VERSION ""

NS_ :

BS_:

BU_: CVC_I MHU TBOX FCAM_I MRR SRR_RL SRR_RR SRR_FL SRR_FR DUMMY_ECU ADCU_I AMP HUD

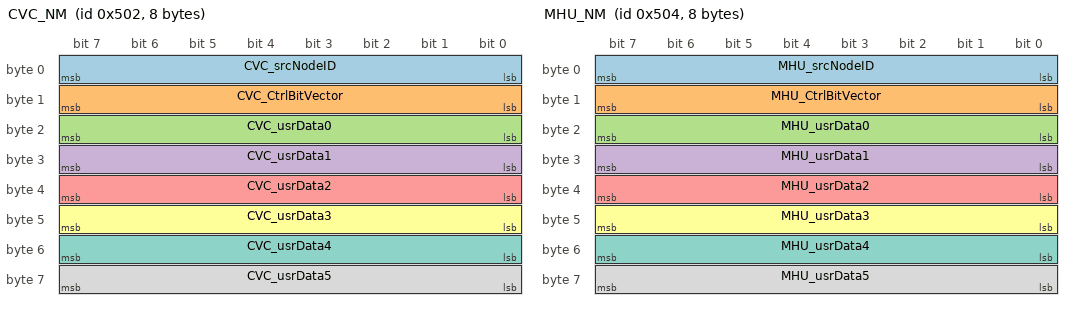
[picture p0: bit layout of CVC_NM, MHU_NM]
BO_ 1282 CVC_NM: 8 CVC_I
 SG_ CVC_srcNodeID : 7|8@0+ (1,0) [0|255] ""  MHU,TBOX,MRR,SRR_RL,SRR_RR,AMP
 SG_ CVC_CtrlBitVector : 15|8@0+ (1,0) [0|255] ""  MHU,TBOX,MRR,SRR_RL,SRR_RR,AMP
 SG_ CVC_usrData0 : 23|8@0+ (1,0) [0|255] ""  MHU,TBOX,MRR,SRR_RL,SRR_RR,AMP
 SG_ CVC_usrData1 : 31|8@0+ (1,0) [0|255] ""  MHU,TBOX,MRR,SRR_RL,SRR_RR,AMP
 SG_ CVC_usrData2 : 39|8@0+ (1,0) [0|255] ""  MHU,TBOX,MRR,SRR_RL,SRR_RR,AMP
 SG_ CVC_usrData3 : 47|8@0+ (1,0) [0|255] ""  MHU,TBOX,MRR,SRR_RL,SRR_RR,AMP
 SG_ CVC_usrData4 : 55|8@0+ (1,0) [0|255] ""  MHU,TBOX,MRR,SRR_RL,SRR_RR,AMP
 SG_ CVC_usrData5 : 63|8@0+ (1,0) [0|255] ""  MHU,TBOX,MRR,SRR_RL,SRR_RR,AMP

BO_ 1284 MHU_NM: 8 MHU
 SG_ MHU_srcNodeID : 7|8@0+ (1,0) [0|255] ""  CVC_I,TBOX,MRR,SRR_RL,SRR_RR,AMP
 SG_ MHU_CtrlBitVector : 15|8@0+ (1,0) [0|255] ""  CVC_I,TBOX,MRR,SRR_RL,SRR_RR,AMP
 SG_ MHU_usrData0 : 23|8@0+ (1,0) [0|255] ""  CVC_I,TBOX,MRR,SRR_RL,SRR_RR,AMP
 SG_ MHU_usrData1 : 31|8@0+ (1,0) [0|255] ""  CVC_I,TBOX,MRR,SRR_RL,SRR_RR,AMP
 SG_ MHU_usrData2 : 39|8@0+ (1,0) [0|255] ""  CVC_I,TBOX,MRR,SRR_RL,SRR_RR,AMP
 SG_ MHU_usrData3 : 47|8@0+ (1,0) [0|255] ""  CVC_I,TBOX,MRR,SRR_RL,SRR_RR,AMP
 SG_ MHU_usrData4 : 55|8@0+ (1,0) [0|255] ""  CVC_I,TBOX,MRR,SRR_RL,SRR_RR,AMP
 SG_ MHU_usrData5 : 63|8@0+ (1,0) [0|255] ""  CVC_I,TBOX,MRR,SRR_RL,SRR_RR,AMP

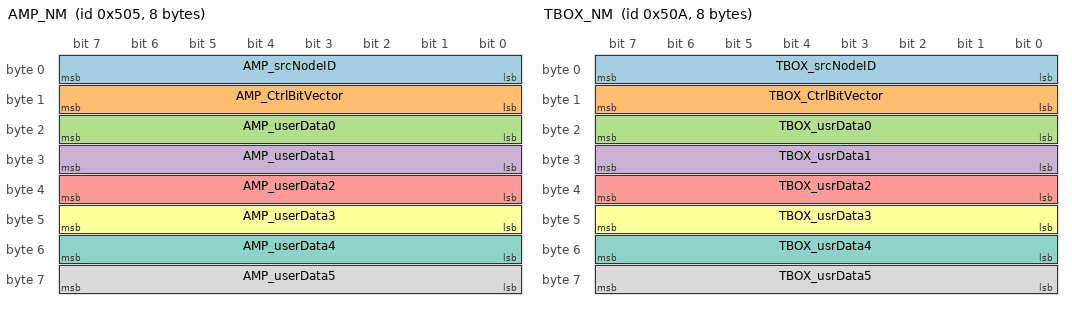
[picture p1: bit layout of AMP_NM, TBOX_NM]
BO_ 1285 AMP_NM: 8 AMP
 SG_ AMP_srcNodeID : 7|8@0+ (1,0) [0|255] ""  CVC_I,MHU,TBOX,MRR,SRR_RL,SRR_RR
 SG_ AMP_CtrlBitVector : 15|8@0+ (1,0) [0|255] ""  CVC_I,MHU,TBOX,MRR,SRR_RL,SRR_RR
 SG_ AMP_userData0 : 23|8@0+ (1,0) [0|255] ""  CVC_I,MHU,TBOX,MRR,SRR_RL,SRR_RR
 SG_ AMP_userData1 : 31|8@0+ (1,0) [0|255] ""  CVC_I,MHU,TBOX,MRR,SRR_RL,SRR_RR
 SG_ AMP_userData2 : 39|8@0+ (1,0) [0|255] ""  CVC_I,MHU,TBOX,MRR,SRR_RL,SRR_RR
 SG_ AMP_userData3 : 47|8@0+ (1,0) [0|255] ""  CVC_I,MHU,TBOX,MRR,SRR_RL,SRR_RR
 SG_ AMP_userData4 : 55|8@0+ (1,0) [0|255] ""  CVC_I,MHU,TBOX,MRR,SRR_RL,SRR_RR
 SG_ AMP_userData5 : 63|8@0+ (1,0) [0|255] ""  CVC_I,MHU,TBOX,MRR,SRR_RL,SRR_RR

BO_ 1290 TBOX_NM: 8 TBOX
 SG_ TBOX_srcNodeID : 7|8@0+ (1,0) [0|255] ""  CVC_I,MHU,MRR,SRR_RL,SRR_RR,AMP
 SG_ TBOX_CtrlBitVector : 15|8@0+ (1,0) [0|255] ""  CVC_I,MHU,MRR,SRR_RL,SRR_RR,AMP
 SG_ TBOX_usrData0 : 23|8@0+ (1,0) [0|255] ""  CVC_I,MHU,MRR,SRR_RL,SRR_RR,AMP
 SG_ TBOX_usrData1 : 31|8@0+ (1,0) [0|255] ""  CVC_I,MHU,MRR,SRR_RL,SRR_RR,AMP
 SG_ TBOX_usrData2 : 39|8@0+ (1,0) [0|255] ""  CVC_I,MHU,MRR,SRR_RL,SRR_RR,AMP
 SG_ TBOX_usrData3 : 47|8@0+ (1,0) [0|255] ""  CVC_I,MHU,MRR,SRR_RL,SRR_RR,AMP
 SG_ TBOX_usrData4 : 55|8@0+ (1,0) [0|255] ""  CVC_I,MHU,MRR,SRR_RL,SRR_RR,AMP
 SG_ TBOX_usrData5 : 63|8@0+ (1,0) [0|255] ""  CVC_I,MHU,MRR,SRR_RL,SRR_RR,AMP

BO_ 1674 TBOX_DiagReq: 64 CVC_I
 SG_ TBOX_DiagReqData0 : 7|8@0+ (1,0) [0|255] ""  TBOX
 SG_ TBOX_DiagReqData1 : 15|8@0+ (1,0) [0|255] ""  TBOX
 SG_ TBOX_DiagReqData2 : 23|8@0+ (1,0) [0|255] ""  TBOX
 SG_ TBOX_DiagReqData3 : 31|8@0+ (1,0) [0|255] ""  TBOX
 SG_ TBOX_DiagReqData4 : 39|8@0+ (1,0) [0|255] ""  TBOX
 SG_ TBOX_DiagReqData5 : 47|8@0+ (1,0) [0|255] ""  TBOX
 SG_ TBOX_DiagReqData6 : 55|8@0+ (1,0) [0|255] ""  TBOX
 SG_ TBOX_DiagReqData7 : 63|8@0+ (1,0) [0|255] ""  TBOX
 SG_ TBOX_DiagReqData8 : 71|8@0+ (1,0) [0|255] ""  TBOX
 SG_ TBOX_DiagReqData9 : 79|8@0+ (1,0) [0|255] ""  TBOX
 SG_ TBOX_DiagReqData10 : 87|8@0+ (1,0) [0|255] ""  TBOX
 SG_ TBOX_DiagReqData11 : 95|8@0+ (1,0) [0|255] ""  TBOX
 SG_ TBOX_DiagReqData12 : 103|8@0+ (1,0) [0|255] ""  TBOX
 SG_ TBOX_DiagReqData13 : 111|8@0+ (1,0) [0|255] ""  TBOX
 SG_ TBOX_DiagReqData14 : 119|8@0+ (1,0) [0|255] ""  TBOX
 SG_ TBOX_DiagReqData15 : 127|8@0+ (1,0) [0|255] ""  TBOX
 SG_ TBOX_DiagReqData16 : 135|8@0+ (1,0) [0|255] ""  TBOX
 SG_ TBOX_DiagReqData17 : 143|8@0+ (1,0) [0|255] ""  TBOX
 SG_ TBOX_DiagReqData18 : 151|8@0+ (1,0) [0|255] ""  TBOX
 SG_ TBOX_DiagReqData19 : 159|8@0+ (1,0) [0|255] ""  TBOX
 SG_ TBOX_DiagReqData20 : 167|8@0+ (1,0) [0|255] ""  TBOX
 SG_ TBOX_DiagReqData21 : 175|8@0+ (1,0) [0|255] ""  TBOX
 SG_ TBOX_DiagReqData22 : 183|8@0+ (1,0) [0|255] ""  TBOX
 SG_ TBOX_DiagReqData23 : 191|8@0+ (1,0) [0|255] ""  TBOX
 SG_ TBOX_DiagReqData24 : 199|8@0+ (1,0) [0|255] ""  TBOX
 SG_ TBOX_DiagReqData25 : 207|8@0+ (1,0) [0|255] ""  TBOX
 SG_ TBOX_DiagReqData26 : 215|8@0+ (1,0) [0|255] ""  TBOX
 SG_ TBOX_DiagReqData27 : 223|8@0+ (1,0) [0|255] ""  TBOX
 SG_ TBOX_DiagReqData28 : 231|8@0+ (1,0) [0|255] ""  TBOX
 SG_ TBOX_DiagReqData29 : 239|8@0+ (1,0) [0|255] ""  TBOX
 SG_ TBOX_DiagReqData30 : 247|8@0+ (1,0) [0|255] ""  TBOX
 SG_ TBOX_DiagReqData31 : 255|8@0+ (1,0) [0|255] ""  TBOX
 SG_ TBOX_DiagReqData32 : 263|8@0+ (1,0) [0|255] ""  TBOX
 SG_ TBOX_DiagReqData33 : 271|8@0+ (1,0) [0|255] ""  TBOX
 SG_ TBOX_DiagReqData34 : 279|8@0+ (1,0) [0|255] ""  TBOX
 SG_ TBOX_DiagReqData35 : 287|8@0+ (1,0) [0|255] ""  TBOX
 SG_ TBOX_DiagReqData36 : 295|8@0+ (1,0) [0|255] ""  TBOX
 SG_ TBOX_DiagReqData37 : 303|8@0+ (1,0) [0|255] ""  TBOX
 SG_ TBOX_DiagReqData38 : 311|8@0+ (1,0) [0|255] ""  TBOX
 SG_ TBOX_DiagReqData39 : 319|8@0+ (1,0) [0|255] ""  TBOX
 SG_ TBOX_DiagReqData40 : 327|8@0+ (1,0) [0|255] ""  TBOX
 SG_ TBOX_DiagReqData41 : 335|8@0+ (1,0) [0|255] ""  TBOX
 SG_ TBOX_DiagReqData42 : 343|8@0+ (1,0) [0|255] ""  TBOX
 SG_ TBOX_DiagReqData43 : 351|8@0+ (1,0) [0|255] ""  TBOX
 SG_ TBOX_DiagReqData44 : 359|8@0+ (1,0) [0|255] ""  TBOX
 SG_ TBOX_DiagReqData45 : 367|8@0+ (1,0) [0|255] ""  TBOX
 SG_ TBOX_DiagReqData46 : 375|8@0+ (1,0) [0|255] ""  TBOX
 SG_ TBOX_DiagReqData47 : 383|8@0+ (1,0) [0|255] ""  TBOX
 SG_ TBOX_DiagReqData48 : 391|8@0+ (1,0) [0|255] ""  TBOX
 SG_ TBOX_DiagReqData49 : 399|8@0+ (1,0) [0|255] ""  TBOX
 SG_ TBOX_DiagReqData50 : 407|8@0+ (1,0) [0|255] ""  TBOX
 SG_ TBOX_DiagReqData51 : 415|8@0+ (1,0) [0|255] ""  TBOX
 SG_ TBOX_DiagReqData52 : 423|8@0+ (1,0) [0|255] ""  TBOX
 SG_ TBOX_DiagReqData53 : 431|8@0+ (1,0) [0|255] ""  TBOX
 SG_ TBOX_DiagReqData54 : 439|8@0+ (1,0) [0|255] ""  TBOX
 SG_ TBOX_DiagReqData55 : 447|8@0+ (1,0) [0|255] ""  TBOX
 SG_ TBOX_DiagReqData56 : 455|8@0+ (1,0) [0|255] ""  TBOX
 SG_ TBOX_DiagReqData57 : 463|8@0+ (1,0) [0|255] ""  TBOX
 SG_ TBOX_DiagReqData58 : 471|8@0+ (1,0) [0|255] ""  TBOX
 SG_ TBOX_DiagReqData59 : 479|8@0+ (1,0) [0|255] ""  TBOX
 SG_ TBOX_DiagReqData60 : 487|8@0+ (1,0) [0|255] ""  TBOX
 SG_ TBOX_DiagReqData61 : 495|8@0+ (1,0) [0|255] ""  TBOX
 SG_ TBOX_DiagReqData62 : 503|8@0+ (1,0) [0|255] ""  TBOX
 SG_ TBOX_DiagReqData63 : 511|8@0+ (1,0) [0|255] ""  TBOX

BO_ 1546 TBOX_DiagResp: 64 TBOX
 SG_ TBOX_DiagRespData0 : 7|8@0+ (1,0) [0|255] ""  CVC_I
 SG_ TBOX_DiagRespData1 : 15|8@0+ (1,0) [0|255] ""  CVC_I
 SG_ TBOX_DiagRespData2 : 23|8@0+ (1,0) [0|255] ""  CVC_I
 SG_ TBOX_DiagRespData3 : 31|8@0+ (1,0) [0|255] ""  CVC_I
 SG_ TBOX_DiagRespData4 : 39|8@0+ (1,0) [0|255] ""  CVC_I
 SG_ TBOX_DiagRespData5 : 47|8@0+ (1,0) [0|255] ""  CVC_I
 SG_ TBOX_DiagRespData6 : 55|8@0+ (1,0) [0|255] ""  CVC_I
 SG_ TBOX_DiagRespData7 : 63|8@0+ (1,0) [0|255] ""  CVC_I
 SG_ TBOX_DiagRespData8 : 71|8@0+ (1,0) [0|255] ""  CVC_I
 SG_ TBOX_DiagRespData9 : 79|8@0+ (1,0) [0|255] ""  CVC_I
 SG_ TBOX_DiagRespData10 : 87|8@0+ (1,0) [0|255] ""  CVC_I
 SG_ TBOX_DiagRespData11 : 95|8@0+ (1,0) [0|255] ""  CVC_I
 SG_ TBOX_DiagRespData12 : 103|8@0+ (1,0) [0|255] ""  CVC_I
 SG_ TBOX_DiagRespData13 : 111|8@0+ (1,0) [0|255] ""  CVC_I
 SG_ TBOX_DiagRespData14 : 119|8@0+ (1,0) [0|255] ""  CVC_I
 SG_ TBOX_DiagRespData15 : 127|8@0+ (1,0) [0|255] ""  CVC_I
 SG_ TBOX_DiagRespData16 : 135|8@0+ (1,0) [0|255] ""  CVC_I
 SG_ TBOX_DiagRespData17 : 143|8@0+ (1,0) [0|255] ""  CVC_I
 SG_ TBOX_DiagRespData18 : 151|8@0+ (1,0) [0|255] ""  CVC_I
 SG_ TBOX_DiagRespData19 : 159|8@0+ (1,0) [0|255] ""  CVC_I
 SG_ TBOX_DiagRespData20 : 167|8@0+ (1,0) [0|255] ""  CVC_I
 SG_ TBOX_DiagRespData21 : 175|8@0+ (1,0) [0|255] ""  CVC_I
 SG_ TBOX_DiagRespData22 : 183|8@0+ (1,0) [0|255] ""  CVC_I
 SG_ TBOX_DiagRespData23 : 191|8@0+ (1,0) [0|255] ""  CVC_I
 SG_ TBOX_DiagRespData24 : 199|8@0+ (1,0) [0|255] ""  CVC_I
 SG_ TBOX_DiagRespData25 : 207|8@0+ (1,0) [0|255] ""  CVC_I
 SG_ TBOX_DiagRespData26 : 215|8@0+ (1,0) [0|255] ""  CVC_I
 SG_ TBOX_DiagRespData27 : 223|8@0+ (1,0) [0|255] ""  CVC_I
 SG_ TBOX_DiagRespData28 : 231|8@0+ (1,0) [0|255] ""  CVC_I
 SG_ TBOX_DiagRespData29 : 239|8@0+ (1,0) [0|255] ""  CVC_I
 SG_ TBOX_DiagRespData30 : 247|8@0+ (1,0) [0|255] ""  CVC_I
 SG_ TBOX_DiagRespData31 : 255|8@0+ (1,0) [0|255] ""  CVC_I
 SG_ TBOX_DiagRespData32 : 263|8@0+ (1,0) [0|255] ""  CVC_I
 SG_ TBOX_DiagRespData33 : 271|8@0+ (1,0) [0|255] ""  CVC_I
 SG_ TBOX_DiagRespData34 : 279|8@0+ (1,0) [0|255] ""  CVC_I
 SG_ TBOX_DiagRespData35 : 287|8@0+ (1,0) [0|255] ""  CVC_I
 SG_ TBOX_DiagRespData36 : 295|8@0+ (1,0) [0|255] ""  CVC_I
 SG_ TBOX_DiagRespData37 : 303|8@0+ (1,0) [0|255] ""  CVC_I
 SG_ TBOX_DiagRespData38 : 311|8@0+ (1,0) [0|255] ""  CVC_I
 SG_ TBOX_DiagRespData39 : 319|8@0+ (1,0) [0|255] ""  CVC_I
 SG_ TBOX_DiagRespData40 : 327|8@0+ (1,0) [0|255] ""  CVC_I
 SG_ TBOX_DiagRespData41 : 335|8@0+ (1,0) [0|255] ""  CVC_I
 SG_ TBOX_DiagRespData42 : 343|8@0+ (1,0) [0|255] ""  CVC_I
 SG_ TBOX_DiagRespData43 : 351|8@0+ (1,0) [0|255] ""  CVC_I
 SG_ TBOX_DiagRespData44 : 359|8@0+ (1,0) [0|255] ""  CVC_I
 SG_ TBOX_DiagRespData45 : 367|8@0+ (1,0) [0|255] ""  CVC_I
 SG_ TBOX_DiagRespData46 : 375|8@0+ (1,0) [0|255] ""  CVC_I
 SG_ TBOX_DiagRespData47 : 383|8@0+ (1,0) [0|255] ""  CVC_I
 SG_ TBOX_DiagRespData48 : 391|8@0+ (1,0) [0|255] ""  CVC_I
 SG_ TBOX_DiagRespData49 : 399|8@0+ (1,0) [0|255] ""  CVC_I
 SG_ TBOX_DiagRespData50 : 407|8@0+ (1,0) [0|255] ""  CVC_I
 SG_ TBOX_DiagRespData51 : 415|8@0+ (1,0) [0|255] ""  CVC_I
 SG_ TBOX_DiagRespData52 : 423|8@0+ (1,0) [0|255] ""  CVC_I
 SG_ TBOX_DiagRespData53 : 431|8@0+ (1,0) [0|255] ""  CVC_I
 SG_ TBOX_DiagRespData54 : 439|8@0+ (1,0) [0|255] ""  CVC_I
 SG_ TBOX_DiagRespData55 : 447|8@0+ (1,0) [0|255] ""  CVC_I
 SG_ TBOX_DiagRespData56 : 455|8@0+ (1,0) [0|255] ""  CVC_I
 SG_ TBOX_DiagRespData57 : 463|8@0+ (1,0) [0|255] ""  CVC_I
 SG_ TBOX_DiagRespData58 : 471|8@0+ (1,0) [0|255] ""  CVC_I
 SG_ TBOX_DiagRespData59 : 479|8@0+ (1,0) [0|255] ""  CVC_I
 SG_ TBOX_DiagRespData60 : 487|8@0+ (1,0) [0|255] ""  CVC_I
 SG_ TBOX_DiagRespData61 : 495|8@0+ (1,0) [0|255] ""  CVC_I
 SG_ TBOX_DiagRespData62 : 503|8@0+ (1,0) [0|255] ""  CVC_I
 SG_ TBOX_DiagRespData63 : 511|8@0+ (1,0) [0|255] ""  CVC_I

BO_ 1541 AMP_DiagResp: 64 AMP
 SG_ AMP_DiagRespData0 : 7|8@0+ (1,0) [0|255] ""  CVC_I
 SG_ AMP_DiagRespData1 : 15|8@0+ (1,0) [0|255] ""  CVC_I
 SG_ AMP_DiagRespData2 : 23|8@0+ (1,0) [0|255] ""  CVC_I
 SG_ AMP_DiagRespData3 : 31|8@0+ (1,0) [0|255] ""  CVC_I
 SG_ AMP_DiagRespData4 : 39|8@0+ (1,0) [0|255] ""  CVC_I
 SG_ AMP_DiagRespData5 : 47|8@0+ (1,0) [0|255] ""  CVC_I
 SG_ AMP_DiagRespData6 : 55|8@0+ (1,0) [0|255] ""  CVC_I
 SG_ AMP_DiagRespData7 : 63|8@0+ (1,0) [0|255] ""  CVC_I
 SG_ AMP_DiagRespData8 : 71|8@0+ (1,0) [0|255] ""  CVC_I
 SG_ AMP_DiagRespData9 : 79|8@0+ (1,0) [0|255] ""  CVC_I
 SG_ AMP_DiagRespData10 : 87|8@0+ (1,0) [0|255] ""  CVC_I
 SG_ AMP_DiagRespData11 : 95|8@0+ (1,0) [0|255] ""  CVC_I
 SG_ AMP_DiagRespData12 : 103|8@0+ (1,0) [0|255] ""  CVC_I
 SG_ AMP_DiagRespData13 : 111|8@0+ (1,0) [0|255] ""  CVC_I
 SG_ AMP_DiagRespData14 : 119|8@0+ (1,0) [0|255] ""  CVC_I
 SG_ AMP_DiagRespData15 : 127|8@0+ (1,0) [0|255] ""  CVC_I
 SG_ AMP_DiagRespData16 : 135|8@0+ (1,0) [0|255] ""  CVC_I
 SG_ AMP_DiagRespData17 : 143|8@0+ (1,0) [0|255] ""  CVC_I
 SG_ AMP_DiagRespData18 : 151|8@0+ (1,0) [0|255] ""  CVC_I
 SG_ AMP_DiagRespData19 : 159|8@0+ (1,0) [0|255] ""  CVC_I
 SG_ AMP_DiagRespData20 : 167|8@0+ (1,0) [0|255] ""  CVC_I
 SG_ AMP_DiagRespData21 : 175|8@0+ (1,0) [0|255] ""  CVC_I
 SG_ AMP_DiagRespData22 : 183|8@0+ (1,0) [0|255] ""  CVC_I
 SG_ AMP_DiagRespData23 : 191|8@0+ (1,0) [0|255] ""  CVC_I
 SG_ AMP_DiagRespData24 : 199|8@0+ (1,0) [0|255] ""  CVC_I
 SG_ AMP_DiagRespData25 : 207|8@0+ (1,0) [0|255] ""  CVC_I
 SG_ AMP_DiagRespData26 : 215|8@0+ (1,0) [0|255] ""  CVC_I
 SG_ AMP_DiagRespData27 : 223|8@0+ (1,0) [0|255] ""  CVC_I
 SG_ AMP_DiagRespData28 : 231|8@0+ (1,0) [0|255] ""  CVC_I
 SG_ AMP_DiagRespData29 : 239|8@0+ (1,0) [0|255] ""  CVC_I
 SG_ AMP_DiagRespData30 : 247|8@0+ (1,0) [0|255] ""  CVC_I
 SG_ AMP_DiagRespData31 : 255|8@0+ (1,0) [0|255] ""  CVC_I
 SG_ AMP_DiagRespData32 : 263|8@0+ (1,0) [0|255] ""  CVC_I
 SG_ AMP_DiagRespData33 : 271|8@0+ (1,0) [0|255] ""  CVC_I
 SG_ AMP_DiagRespData34 : 279|8@0+ (1,0) [0|255] ""  CVC_I
 SG_ AMP_DiagRespData35 : 287|8@0+ (1,0) [0|255] ""  CVC_I
 SG_ AMP_DiagRespData36 : 295|8@0+ (1,0) [0|255] ""  CVC_I
 SG_ AMP_DiagRespData37 : 303|8@0+ (1,0) [0|255] ""  CVC_I
 SG_ AMP_DiagRespData38 : 311|8@0+ (1,0) [0|255] ""  CVC_I
 SG_ AMP_DiagRespData39 : 319|8@0+ (1,0) [0|255] ""  CVC_I
 SG_ AMP_DiagRespData40 : 327|8@0+ (1,0) [0|255] ""  CVC_I
 SG_ AMP_DiagRespData41 : 335|8@0+ (1,0) [0|255] ""  CVC_I
 SG_ AMP_DiagRespData42 : 343|8@0+ (1,0) [0|255] ""  CVC_I
 SG_ AMP_DiagRespData43 : 351|8@0+ (1,0) [0|255] ""  CVC_I
 SG_ AMP_DiagRespData44 : 359|8@0+ (1,0) [0|255] ""  CVC_I
 SG_ AMP_DiagRespData45 : 367|8@0+ (1,0) [0|255] ""  CVC_I
 SG_ AMP_DiagRespData46 : 375|8@0+ (1,0) [0|255] ""  CVC_I
 SG_ AMP_DiagRespData47 : 383|8@0+ (1,0) [0|255] ""  CVC_I
 SG_ AMP_DiagRespData48 : 391|8@0+ (1,0) [0|255] ""  CVC_I
 SG_ AMP_DiagRespData49 : 399|8@0+ (1,0) [0|255] ""  CVC_I
 SG_ AMP_DiagRespData50 : 407|8@0+ (1,0) [0|255] ""  CVC_I
 SG_ AMP_DiagRespData51 : 415|8@0+ (1,0) [0|255] ""  CVC_I
 SG_ AMP_DiagRespData52 : 423|8@0+ (1,0) [0|255] ""  CVC_I
 SG_ AMP_DiagRespData53 : 431|8@0+ (1,0) [0|255] ""  CVC_I
 SG_ AMP_DiagRespData54 : 439|8@0+ (1,0) [0|255] ""  CVC_I
 SG_ AMP_DiagRespData55 : 447|8@0+ (1,0) [0|255] ""  CVC_I
 SG_ AMP_DiagRespData56 : 455|8@0+ (1,0) [0|255] ""  CVC_I
 SG_ AMP_DiagRespData57 : 463|8@0+ (1,0) [0|255] ""  CVC_I
 SG_ AMP_DiagRespData58 : 471|8@0+ (1,0) [0|255] ""  CVC_I
 SG_ AMP_DiagRespData59 : 479|8@0+ (1,0) [0|255] ""  CVC_I
 SG_ AMP_DiagRespData60 : 487|8@0+ (1,0) [0|255] ""  CVC_I
 SG_ AMP_DiagRespData61 : 495|8@0+ (1,0) [0|255] ""  CVC_I
 SG_ AMP_DiagRespData62 : 503|8@0+ (1,0) [0|255] ""  CVC_I
 SG_ AMP_DiagRespData63 : 511|8@0+ (1,0) [0|255] ""  CVC_I

BO_ 1669 AMP_DiagReq: 64 CVC_I
 SG_ AMP_DiagReqData0 : 7|8@0+ (1,0) [0|255] ""  AMP
 SG_ AMP_DiagReqData1 : 15|8@0+ (1,0) [0|255] ""  AMP
 SG_ AMP_DiagReqData2 : 23|8@0+ (1,0) [0|255] ""  AMP
 SG_ AMP_DiagReqData3 : 31|8@0+ (1,0) [0|255] ""  AMP
 SG_ AMP_DiagReqData4 : 39|8@0+ (1,0) [0|255] ""  AMP
 SG_ AMP_DiagReqData5 : 47|8@0+ (1,0) [0|255] ""  AMP
 SG_ AMP_DiagReqData6 : 55|8@0+ (1,0) [0|255] ""  AMP
 SG_ AMP_DiagReqData7 : 63|8@0+ (1,0) [0|255] ""  AMP
 SG_ AMP_DiagReqData8 : 71|8@0+ (1,0) [0|255] ""  AMP
 SG_ AMP_DiagReqData9 : 79|8@0+ (1,0) [0|255] ""  AMP
 SG_ AMP_DiagReqData10 : 87|8@0+ (1,0) [0|255] ""  AMP
 SG_ AMP_DiagReqData11 : 95|8@0+ (1,0) [0|255] ""  AMP
 SG_ AMP_DiagReqData12 : 103|8@0+ (1,0) [0|255] ""  AMP
 SG_ AMP_DiagReqData13 : 111|8@0+ (1,0) [0|255] ""  AMP
 SG_ AMP_DiagReqData14 : 119|8@0+ (1,0) [0|255] ""  AMP
 SG_ AMP_DiagReqData15 : 127|8@0+ (1,0) [0|255] ""  AMP
 SG_ AMP_DiagReqData16 : 135|8@0+ (1,0) [0|255] ""  AMP
 SG_ AMP_DiagReqData17 : 143|8@0+ (1,0) [0|255] ""  AMP
 SG_ AMP_DiagReqData18 : 151|8@0+ (1,0) [0|255] ""  AMP
 SG_ AMP_DiagReqData19 : 159|8@0+ (1,0) [0|255] ""  AMP
 SG_ AMP_DiagReqData20 : 167|8@0+ (1,0) [0|255] ""  AMP
 SG_ AMP_DiagReqData21 : 175|8@0+ (1,0) [0|255] ""  AMP
 SG_ AMP_DiagReqData22 : 183|8@0+ (1,0) [0|255] ""  AMP
 SG_ AMP_DiagReqData23 : 191|8@0+ (1,0) [0|255] ""  AMP
 SG_ AMP_DiagReqData24 : 199|8@0+ (1,0) [0|255] ""  AMP
 SG_ AMP_DiagReqData25 : 207|8@0+ (1,0) [0|255] ""  AMP
 SG_ AMP_DiagReqData26 : 215|8@0+ (1,0) [0|255] ""  AMP
 SG_ AMP_DiagReqData27 : 223|8@0+ (1,0) [0|255] ""  AMP
 SG_ AMP_DiagReqData28 : 231|8@0+ (1,0) [0|255] ""  AMP
 SG_ AMP_DiagReqData29 : 239|8@0+ (1,0) [0|255] ""  AMP
 SG_ AMP_DiagReqData30 : 247|8@0+ (1,0) [0|255] ""  AMP
 SG_ AMP_DiagReqData31 : 255|8@0+ (1,0) [0|255] ""  AMP
 SG_ AMP_DiagReqData32 : 263|8@0+ (1,0) [0|255] ""  AMP
 SG_ AMP_DiagReqData33 : 271|8@0+ (1,0) [0|255] ""  AMP
 SG_ AMP_DiagReqData34 : 279|8@0+ (1,0) [0|255] ""  AMP
 SG_ AMP_DiagReqData35 : 287|8@0+ (1,0) [0|255] ""  AMP
 SG_ AMP_DiagReqData36 : 295|8@0+ (1,0) [0|255] ""  AMP
 SG_ AMP_DiagReqData37 : 303|8@0+ (1,0) [0|255] ""  AMP
 SG_ AMP_DiagReqData38 : 311|8@0+ (1,0) [0|255] ""  AMP
 SG_ AMP_DiagReqData39 : 319|8@0+ (1,0) [0|255] ""  AMP
 SG_ AMP_DiagReqData40 : 327|8@0+ (1,0) [0|255] ""  AMP
 SG_ AMP_DiagReqData41 : 335|8@0+ (1,0) [0|255] ""  AMP
 SG_ AMP_DiagReqData42 : 343|8@0+ (1,0) [0|255] ""  AMP
 SG_ AMP_DiagReqData43 : 351|8@0+ (1,0) [0|255] ""  AMP
 SG_ AMP_DiagReqData44 : 359|8@0+ (1,0) [0|255] ""  AMP
 SG_ AMP_DiagReqData45 : 367|8@0+ (1,0) [0|255] ""  AMP
 SG_ AMP_DiagReqData46 : 375|8@0+ (1,0) [0|255] ""  AMP
 SG_ AMP_DiagReqData47 : 383|8@0+ (1,0) [0|255] ""  AMP
 SG_ AMP_DiagReqData48 : 391|8@0+ (1,0) [0|255] ""  AMP
 SG_ AMP_DiagReqData49 : 399|8@0+ (1,0) [0|255] ""  AMP
 SG_ AMP_DiagReqData50 : 407|8@0+ (1,0) [0|255] ""  AMP
 SG_ AMP_DiagReqData51 : 415|8@0+ (1,0) [0|255] ""  AMP
 SG_ AMP_DiagReqData52 : 423|8@0+ (1,0) [0|255] ""  AMP
 SG_ AMP_DiagReqData53 : 431|8@0+ (1,0) [0|255] ""  AMP
 SG_ AMP_DiagReqData54 : 439|8@0+ (1,0) [0|255] ""  AMP
 SG_ AMP_DiagReqData55 : 447|8@0+ (1,0) [0|255] ""  AMP
 SG_ AMP_DiagReqData56 : 455|8@0+ (1,0) [0|255] ""  AMP
 SG_ AMP_DiagReqData57 : 463|8@0+ (1,0) [0|255] ""  AMP
 SG_ AMP_DiagReqData58 : 471|8@0+ (1,0) [0|255] ""  AMP
 SG_ AMP_DiagReqData59 : 479|8@0+ (1,0) [0|255] ""  AMP
 SG_ AMP_DiagReqData60 : 487|8@0+ (1,0) [0|255] ""  AMP
 SG_ AMP_DiagReqData61 : 495|8@0+ (1,0) [0|255] ""  AMP
 SG_ AMP_DiagReqData62 : 503|8@0+ (1,0) [0|255] ""  AMP
 SG_ AMP_DiagReqData63 : 511|8@0+ (1,0) [0|255] ""  AMP

BO_ 1549 HUD_DiagResp: 64 HUD
 SG_ HUD_DiagRespData0 : 7|8@0+ (1,0) [0|255] ""  CVC_I
 SG_ HUD_DiagRespData1 : 15|8@0+ (1,0) [0|255] ""  CVC_I
 SG_ HUD_DiagRespData2 : 23|8@0+ (1,0) [0|255] ""  CVC_I
 SG_ HUD_DiagRespData3 : 31|8@0+ (1,0) [0|255] ""  CVC_I
 SG_ HUD_DiagRespData4 : 39|8@0+ (1,0) [0|255] ""  CVC_I
 SG_ HUD_DiagRespData5 : 47|8@0+ (1,0) [0|255] ""  CVC_I
 SG_ HUD_DiagRespData6 : 55|8@0+ (1,0) [0|255] ""  CVC_I
 SG_ HUD_DiagRespData7 : 63|8@0+ (1,0) [0|255] ""  CVC_I
 SG_ HUD_DiagRespData8 : 71|8@0+ (1,0) [0|255] ""  CVC_I
 SG_ HUD_DiagRespData9 : 79|8@0+ (1,0) [0|255] ""  CVC_I
 SG_ HUD_DiagRespData10 : 87|8@0+ (1,0) [0|255] ""  CVC_I
 SG_ HUD_DiagRespData11 : 95|8@0+ (1,0) [0|255] ""  CVC_I
 SG_ HUD_DiagRespData12 : 103|8@0+ (1,0) [0|255] ""  CVC_I
 SG_ HUD_DiagRespData13 : 111|8@0+ (1,0) [0|255] ""  CVC_I
 SG_ HUD_DiagRespData14 : 119|8@0+ (1,0) [0|255] ""  CVC_I
 SG_ HUD_DiagRespData15 : 127|8@0+ (1,0) [0|255] ""  CVC_I
 SG_ HUD_DiagRespData16 : 135|8@0+ (1,0) [0|255] ""  CVC_I
 SG_ HUD_DiagRespData17 : 143|8@0+ (1,0) [0|255] ""  CVC_I
 SG_ HUD_DiagRespData18 : 151|8@0+ (1,0) [0|255] ""  CVC_I
 SG_ HUD_DiagRespData19 : 159|8@0+ (1,0) [0|255] ""  CVC_I
 SG_ HUD_DiagRespData20 : 167|8@0+ (1,0) [0|255] ""  CVC_I
 SG_ HUD_DiagRespData21 : 175|8@0+ (1,0) [0|255] ""  CVC_I
 SG_ HUD_DiagRespData22 : 183|8@0+ (1,0) [0|255] ""  CVC_I
 SG_ HUD_DiagRespData23 : 191|8@0+ (1,0) [0|255] ""  CVC_I
 SG_ HUD_DiagRespData24 : 199|8@0+ (1,0) [0|255] ""  CVC_I
 SG_ HUD_DiagRespData25 : 207|8@0+ (1,0) [0|255] ""  CVC_I
 SG_ HUD_DiagRespData26 : 215|8@0+ (1,0) [0|255] ""  CVC_I
 SG_ HUD_DiagRespData27 : 223|8@0+ (1,0) [0|255] ""  CVC_I
 SG_ HUD_DiagRespData28 : 231|8@0+ (1,0) [0|255] ""  CVC_I
 SG_ HUD_DiagRespData29 : 239|8@0+ (1,0) [0|255] ""  CVC_I
 SG_ HUD_DiagRespData30 : 247|8@0+ (1,0) [0|255] ""  CVC_I
 SG_ HUD_DiagRespData31 : 255|8@0+ (1,0) [0|255] ""  CVC_I
 SG_ HUD_DiagRespData32 : 263|8@0+ (1,0) [0|255] ""  CVC_I
 SG_ HUD_DiagRespData33 : 271|8@0+ (1,0) [0|255] ""  CVC_I
 SG_ HUD_DiagRespData34 : 279|8@0+ (1,0) [0|255] ""  CVC_I
 SG_ HUD_DiagRespData35 : 287|8@0+ (1,0) [0|255] ""  CVC_I
 SG_ HUD_DiagRespData36 : 295|8@0+ (1,0) [0|255] ""  CVC_I
 SG_ HUD_DiagRespData37 : 303|8@0+ (1,0) [0|255] ""  CVC_I
 SG_ HUD_DiagRespData38 : 311|8@0+ (1,0) [0|255] ""  CVC_I
 SG_ HUD_DiagRespData39 : 319|8@0+ (1,0) [0|255] ""  CVC_I
 SG_ HUD_DiagRespData40 : 327|8@0+ (1,0) [0|255] ""  CVC_I
 SG_ HUD_DiagRespData41 : 335|8@0+ (1,0) [0|255] ""  CVC_I
 SG_ HUD_DiagRespData42 : 343|8@0+ (1,0) [0|255] ""  CVC_I
 SG_ HUD_DiagRespData43 : 351|8@0+ (1,0) [0|255] ""  CVC_I
 SG_ HUD_DiagRespData44 : 359|8@0+ (1,0) [0|255] ""  CVC_I
 SG_ HUD_DiagRespData45 : 367|8@0+ (1,0) [0|255] ""  CVC_I
 SG_ HUD_DiagRespData46 : 375|8@0+ (1,0) [0|255] ""  CVC_I
 SG_ HUD_DiagRespData47 : 383|8@0+ (1,0) [0|255] ""  CVC_I
 SG_ HUD_DiagRespData48 : 391|8@0+ (1,0) [0|255] ""  CVC_I
 SG_ HUD_DiagRespData49 : 399|8@0+ (1,0) [0|255] ""  CVC_I
 SG_ HUD_DiagRespData50 : 407|8@0+ (1,0) [0|255] ""  CVC_I
 SG_ HUD_DiagRespData51 : 415|8@0+ (1,0) [0|255] ""  CVC_I
 SG_ HUD_DiagRespData52 : 423|8@0+ (1,0) [0|255] ""  CVC_I
 SG_ HUD_DiagRespData53 : 431|8@0+ (1,0) [0|255] ""  CVC_I
 SG_ HUD_DiagRespData54 : 439|8@0+ (1,0) [0|255] ""  CVC_I
 SG_ HUD_DiagRespData55 : 447|8@0+ (1,0) [0|255] ""  CVC_I
 SG_ HUD_DiagRespData56 : 455|8@0+ (1,0) [0|255] ""  CVC_I
 SG_ HUD_DiagRespData57 : 463|8@0+ (1,0) [0|255] ""  CVC_I
 SG_ HUD_DiagRespData58 : 471|8@0+ (1,0) [0|255] ""  CVC_I
 SG_ HUD_DiagRespData59 : 479|8@0+ (1,0) [0|255] ""  CVC_I
 SG_ HUD_DiagRespData60 : 487|8@0+ (1,0) [0|255] ""  CVC_I
 SG_ HUD_DiagRespData61 : 495|8@0+ (1,0) [0|255] ""  CVC_I
 SG_ HUD_DiagRespData62 : 503|8@0+ (1,0) [0|255] ""  CVC_I
 SG_ HUD_DiagRespData63 : 511|8@0+ (1,0) [0|255] ""  CVC_I

BO_ 1677 HUD_DiagReq: 64 CVC_I
 SG_ HUD_DiagReqData0 : 7|8@0+ (1,0) [0|255] ""  HUD
 SG_ HUD_DiagReqData1 : 15|8@0+ (1,0) [0|255] ""  HUD
 SG_ HUD_DiagReqData2 : 23|8@0+ (1,0) [0|255] ""  HUD
 SG_ HUD_DiagReqData3 : 31|8@0+ (1,0) [0|255] ""  HUD
 SG_ HUD_DiagReqData4 : 39|8@0+ (1,0) [0|255] ""  HUD
 SG_ HUD_DiagReqData5 : 47|8@0+ (1,0) [0|255] ""  HUD
 SG_ HUD_DiagReqData6 : 55|8@0+ (1,0) [0|255] ""  HUD
 SG_ HUD_DiagReqData7 : 63|8@0+ (1,0) [0|255] ""  HUD
 SG_ HUD_DiagReqData8 : 71|8@0+ (1,0) [0|255] ""  HUD
 SG_ HUD_DiagReqData9 : 79|8@0+ (1,0) [0|255] ""  HUD
 SG_ HUD_DiagReqData10 : 87|8@0+ (1,0) [0|255] ""  HUD
 SG_ HUD_DiagReqData11 : 95|8@0+ (1,0) [0|255] ""  HUD
 SG_ HUD_DiagReqData12 : 103|8@0+ (1,0) [0|255] ""  HUD
 SG_ HUD_DiagReqData13 : 111|8@0+ (1,0) [0|255] ""  HUD
 SG_ HUD_DiagReqData14 : 119|8@0+ (1,0) [0|255] ""  HUD
 SG_ HUD_DiagReqData15 : 127|8@0+ (1,0) [0|255] ""  HUD
 SG_ HUD_DiagReqData16 : 135|8@0+ (1,0) [0|255] ""  HUD
 SG_ HUD_DiagReqData17 : 143|8@0+ (1,0) [0|255] ""  HUD
 SG_ HUD_DiagReqData18 : 151|8@0+ (1,0) [0|255] ""  HUD
 SG_ HUD_DiagReqData19 : 159|8@0+ (1,0) [0|255] ""  HUD
 SG_ HUD_DiagReqData20 : 167|8@0+ (1,0) [0|255] ""  HUD
 SG_ HUD_DiagReqData21 : 175|8@0+ (1,0) [0|255] ""  HUD
 SG_ HUD_DiagReqData22 : 183|8@0+ (1,0) [0|255] ""  HUD
 SG_ HUD_DiagReqData23 : 191|8@0+ (1,0) [0|255] ""  HUD
 SG_ HUD_DiagReqData24 : 199|8@0+ (1,0) [0|255] ""  HUD
 SG_ HUD_DiagReqData25 : 207|8@0+ (1,0) [0|255] ""  HUD
 SG_ HUD_DiagReqData26 : 215|8@0+ (1,0) [0|255] ""  HUD
 SG_ HUD_DiagReqData27 : 223|8@0+ (1,0) [0|255] ""  HUD
 SG_ HUD_DiagReqData28 : 231|8@0+ (1,0) [0|255] ""  HUD
 SG_ HUD_DiagReqData29 : 239|8@0+ (1,0) [0|255] ""  HUD
 SG_ HUD_DiagReqData30 : 247|8@0+ (1,0) [0|255] ""  HUD
 SG_ HUD_DiagReqData31 : 255|8@0+ (1,0) [0|255] ""  HUD
 SG_ HUD_DiagReqData32 : 263|8@0+ (1,0) [0|255] ""  HUD
 SG_ HUD_DiagReqData33 : 271|8@0+ (1,0) [0|255] ""  HUD
 SG_ HUD_DiagReqData34 : 279|8@0+ (1,0) [0|255] ""  HUD
 SG_ HUD_DiagReqData35 : 287|8@0+ (1,0) [0|255] ""  HUD
 SG_ HUD_DiagReqData36 : 295|8@0+ (1,0) [0|255] ""  HUD
 SG_ HUD_DiagReqData37 : 303|8@0+ (1,0) [0|255] ""  HUD
 SG_ HUD_DiagReqData38 : 311|8@0+ (1,0) [0|255] ""  HUD
 SG_ HUD_DiagReqData39 : 319|8@0+ (1,0) [0|255] ""  HUD
 SG_ HUD_DiagReqData40 : 327|8@0+ (1,0) [0|255] ""  HUD
 SG_ HUD_DiagReqData41 : 335|8@0+ (1,0) [0|255] ""  HUD
 SG_ HUD_DiagReqData42 : 343|8@0+ (1,0) [0|255] ""  HUD
 SG_ HUD_DiagReqData43 : 351|8@0+ (1,0) [0|255] ""  HUD
 SG_ HUD_DiagReqData44 : 359|8@0+ (1,0) [0|255] ""  HUD
 SG_ HUD_DiagReqData45 : 367|8@0+ (1,0) [0|255] ""  HUD
 SG_ HUD_DiagReqData46 : 375|8@0+ (1,0) [0|255] ""  HUD
 SG_ HUD_DiagReqData47 : 383|8@0+ (1,0) [0|255] ""  HUD
 SG_ HUD_DiagReqData48 : 391|8@0+ (1,0) [0|255] ""  HUD
 SG_ HUD_DiagReqData49 : 399|8@0+ (1,0) [0|255] ""  HUD
 SG_ HUD_DiagReqData50 : 407|8@0+ (1,0) [0|255] ""  HUD
 SG_ HUD_DiagReqData51 : 415|8@0+ (1,0) [0|255] ""  HUD
 SG_ HUD_DiagReqData52 : 423|8@0+ (1,0) [0|255] ""  HUD
 SG_ HUD_DiagReqData53 : 431|8@0+ (1,0) [0|255] ""  HUD
 SG_ HUD_DiagReqData54 : 439|8@0+ (1,0) [0|255] ""  HUD
 SG_ HUD_DiagReqData55 : 447|8@0+ (1,0) [0|255] ""  HUD
 SG_ HUD_DiagReqData56 : 455|8@0+ (1,0) [0|255] ""  HUD
 SG_ HUD_DiagReqData57 : 463|8@0+ (1,0) [0|255] ""  HUD
 SG_ HUD_DiagReqData58 : 471|8@0+ (1,0) [0|255] ""  HUD
 SG_ HUD_DiagReqData59 : 479|8@0+ (1,0) [0|255] ""  HUD
 SG_ HUD_DiagReqData60 : 487|8@0+ (1,0) [0|255] ""  HUD
 SG_ HUD_DiagReqData61 : 495|8@0+ (1,0) [0|255] ""  HUD
 SG_ HUD_DiagReqData62 : 503|8@0+ (1,0) [0|255] ""  HUD
 SG_ HUD_DiagReqData63 : 511|8@0+ (1,0) [0|255] ""  HUD

BO_ 1540 MHU_DiagResp: 64 MHU
 SG_ MHU_DiagRespData0 : 7|8@0+ (1,0) [0|255] ""  CVC_I
 SG_ MHU_DiagRespData1 : 15|8@0+ (1,0) [0|255] ""  CVC_I
 SG_ MHU_DiagRespData2 : 23|8@0+ (1,0) [0|255] ""  CVC_I
 SG_ MHU_DiagRespData3 : 31|8@0+ (1,0) [0|255] ""  CVC_I
 SG_ MHU_DiagRespData4 : 39|8@0+ (1,0) [0|255] ""  CVC_I
 SG_ MHU_DiagRespData5 : 47|8@0+ (1,0) [0|255] ""  CVC_I
 SG_ MHU_DiagRespData6 : 55|8@0+ (1,0) [0|255] ""  CVC_I
 SG_ MHU_DiagRespData7 : 63|8@0+ (1,0) [0|255] ""  CVC_I
 SG_ MHU_DiagRespData8 : 71|8@0+ (1,0) [0|255] ""  CVC_I
 SG_ MHU_DiagRespData9 : 79|8@0+ (1,0) [0|255] ""  CVC_I
 SG_ MHU_DiagRespData10 : 87|8@0+ (1,0) [0|255] ""  CVC_I
 SG_ MHU_DiagRespData11 : 95|8@0+ (1,0) [0|255] ""  CVC_I
 SG_ MHU_DiagRespData12 : 103|8@0+ (1,0) [0|255] ""  CVC_I
 SG_ MHU_DiagRespData13 : 111|8@0+ (1,0) [0|255] ""  CVC_I
 SG_ MHU_DiagRespData14 : 119|8@0+ (1,0) [0|255] ""  CVC_I
 SG_ MHU_DiagRespData15 : 127|8@0+ (1,0) [0|255] ""  CVC_I
 SG_ MHU_DiagRespData16 : 135|8@0+ (1,0) [0|255] ""  CVC_I
 SG_ MHU_DiagRespData17 : 143|8@0+ (1,0) [0|255] ""  CVC_I
 SG_ MHU_DiagRespData18 : 151|8@0+ (1,0) [0|255] ""  CVC_I
 SG_ MHU_DiagRespData19 : 159|8@0+ (1,0) [0|255] ""  CVC_I
 SG_ MHU_DiagRespData20 : 167|8@0+ (1,0) [0|255] ""  CVC_I
 SG_ MHU_DiagRespData21 : 175|8@0+ (1,0) [0|255] ""  CVC_I
 SG_ MHU_DiagRespData22 : 183|8@0+ (1,0) [0|255] ""  CVC_I
 SG_ MHU_DiagRespData23 : 191|8@0+ (1,0) [0|255] ""  CVC_I
 SG_ MHU_DiagRespData24 : 199|8@0+ (1,0) [0|255] ""  CVC_I
 SG_ MHU_DiagRespData25 : 207|8@0+ (1,0) [0|255] ""  CVC_I
 SG_ MHU_DiagRespData26 : 215|8@0+ (1,0) [0|255] ""  CVC_I
 SG_ MHU_DiagRespData27 : 223|8@0+ (1,0) [0|255] ""  CVC_I
 SG_ MHU_DiagRespData28 : 231|8@0+ (1,0) [0|255] ""  CVC_I
 SG_ MHU_DiagRespData29 : 239|8@0+ (1,0) [0|255] ""  CVC_I
 SG_ MHU_DiagRespData30 : 247|8@0+ (1,0) [0|255] ""  CVC_I
 SG_ MHU_DiagRespData31 : 255|8@0+ (1,0) [0|255] ""  CVC_I
 SG_ MHU_DiagRespData32 : 263|8@0+ (1,0) [0|255] ""  CVC_I
 SG_ MHU_DiagRespData33 : 271|8@0+ (1,0) [0|255] ""  CVC_I
 SG_ MHU_DiagRespData34 : 279|8@0+ (1,0) [0|255] ""  CVC_I
 SG_ MHU_DiagRespData35 : 287|8@0+ (1,0) [0|255] ""  CVC_I
 SG_ MHU_DiagRespData36 : 295|8@0+ (1,0) [0|255] ""  CVC_I
 SG_ MHU_DiagRespData37 : 303|8@0+ (1,0) [0|255] ""  CVC_I
 SG_ MHU_DiagRespData38 : 311|8@0+ (1,0) [0|255] ""  CVC_I
 SG_ MHU_DiagRespData39 : 319|8@0+ (1,0) [0|255] ""  CVC_I
 SG_ MHU_DiagRespData40 : 327|8@0+ (1,0) [0|255] ""  CVC_I
 SG_ MHU_DiagRespData41 : 335|8@0+ (1,0) [0|255] ""  CVC_I
 SG_ MHU_DiagRespData42 : 343|8@0+ (1,0) [0|255] ""  CVC_I
 SG_ MHU_DiagRespData43 : 351|8@0+ (1,0) [0|255] ""  CVC_I
 SG_ MHU_DiagRespData44 : 359|8@0+ (1,0) [0|255] ""  CVC_I
 SG_ MHU_DiagRespData45 : 367|8@0+ (1,0) [0|255] ""  CVC_I
 SG_ MHU_DiagRespData46 : 375|8@0+ (1,0) [0|255] ""  CVC_I
 SG_ MHU_DiagRespData47 : 383|8@0+ (1,0) [0|255] ""  CVC_I
 SG_ MHU_DiagRespData48 : 391|8@0+ (1,0) [0|255] ""  CVC_I
 SG_ MHU_DiagRespData49 : 399|8@0+ (1,0) [0|255] ""  CVC_I
 SG_ MHU_DiagRespData50 : 407|8@0+ (1,0) [0|255] ""  CVC_I
 SG_ MHU_DiagRespData51 : 415|8@0+ (1,0) [0|255] ""  CVC_I
 SG_ MHU_DiagRespData52 : 423|8@0+ (1,0) [0|255] ""  CVC_I
 SG_ MHU_DiagRespData53 : 431|8@0+ (1,0) [0|255] ""  CVC_I
 SG_ MHU_DiagRespData54 : 439|8@0+ (1,0) [0|255] ""  CVC_I
 SG_ MHU_DiagRespData55 : 447|8@0+ (1,0) [0|255] ""  CVC_I
 SG_ MHU_DiagRespData56 : 455|8@0+ (1,0) [0|255] ""  CVC_I
 SG_ MHU_DiagRespData57 : 463|8@0+ (1,0) [0|255] ""  CVC_I
 SG_ MHU_DiagRespData58 : 471|8@0+ (1,0) [0|255] ""  CVC_I
 SG_ MHU_DiagRespData59 : 479|8@0+ (1,0) [0|255] ""  CVC_I
 SG_ MHU_DiagRespData60 : 487|8@0+ (1,0) [0|255] ""  CVC_I
 SG_ MHU_DiagRespData61 : 495|8@0+ (1,0) [0|255] ""  CVC_I
 SG_ MHU_DiagRespData62 : 503|8@0+ (1,0) [0|255] ""  CVC_I
 SG_ MHU_DiagRespData63 : 511|8@0+ (1,0) [0|255] ""  CVC_I

BO_ 1668 MHU_DiagReq: 64 CVC_I
 SG_ MHU_DiagReqData0 : 7|8@0+ (1,0) [0|255] ""  MHU
 SG_ MHU_DiagReqData1 : 15|8@0+ (1,0) [0|255] ""  MHU
 SG_ MHU_DiagReqData2 : 23|8@0+ (1,0) [0|255] ""  MHU
 SG_ MHU_DiagReqData3 : 31|8@0+ (1,0) [0|255] ""  MHU
 SG_ MHU_DiagReqData4 : 39|8@0+ (1,0) [0|255] ""  MHU
 SG_ MHU_DiagReqData5 : 47|8@0+ (1,0) [0|255] ""  MHU
 SG_ MHU_DiagReqData6 : 55|8@0+ (1,0) [0|255] ""  MHU
 SG_ MHU_DiagReqData7 : 63|8@0+ (1,0) [0|255] ""  MHU
 SG_ MHU_DiagReqData8 : 71|8@0+ (1,0) [0|255] ""  MHU
 SG_ MHU_DiagReqData9 : 79|8@0+ (1,0) [0|255] ""  MHU
 SG_ MHU_DiagReqData10 : 87|8@0+ (1,0) [0|255] ""  MHU
 SG_ MHU_DiagReqData11 : 95|8@0+ (1,0) [0|255] ""  MHU
 SG_ MHU_DiagReqData12 : 103|8@0+ (1,0) [0|255] ""  MHU
 SG_ MHU_DiagReqData13 : 111|8@0+ (1,0) [0|255] ""  MHU
 SG_ MHU_DiagReqData14 : 119|8@0+ (1,0) [0|255] ""  MHU
 SG_ MHU_DiagReqData15 : 127|8@0+ (1,0) [0|255] ""  MHU
 SG_ MHU_DiagReqData16 : 135|8@0+ (1,0) [0|255] ""  MHU
 SG_ MHU_DiagReqData17 : 143|8@0+ (1,0) [0|255] ""  MHU
 SG_ MHU_DiagReqData18 : 151|8@0+ (1,0) [0|255] ""  MHU
 SG_ MHU_DiagReqData19 : 159|8@0+ (1,0) [0|255] ""  MHU
 SG_ MHU_DiagReqData20 : 167|8@0+ (1,0) [0|255] ""  MHU
 SG_ MHU_DiagReqData21 : 175|8@0+ (1,0) [0|255] ""  MHU
 SG_ MHU_DiagReqData22 : 183|8@0+ (1,0) [0|255] ""  MHU
 SG_ MHU_DiagReqData23 : 191|8@0+ (1,0) [0|255] ""  MHU
 SG_ MHU_DiagReqData24 : 199|8@0+ (1,0) [0|255] ""  MHU
 SG_ MHU_DiagReqData25 : 207|8@0+ (1,0) [0|255] ""  MHU
 SG_ MHU_DiagReqData26 : 215|8@0+ (1,0) [0|255] ""  MHU
 SG_ MHU_DiagReqData27 : 223|8@0+ (1,0) [0|255] ""  MHU
 SG_ MHU_DiagReqData28 : 231|8@0+ (1,0) [0|255] ""  MHU
 SG_ MHU_DiagReqData29 : 239|8@0+ (1,0) [0|255] ""  MHU
 SG_ MHU_DiagReqData30 : 247|8@0+ (1,0) [0|255] ""  MHU
 SG_ MHU_DiagReqData31 : 255|8@0+ (1,0) [0|255] ""  MHU
 SG_ MHU_DiagReqData32 : 263|8@0+ (1,0) [0|255] ""  MHU
 SG_ MHU_DiagReqData33 : 271|8@0+ (1,0) [0|255] ""  MHU
 SG_ MHU_DiagReqData34 : 279|8@0+ (1,0) [0|255] ""  MHU
 SG_ MHU_DiagReqData35 : 287|8@0+ (1,0) [0|255] ""  MHU
 SG_ MHU_DiagReqData36 : 295|8@0+ (1,0) [0|255] ""  MHU
 SG_ MHU_DiagReqData37 : 303|8@0+ (1,0) [0|255] ""  MHU
 SG_ MHU_DiagReqData38 : 311|8@0+ (1,0) [0|255] ""  MHU
 SG_ MHU_DiagReqData39 : 319|8@0+ (1,0) [0|255] ""  MHU
 SG_ MHU_DiagReqData40 : 327|8@0+ (1,0) [0|255] ""  MHU
 SG_ MHU_DiagReqData41 : 335|8@0+ (1,0) [0|255] ""  MHU
 SG_ MHU_DiagReqData42 : 343|8@0+ (1,0) [0|255] ""  MHU
 SG_ MHU_DiagReqData43 : 351|8@0+ (1,0) [0|255] ""  MHU
 SG_ MHU_DiagReqData44 : 359|8@0+ (1,0) [0|255] ""  MHU
 SG_ MHU_DiagReqData45 : 367|8@0+ (1,0) [0|255] ""  MHU
 SG_ MHU_DiagReqData46 : 375|8@0+ (1,0) [0|255] ""  MHU
 SG_ MHU_DiagReqData47 : 383|8@0+ (1,0) [0|255] ""  MHU
 SG_ MHU_DiagReqData48 : 391|8@0+ (1,0) [0|255] ""  MHU
 SG_ MHU_DiagReqData49 : 399|8@0+ (1,0) [0|255] ""  MHU
 SG_ MHU_DiagReqData50 : 407|8@0+ (1,0) [0|255] ""  MHU
 SG_ MHU_DiagReqData51 : 415|8@0+ (1,0) [0|255] ""  MHU
 SG_ MHU_DiagReqData52 : 423|8@0+ (1,0) [0|255] ""  MHU
 SG_ MHU_DiagReqData53 : 431|8@0+ (1,0) [0|255] ""  MHU
 SG_ MHU_DiagReqData54 : 439|8@0+ (1,0) [0|255] ""  MHU
 SG_ MHU_DiagReqData55 : 447|8@0+ (1,0) [0|255] ""  MHU
 SG_ MHU_DiagReqData56 : 455|8@0+ (1,0) [0|255] ""  MHU
 SG_ MHU_DiagReqData57 : 463|8@0+ (1,0) [0|255] ""  MHU
 SG_ MHU_DiagReqData58 : 471|8@0+ (1,0) [0|255] ""  MHU
 SG_ MHU_DiagReqData59 : 479|8@0+ (1,0) [0|255] ""  MHU
 SG_ MHU_DiagReqData60 : 487|8@0+ (1,0) [0|255] ""  MHU
 SG_ MHU_DiagReqData61 : 495|8@0+ (1,0) [0|255] ""  MHU
 SG_ MHU_DiagReqData62 : 503|8@0+ (1,0) [0|255] ""  MHU
 SG_ MHU_DiagReqData63 : 511|8@0+ (1,0) [0|255] ""  MHU

BO_ 1701 MRR_DiagReq: 64 CVC_I
 SG_ MRR_DiagReqData0 : 7|8@0+ (1,0) [0|255] ""  MRR
 SG_ MRR_DiagReqData1 : 15|8@0+ (1,0) [0|255] ""  MRR
 SG_ MRR_DiagReqData2 : 23|8@0+ (1,0) [0|255] ""  MRR
 SG_ MRR_DiagReqData3 : 31|8@0+ (1,0) [0|255] ""  MRR
 SG_ MRR_DiagReqData4 : 39|8@0+ (1,0) [0|255] ""  MRR
 SG_ MRR_DiagReqData5 : 47|8@0+ (1,0) [0|255] ""  MRR
 SG_ MRR_DiagReqData6 : 55|8@0+ (1,0) [0|255] ""  MRR
 SG_ MRR_DiagReqData7 : 63|8@0+ (1,0) [0|255] ""  MRR
 SG_ MRR_DiagReqData8 : 71|8@0+ (1,0) [0|255] ""  MRR
 SG_ MRR_DiagReqData9 : 79|8@0+ (1,0) [0|255] ""  MRR
 SG_ MRR_DiagReqData10 : 87|8@0+ (1,0) [0|255] ""  MRR
 SG_ MRR_DiagReqData11 : 95|8@0+ (1,0) [0|255] ""  MRR
 SG_ MRR_DiagReqData12 : 103|8@0+ (1,0) [0|255] ""  MRR
 SG_ MRR_DiagReqData13 : 111|8@0+ (1,0) [0|255] ""  MRR
 SG_ MRR_DiagReqData14 : 119|8@0+ (1,0) [0|255] ""  MRR
 SG_ MRR_DiagReqData15 : 127|8@0+ (1,0) [0|255] ""  MRR
 SG_ MRR_DiagReqData16 : 135|8@0+ (1,0) [0|255] ""  MRR
 SG_ MRR_DiagReqData17 : 143|8@0+ (1,0) [0|255] ""  MRR
 SG_ MRR_DiagReqData18 : 151|8@0+ (1,0) [0|255] ""  MRR
 SG_ MRR_DiagReqData19 : 159|8@0+ (1,0) [0|255] ""  MRR
 SG_ MRR_DiagReqData20 : 167|8@0+ (1,0) [0|255] ""  MRR
 SG_ MRR_DiagReqData21 : 175|8@0+ (1,0) [0|255] ""  MRR
 SG_ MRR_DiagReqData22 : 183|8@0+ (1,0) [0|255] ""  MRR
 SG_ MRR_DiagReqData23 : 191|8@0+ (1,0) [0|255] ""  MRR
 SG_ MRR_DiagReqData24 : 199|8@0+ (1,0) [0|255] ""  MRR
 SG_ MRR_DiagReqData25 : 207|8@0+ (1,0) [0|255] ""  MRR
 SG_ MRR_DiagReqData26 : 215|8@0+ (1,0) [0|255] ""  MRR
 SG_ MRR_DiagReqData27 : 223|8@0+ (1,0) [0|255] ""  MRR
 SG_ MRR_DiagReqData28 : 231|8@0+ (1,0) [0|255] ""  MRR
 SG_ MRR_DiagReqData29 : 239|8@0+ (1,0) [0|255] ""  MRR
 SG_ MRR_DiagReqData30 : 247|8@0+ (1,0) [0|255] ""  MRR
 SG_ MRR_DiagReqData31 : 255|8@0+ (1,0) [0|255] ""  MRR
 SG_ MRR_DiagReqData32 : 263|8@0+ (1,0) [0|255] ""  MRR
 SG_ MRR_DiagReqData33 : 271|8@0+ (1,0) [0|255] ""  MRR
 SG_ MRR_DiagReqData34 : 279|8@0+ (1,0) [0|255] ""  MRR
 SG_ MRR_DiagReqData35 : 287|8@0+ (1,0) [0|255] ""  MRR
 SG_ MRR_DiagReqData36 : 295|8@0+ (1,0) [0|255] ""  MRR
 SG_ MRR_DiagReqData37 : 303|8@0+ (1,0) [0|255] ""  MRR
 SG_ MRR_DiagReqData38 : 311|8@0+ (1,0) [0|255] ""  MRR
 SG_ MRR_DiagReqData39 : 319|8@0+ (1,0) [0|255] ""  MRR
 SG_ MRR_DiagReqData40 : 327|8@0+ (1,0) [0|255] ""  MRR
 SG_ MRR_DiagReqData41 : 335|8@0+ (1,0) [0|255] ""  MRR
 SG_ MRR_DiagReqData42 : 343|8@0+ (1,0) [0|255] ""  MRR
 SG_ MRR_DiagReqData43 : 351|8@0+ (1,0) [0|255] ""  MRR
 SG_ MRR_DiagReqData44 : 359|8@0+ (1,0) [0|255] ""  MRR
 SG_ MRR_DiagReqData45 : 367|8@0+ (1,0) [0|255] ""  MRR
 SG_ MRR_DiagReqData46 : 375|8@0+ (1,0) [0|255] ""  MRR
 SG_ MRR_DiagReqData47 : 383|8@0+ (1,0) [0|255] ""  MRR
 SG_ MRR_DiagReqData48 : 391|8@0+ (1,0) [0|255] ""  MRR
 SG_ MRR_DiagReqData49 : 399|8@0+ (1,0) [0|255] ""  MRR
 SG_ MRR_DiagReqData50 : 407|8@0+ (1,0) [0|255] ""  MRR
 SG_ MRR_DiagReqData51 : 415|8@0+ (1,0) [0|255] ""  MRR
 SG_ MRR_DiagReqData52 : 423|8@0+ (1,0) [0|255] ""  MRR
 SG_ MRR_DiagReqData53 : 431|8@0+ (1,0) [0|255] ""  MRR
 SG_ MRR_DiagReqData54 : 439|8@0+ (1,0) [0|255] ""  MRR
 SG_ MRR_DiagReqData55 : 447|8@0+ (1,0) [0|255] ""  MRR
 SG_ MRR_DiagReqData56 : 455|8@0+ (1,0) [0|255] ""  MRR
 SG_ MRR_DiagReqData57 : 463|8@0+ (1,0) [0|255] ""  MRR
 SG_ MRR_DiagReqData58 : 471|8@0+ (1,0) [0|255] ""  MRR
 SG_ MRR_DiagReqData59 : 479|8@0+ (1,0) [0|255] ""  MRR
 SG_ MRR_DiagReqData60 : 487|8@0+ (1,0) [0|255] ""  MRR
 SG_ MRR_DiagReqData61 : 495|8@0+ (1,0) [0|255] ""  MRR
 SG_ MRR_DiagReqData62 : 503|8@0+ (1,0) [0|255] ""  MRR
 SG_ MRR_DiagReqData63 : 511|8@0+ (1,0) [0|255] ""  MRR

BO_ 1573 MRR_DiagResp: 64 MRR
 SG_ MRR_DiagRespData0 : 7|8@0+ (1,0) [0|255] ""  CVC_I
 SG_ MRR_DiagRespData1 : 15|8@0+ (1,0) [0|255] ""  CVC_I
 SG_ MRR_DiagRespData2 : 23|8@0+ (1,0) [0|255] ""  CVC_I
 SG_ MRR_DiagRespData3 : 31|8@0+ (1,0) [0|255] ""  CVC_I
 SG_ MRR_DiagRespData4 : 39|8@0+ (1,0) [0|255] ""  CVC_I
 SG_ MRR_DiagRespData5 : 47|8@0+ (1,0) [0|255] ""  CVC_I
 SG_ MRR_DiagRespData6 : 55|8@0+ (1,0) [0|255] ""  CVC_I
 SG_ MRR_DiagRespData7 : 63|8@0+ (1,0) [0|255] ""  CVC_I
 SG_ MRR_DiagRespData8 : 71|8@0+ (1,0) [0|255] ""  CVC_I
 SG_ MRR_DiagRespData9 : 79|8@0+ (1,0) [0|255] ""  CVC_I
 SG_ MRR_DiagRespData10 : 87|8@0+ (1,0) [0|255] ""  CVC_I
 SG_ MRR_DiagRespData11 : 95|8@0+ (1,0) [0|255] ""  CVC_I
 SG_ MRR_DiagRespData12 : 103|8@0+ (1,0) [0|255] ""  CVC_I
 SG_ MRR_DiagRespData13 : 111|8@0+ (1,0) [0|255] ""  CVC_I
 SG_ MRR_DiagRespData14 : 119|8@0+ (1,0) [0|255] ""  CVC_I
 SG_ MRR_DiagRespData15 : 127|8@0+ (1,0) [0|255] ""  CVC_I
 SG_ MRR_DiagRespData16 : 135|8@0+ (1,0) [0|255] ""  CVC_I
 SG_ MRR_DiagRespData17 : 143|8@0+ (1,0) [0|255] ""  CVC_I
 SG_ MRR_DiagRespData18 : 151|8@0+ (1,0) [0|255] ""  CVC_I
 SG_ MRR_DiagRespData19 : 159|8@0+ (1,0) [0|255] ""  CVC_I
 SG_ MRR_DiagRespData20 : 167|8@0+ (1,0) [0|255] ""  CVC_I
 SG_ MRR_DiagRespData21 : 175|8@0+ (1,0) [0|255] ""  CVC_I
 SG_ MRR_DiagRespData22 : 183|8@0+ (1,0) [0|255] ""  CVC_I
 SG_ MRR_DiagRespData23 : 191|8@0+ (1,0) [0|255] ""  CVC_I
 SG_ MRR_DiagRespData24 : 199|8@0+ (1,0) [0|255] ""  CVC_I
 SG_ MRR_DiagRespData25 : 207|8@0+ (1,0) [0|255] ""  CVC_I
 SG_ MRR_DiagRespData26 : 215|8@0+ (1,0) [0|255] ""  CVC_I
 SG_ MRR_DiagRespData27 : 223|8@0+ (1,0) [0|255] ""  CVC_I
 SG_ MRR_DiagRespData28 : 231|8@0+ (1,0) [0|255] ""  CVC_I
 SG_ MRR_DiagRespData29 : 239|8@0+ (1,0) [0|255] ""  CVC_I
 SG_ MRR_DiagRespData30 : 247|8@0+ (1,0) [0|255] ""  CVC_I
 SG_ MRR_DiagRespData31 : 255|8@0+ (1,0) [0|255] ""  CVC_I
 SG_ MRR_DiagRespData32 : 263|8@0+ (1,0) [0|255] ""  CVC_I
 SG_ MRR_DiagRespData33 : 271|8@0+ (1,0) [0|255] ""  CVC_I
 SG_ MRR_DiagRespData34 : 279|8@0+ (1,0) [0|255] ""  CVC_I
 SG_ MRR_DiagRespData35 : 287|8@0+ (1,0) [0|255] ""  CVC_I
 SG_ MRR_DiagRespData36 : 295|8@0+ (1,0) [0|255] ""  CVC_I
 SG_ MRR_DiagRespData37 : 303|8@0+ (1,0) [0|255] ""  CVC_I
 SG_ MRR_DiagRespData38 : 311|8@0+ (1,0) [0|255] ""  CVC_I
 SG_ MRR_DiagRespData39 : 319|8@0+ (1,0) [0|255] ""  CVC_I
 SG_ MRR_DiagRespData40 : 327|8@0+ (1,0) [0|255] ""  CVC_I
 SG_ MRR_DiagRespData41 : 335|8@0+ (1,0) [0|255] ""  CVC_I
 SG_ MRR_DiagRespData42 : 343|8@0+ (1,0) [0|255] ""  CVC_I
 SG_ MRR_DiagRespData43 : 351|8@0+ (1,0) [0|255] ""  CVC_I
 SG_ MRR_DiagRespData44 : 359|8@0+ (1,0) [0|255] ""  CVC_I
 SG_ MRR_DiagRespData45 : 367|8@0+ (1,0) [0|255] ""  CVC_I
 SG_ MRR_DiagRespData46 : 375|8@0+ (1,0) [0|255] ""  CVC_I
 SG_ MRR_DiagRespData47 : 383|8@0+ (1,0) [0|255] ""  CVC_I
 SG_ MRR_DiagRespData48 : 391|8@0+ (1,0) [0|255] ""  CVC_I
 SG_ MRR_DiagRespData49 : 399|8@0+ (1,0) [0|255] ""  CVC_I
 SG_ MRR_DiagRespData50 : 407|8@0+ (1,0) [0|255] ""  CVC_I
 SG_ MRR_DiagRespData51 : 415|8@0+ (1,0) [0|255] ""  CVC_I
 SG_ MRR_DiagRespData52 : 423|8@0+ (1,0) [0|255] ""  CVC_I
 SG_ MRR_DiagRespData53 : 431|8@0+ (1,0) [0|255] ""  CVC_I
 SG_ MRR_DiagRespData54 : 439|8@0+ (1,0) [0|255] ""  CVC_I
 SG_ MRR_DiagRespData55 : 447|8@0+ (1,0) [0|255] ""  CVC_I
 SG_ MRR_DiagRespData56 : 455|8@0+ (1,0) [0|255] ""  CVC_I
 SG_ MRR_DiagRespData57 : 463|8@0+ (1,0) [0|255] ""  CVC_I
 SG_ MRR_DiagRespData58 : 471|8@0+ (1,0) [0|255] ""  CVC_I
 SG_ MRR_DiagRespData59 : 479|8@0+ (1,0) [0|255] ""  CVC_I
 SG_ MRR_DiagRespData60 : 487|8@0+ (1,0) [0|255] ""  CVC_I
 SG_ MRR_DiagRespData61 : 495|8@0+ (1,0) [0|255] ""  CVC_I
 SG_ MRR_DiagRespData62 : 503|8@0+ (1,0) [0|255] ""  CVC_I
 SG_ MRR_DiagRespData63 : 511|8@0+ (1,0) [0|255] ""  CVC_I

BO_ 1719 SRR_RL_DiagReq: 64 CVC_I
 SG_ SRR_RL_DiagReqData0 : 7|8@0+ (1,0) [0|255] ""  SRR_RL
 SG_ SRR_RL_DiagReqData1 : 15|8@0+ (1,0) [0|255] ""  SRR_RL
 SG_ SRR_RL_DiagReqData2 : 23|8@0+ (1,0) [0|255] ""  SRR_RL
 SG_ SRR_RL_DiagReqData3 : 31|8@0+ (1,0) [0|255] ""  SRR_RL
 SG_ SRR_RL_DiagReqData4 : 39|8@0+ (1,0) [0|255] ""  SRR_RL
 SG_ SRR_RL_DiagReqData5 : 47|8@0+ (1,0) [0|255] ""  SRR_RL
 SG_ SRR_RL_DiagReqData6 : 55|8@0+ (1,0) [0|255] ""  SRR_RL
 SG_ SRR_RL_DiagReqData7 : 63|8@0+ (1,0) [0|255] ""  SRR_RL
 SG_ SRR_RL_DiagReqData8 : 71|8@0+ (1,0) [0|255] ""  SRR_RL
 SG_ SRR_RL_DiagReqData9 : 79|8@0+ (1,0) [0|255] ""  SRR_RL
 SG_ SRR_RL_DiagReqData10 : 87|8@0+ (1,0) [0|255] ""  SRR_RL
 SG_ SRR_RL_DiagReqData11 : 95|8@0+ (1,0) [0|255] ""  SRR_RL
 SG_ SRR_RL_DiagReqData12 : 103|8@0+ (1,0) [0|255] ""  SRR_RL
 SG_ SRR_RL_DiagReqData13 : 111|8@0+ (1,0) [0|255] ""  SRR_RL
 SG_ SRR_RL_DiagReqData14 : 119|8@0+ (1,0) [0|255] ""  SRR_RL
 SG_ SRR_RL_DiagReqData15 : 127|8@0+ (1,0) [0|255] ""  SRR_RL
 SG_ SRR_RL_DiagReqData16 : 135|8@0+ (1,0) [0|255] ""  SRR_RL
 SG_ SRR_RL_DiagReqData17 : 143|8@0+ (1,0) [0|255] ""  SRR_RL
 SG_ SRR_RL_DiagReqData18 : 151|8@0+ (1,0) [0|255] ""  SRR_RL
 SG_ SRR_RL_DiagReqData19 : 159|8@0+ (1,0) [0|255] ""  SRR_RL
 SG_ SRR_RL_DiagReqData20 : 167|8@0+ (1,0) [0|255] ""  SRR_RL
 SG_ SRR_RL_DiagReqData21 : 175|8@0+ (1,0) [0|255] ""  SRR_RL
 SG_ SRR_RL_DiagReqData22 : 183|8@0+ (1,0) [0|255] ""  SRR_RL
 SG_ SRR_RL_DiagReqData23 : 191|8@0+ (1,0) [0|255] ""  SRR_RL
 SG_ SRR_RL_DiagReqData24 : 199|8@0+ (1,0) [0|255] ""  SRR_RL
 SG_ SRR_RL_DiagReqData25 : 207|8@0+ (1,0) [0|255] ""  SRR_RL
 SG_ SRR_RL_DiagReqData26 : 215|8@0+ (1,0) [0|255] ""  SRR_RL
 SG_ SRR_RL_DiagReqData27 : 223|8@0+ (1,0) [0|255] ""  SRR_RL
 SG_ SRR_RL_DiagReqData28 : 231|8@0+ (1,0) [0|255] ""  SRR_RL
 SG_ SRR_RL_DiagReqData29 : 239|8@0+ (1,0) [0|255] ""  SRR_RL
 SG_ SRR_RL_DiagReqData30 : 247|8@0+ (1,0) [0|255] ""  SRR_RL
 SG_ SRR_RL_DiagReqData31 : 255|8@0+ (1,0) [0|255] ""  SRR_RL
 SG_ SRR_RL_DiagReqData32 : 263|8@0+ (1,0) [0|255] ""  SRR_RL
 SG_ SRR_RL_DiagReqData33 : 271|8@0+ (1,0) [0|255] ""  SRR_RL
 SG_ SRR_RL_DiagReqData34 : 279|8@0+ (1,0) [0|255] ""  SRR_RL
 SG_ SRR_RL_DiagReqData35 : 287|8@0+ (1,0) [0|255] ""  SRR_RL
 SG_ SRR_RL_DiagReqData36 : 295|8@0+ (1,0) [0|255] ""  SRR_RL
 SG_ SRR_RL_DiagReqData37 : 303|8@0+ (1,0) [0|255] ""  SRR_RL
 SG_ SRR_RL_DiagReqData38 : 311|8@0+ (1,0) [0|255] ""  SRR_RL
 SG_ SRR_RL_DiagReqData39 : 319|8@0+ (1,0) [0|255] ""  SRR_RL
 SG_ SRR_RL_DiagReqData40 : 327|8@0+ (1,0) [0|255] ""  SRR_RL
 SG_ SRR_RL_DiagReqData41 : 335|8@0+ (1,0) [0|255] ""  SRR_RL
 SG_ SRR_RL_DiagReqData42 : 343|8@0+ (1,0) [0|255] ""  SRR_RL
 SG_ SRR_RL_DiagReqData43 : 351|8@0+ (1,0) [0|255] ""  SRR_RL
 SG_ SRR_RL_DiagReqData44 : 359|8@0+ (1,0) [0|255] ""  SRR_RL
 SG_ SRR_RL_DiagReqData45 : 367|8@0+ (1,0) [0|255] ""  SRR_RL
 SG_ SRR_RL_DiagReqData46 : 375|8@0+ (1,0) [0|255] ""  SRR_RL
 SG_ SRR_RL_DiagReqData47 : 383|8@0+ (1,0) [0|255] ""  SRR_RL
 SG_ SRR_RL_DiagReqData48 : 391|8@0+ (1,0) [0|255] ""  SRR_RL
 SG_ SRR_RL_DiagReqData49 : 399|8@0+ (1,0) [0|255] ""  SRR_RL
 SG_ SRR_RL_DiagReqData50 : 407|8@0+ (1,0) [0|255] ""  SRR_RL
 SG_ SRR_RL_DiagReqData51 : 415|8@0+ (1,0) [0|255] ""  SRR_RL
 SG_ SRR_RL_DiagReqData52 : 423|8@0+ (1,0) [0|255] ""  SRR_RL
 SG_ SRR_RL_DiagReqData53 : 431|8@0+ (1,0) [0|255] ""  SRR_RL
 SG_ SRR_RL_DiagReqData54 : 439|8@0+ (1,0) [0|255] ""  SRR_RL
 SG_ SRR_RL_DiagReqData55 : 447|8@0+ (1,0) [0|255] ""  SRR_RL
 SG_ SRR_RL_DiagReqData56 : 455|8@0+ (1,0) [0|255] ""  SRR_RL
 SG_ SRR_RL_DiagReqData57 : 463|8@0+ (1,0) [0|255] ""  SRR_RL
 SG_ SRR_RL_DiagReqData58 : 471|8@0+ (1,0) [0|255] ""  SRR_RL
 SG_ SRR_RL_DiagReqData59 : 479|8@0+ (1,0) [0|255] ""  SRR_RL
 SG_ SRR_RL_DiagReqData60 : 487|8@0+ (1,0) [0|255] ""  SRR_RL
 SG_ SRR_RL_DiagReqData61 : 495|8@0+ (1,0) [0|255] ""  SRR_RL
 SG_ SRR_RL_DiagReqData62 : 503|8@0+ (1,0) [0|255] ""  SRR_RL
 SG_ SRR_RL_DiagReqData63 : 511|8@0+ (1,0) [0|255] ""  SRR_RL

BO_ 1591 SRR_RL_DiagResp: 64 SRR_RL
 SG_ SRR_RL_DiagRespData0 : 7|8@0+ (1,0) [0|255] ""  CVC_I
 SG_ SRR_RL_DiagRespData1 : 15|8@0+ (1,0) [0|255] ""  CVC_I
 SG_ SRR_RL_DiagRespData2 : 23|8@0+ (1,0) [0|255] ""  CVC_I
 SG_ SRR_RL_DiagRespData3 : 31|8@0+ (1,0) [0|255] ""  CVC_I
 SG_ SRR_RL_DiagRespData4 : 39|8@0+ (1,0) [0|255] ""  CVC_I
 SG_ SRR_RL_DiagRespData5 : 47|8@0+ (1,0) [0|255] ""  CVC_I
 SG_ SRR_RL_DiagRespData6 : 55|8@0+ (1,0) [0|255] ""  CVC_I
 SG_ SRR_RL_DiagRespData7 : 63|8@0+ (1,0) [0|255] ""  CVC_I
 SG_ SRR_RL_DiagRespData8 : 71|8@0+ (1,0) [0|255] ""  CVC_I
 SG_ SRR_RL_DiagRespData9 : 79|8@0+ (1,0) [0|255] ""  CVC_I
 SG_ SRR_RL_DiagRespData10 : 87|8@0+ (1,0) [0|255] ""  CVC_I
 SG_ SRR_RL_DiagRespData11 : 95|8@0+ (1,0) [0|255] ""  CVC_I
 SG_ SRR_RL_DiagRespData12 : 103|8@0+ (1,0) [0|255] ""  CVC_I
 SG_ SRR_RL_DiagRespData13 : 111|8@0+ (1,0) [0|255] ""  CVC_I
 SG_ SRR_RL_DiagRespData14 : 119|8@0+ (1,0) [0|255] ""  CVC_I
 SG_ SRR_RL_DiagRespData15 : 127|8@0+ (1,0) [0|255] ""  CVC_I
 SG_ SRR_RL_DiagRespData16 : 135|8@0+ (1,0) [0|255] ""  CVC_I
 SG_ SRR_RL_DiagRespData17 : 143|8@0+ (1,0) [0|255] ""  CVC_I
 SG_ SRR_RL_DiagRespData18 : 151|8@0+ (1,0) [0|255] ""  CVC_I
 SG_ SRR_RL_DiagRespData19 : 159|8@0+ (1,0) [0|255] ""  CVC_I
 SG_ SRR_RL_DiagRespData20 : 167|8@0+ (1,0) [0|255] ""  CVC_I
 SG_ SRR_RL_DiagRespData21 : 175|8@0+ (1,0) [0|255] ""  CVC_I
 SG_ SRR_RL_DiagRespData22 : 183|8@0+ (1,0) [0|255] ""  CVC_I
 SG_ SRR_RL_DiagRespData23 : 191|8@0+ (1,0) [0|255] ""  CVC_I
 SG_ SRR_RL_DiagRespData24 : 199|8@0+ (1,0) [0|255] ""  CVC_I
 SG_ SRR_RL_DiagRespData25 : 207|8@0+ (1,0) [0|255] ""  CVC_I
 SG_ SRR_RL_DiagRespData26 : 215|8@0+ (1,0) [0|255] ""  CVC_I
 SG_ SRR_RL_DiagRespData27 : 223|8@0+ (1,0) [0|255] ""  CVC_I
 SG_ SRR_RL_DiagRespData28 : 231|8@0+ (1,0) [0|255] ""  CVC_I
 SG_ SRR_RL_DiagRespData29 : 239|8@0+ (1,0) [0|255] ""  CVC_I
 SG_ SRR_RL_DiagRespData30 : 247|8@0+ (1,0) [0|255] ""  CVC_I
 SG_ SRR_RL_DiagRespData31 : 255|8@0+ (1,0) [0|255] ""  CVC_I
 SG_ SRR_RL_DiagRespData32 : 263|8@0+ (1,0) [0|255] ""  CVC_I
 SG_ SRR_RL_DiagRespData33 : 271|8@0+ (1,0) [0|255] ""  CVC_I
 SG_ SRR_RL_DiagRespData34 : 279|8@0+ (1,0) [0|255] ""  CVC_I
 SG_ SRR_RL_DiagRespData35 : 287|8@0+ (1,0) [0|255] ""  CVC_I
 SG_ SRR_RL_DiagRespData36 : 295|8@0+ (1,0) [0|255] ""  CVC_I
 SG_ SRR_RL_DiagRespData37 : 303|8@0+ (1,0) [0|255] ""  CVC_I
 SG_ SRR_RL_DiagRespData38 : 311|8@0+ (1,0) [0|255] ""  CVC_I
 SG_ SRR_RL_DiagRespData39 : 319|8@0+ (1,0) [0|255] ""  CVC_I
 SG_ SRR_RL_DiagRespData40 : 327|8@0+ (1,0) [0|255] ""  CVC_I
 SG_ SRR_RL_DiagRespData41 : 335|8@0+ (1,0) [0|255] ""  CVC_I
 SG_ SRR_RL_DiagRespData42 : 343|8@0+ (1,0) [0|255] ""  CVC_I
 SG_ SRR_RL_DiagRespData43 : 351|8@0+ (1,0) [0|255] ""  CVC_I
 SG_ SRR_RL_DiagRespData44 : 359|8@0+ (1,0) [0|255] ""  CVC_I
 SG_ SRR_RL_DiagRespData45 : 367|8@0+ (1,0) [0|255] ""  CVC_I
 SG_ SRR_RL_DiagRespData46 : 375|8@0+ (1,0) [0|255] ""  CVC_I
 SG_ SRR_RL_DiagRespData47 : 383|8@0+ (1,0) [0|255] ""  CVC_I
 SG_ SRR_RL_DiagRespData48 : 391|8@0+ (1,0) [0|255] ""  CVC_I
 SG_ SRR_RL_DiagRespData49 : 399|8@0+ (1,0) [0|255] ""  CVC_I
 SG_ SRR_RL_DiagRespData50 : 407|8@0+ (1,0) [0|255] ""  CVC_I
 SG_ SRR_RL_DiagRespData51 : 415|8@0+ (1,0) [0|255] ""  CVC_I
 SG_ SRR_RL_DiagRespData52 : 423|8@0+ (1,0) [0|255] ""  CVC_I
 SG_ SRR_RL_DiagRespData53 : 431|8@0+ (1,0) [0|255] ""  CVC_I
 SG_ SRR_RL_DiagRespData54 : 439|8@0+ (1,0) [0|255] ""  CVC_I
 SG_ SRR_RL_DiagRespData55 : 447|8@0+ (1,0) [0|255] ""  CVC_I
 SG_ SRR_RL_DiagRespData56 : 455|8@0+ (1,0) [0|255] ""  CVC_I
 SG_ SRR_RL_DiagRespData57 : 463|8@0+ (1,0) [0|255] ""  CVC_I
 SG_ SRR_RL_DiagRespData58 : 471|8@0+ (1,0) [0|255] ""  CVC_I
 SG_ SRR_RL_DiagRespData59 : 479|8@0+ (1,0) [0|255] ""  CVC_I
 SG_ SRR_RL_DiagRespData60 : 487|8@0+ (1,0) [0|255] ""  CVC_I
 SG_ SRR_RL_DiagRespData61 : 495|8@0+ (1,0) [0|255] ""  CVC_I
 SG_ SRR_RL_DiagRespData62 : 503|8@0+ (1,0) [0|255] ""  CVC_I
 SG_ SRR_RL_DiagRespData63 : 511|8@0+ (1,0) [0|255] ""  CVC_I

BO_ 1718 SRR_RR_DiagReq: 64 CVC_I
 SG_ SRR_RR_DiagReqData0 : 7|8@0+ (1,0) [0|255] ""  SRR_RR
 SG_ SRR_RR_DiagReqData1 : 15|8@0+ (1,0) [0|255] ""  SRR_RR
 SG_ SRR_RR_DiagReqData2 : 23|8@0+ (1,0) [0|255] ""  SRR_RR
 SG_ SRR_RR_DiagReqData3 : 31|8@0+ (1,0) [0|255] ""  SRR_RR
 SG_ SRR_RR_DiagReqData4 : 39|8@0+ (1,0) [0|255] ""  SRR_RR
 SG_ SRR_RR_DiagReqData5 : 47|8@0+ (1,0) [0|255] ""  SRR_RR
 SG_ SRR_RR_DiagReqData6 : 55|8@0+ (1,0) [0|255] ""  SRR_RR
 SG_ SRR_RR_DiagReqData7 : 63|8@0+ (1,0) [0|255] ""  SRR_RR
 SG_ SRR_RR_DiagReqData8 : 71|8@0+ (1,0) [0|255] ""  SRR_RR
 SG_ SRR_RR_DiagReqData9 : 79|8@0+ (1,0) [0|255] ""  SRR_RR
 SG_ SRR_RR_DiagReqData10 : 87|8@0+ (1,0) [0|255] ""  SRR_RR
 SG_ SRR_RR_DiagReqData11 : 95|8@0+ (1,0) [0|255] ""  SRR_RR
 SG_ SRR_RR_DiagReqData12 : 103|8@0+ (1,0) [0|255] ""  SRR_RR
 SG_ SRR_RR_DiagReqData13 : 111|8@0+ (1,0) [0|255] ""  SRR_RR
 SG_ SRR_RR_DiagReqData14 : 119|8@0+ (1,0) [0|255] ""  SRR_RR
 SG_ SRR_RR_DiagReqData15 : 127|8@0+ (1,0) [0|255] ""  SRR_RR
 SG_ SRR_RR_DiagReqData16 : 135|8@0+ (1,0) [0|255] ""  SRR_RR
 SG_ SRR_RR_DiagReqData17 : 143|8@0+ (1,0) [0|255] ""  SRR_RR
 SG_ SRR_RR_DiagReqData18 : 151|8@0+ (1,0) [0|255] ""  SRR_RR
 SG_ SRR_RR_DiagReqData19 : 159|8@0+ (1,0) [0|255] ""  SRR_RR
 SG_ SRR_RR_DiagReqData20 : 167|8@0+ (1,0) [0|255] ""  SRR_RR
 SG_ SRR_RR_DiagReqData21 : 175|8@0+ (1,0) [0|255] ""  SRR_RR
 SG_ SRR_RR_DiagReqData22 : 183|8@0+ (1,0) [0|255] ""  SRR_RR
 SG_ SRR_RR_DiagReqData23 : 191|8@0+ (1,0) [0|255] ""  SRR_RR
 SG_ SRR_RR_DiagReqData24 : 199|8@0+ (1,0) [0|255] ""  SRR_RR
 SG_ SRR_RR_DiagReqData25 : 207|8@0+ (1,0) [0|255] ""  SRR_RR
 SG_ SRR_RR_DiagReqData26 : 215|8@0+ (1,0) [0|255] ""  SRR_RR
 SG_ SRR_RR_DiagReqData27 : 223|8@0+ (1,0) [0|255] ""  SRR_RR
 SG_ SRR_RR_DiagReqData28 : 231|8@0+ (1,0) [0|255] ""  SRR_RR
 SG_ SRR_RR_DiagReqData29 : 239|8@0+ (1,0) [0|255] ""  SRR_RR
 SG_ SRR_RR_DiagReqData30 : 247|8@0+ (1,0) [0|255] ""  SRR_RR
 SG_ SRR_RR_DiagReqData31 : 255|8@0+ (1,0) [0|255] ""  SRR_RR
 SG_ SRR_RR_DiagReqData32 : 263|8@0+ (1,0) [0|255] ""  SRR_RR
 SG_ SRR_RR_DiagReqData33 : 271|8@0+ (1,0) [0|255] ""  SRR_RR
 SG_ SRR_RR_DiagReqData34 : 279|8@0+ (1,0) [0|255] ""  SRR_RR
 SG_ SRR_RR_DiagReqData35 : 287|8@0+ (1,0) [0|255] ""  SRR_RR
 SG_ SRR_RR_DiagReqData36 : 295|8@0+ (1,0) [0|255] ""  SRR_RR
 SG_ SRR_RR_DiagReqData37 : 303|8@0+ (1,0) [0|255] ""  SRR_RR
 SG_ SRR_RR_DiagReqData38 : 311|8@0+ (1,0) [0|255] ""  SRR_RR
 SG_ SRR_RR_DiagReqData39 : 319|8@0+ (1,0) [0|255] ""  SRR_RR
 SG_ SRR_RR_DiagReqData40 : 327|8@0+ (1,0) [0|255] ""  SRR_RR
 SG_ SRR_RR_DiagReqData41 : 335|8@0+ (1,0) [0|255] ""  SRR_RR
 SG_ SRR_RR_DiagReqData42 : 343|8@0+ (1,0) [0|255] ""  SRR_RR
 SG_ SRR_RR_DiagReqData43 : 351|8@0+ (1,0) [0|255] ""  SRR_RR
 SG_ SRR_RR_DiagReqData44 : 359|8@0+ (1,0) [0|255] ""  SRR_RR
 SG_ SRR_RR_DiagReqData45 : 367|8@0+ (1,0) [0|255] ""  SRR_RR
 SG_ SRR_RR_DiagReqData46 : 375|8@0+ (1,0) [0|255] ""  SRR_RR
 SG_ SRR_RR_DiagReqData47 : 383|8@0+ (1,0) [0|255] ""  SRR_RR
 SG_ SRR_RR_DiagReqData48 : 391|8@0+ (1,0) [0|255] ""  SRR_RR
 SG_ SRR_RR_DiagReqData49 : 399|8@0+ (1,0) [0|255] ""  SRR_RR
 SG_ SRR_RR_DiagReqData50 : 407|8@0+ (1,0) [0|255] ""  SRR_RR
 SG_ SRR_RR_DiagReqData51 : 415|8@0+ (1,0) [0|255] ""  SRR_RR
 SG_ SRR_RR_DiagReqData52 : 423|8@0+ (1,0) [0|255] ""  SRR_RR
 SG_ SRR_RR_DiagReqData53 : 431|8@0+ (1,0) [0|255] ""  SRR_RR
 SG_ SRR_RR_DiagReqData54 : 439|8@0+ (1,0) [0|255] ""  SRR_RR
 SG_ SRR_RR_DiagReqData55 : 447|8@0+ (1,0) [0|255] ""  SRR_RR
 SG_ SRR_RR_DiagReqData56 : 455|8@0+ (1,0) [0|255] ""  SRR_RR
 SG_ SRR_RR_DiagReqData57 : 463|8@0+ (1,0) [0|255] ""  SRR_RR
 SG_ SRR_RR_DiagReqData58 : 471|8@0+ (1,0) [0|255] ""  SRR_RR
 SG_ SRR_RR_DiagReqData59 : 479|8@0+ (1,0) [0|255] ""  SRR_RR
 SG_ SRR_RR_DiagReqData60 : 487|8@0+ (1,0) [0|255] ""  SRR_RR
 SG_ SRR_RR_DiagReqData61 : 495|8@0+ (1,0) [0|255] ""  SRR_RR
 SG_ SRR_RR_DiagReqData62 : 503|8@0+ (1,0) [0|255] ""  SRR_RR
 SG_ SRR_RR_DiagReqData63 : 511|8@0+ (1,0) [0|255] ""  SRR_RR

BO_ 1590 SRR_RR_DiagResp: 64 SRR_RR
 SG_ SRR_RR_DiagRespData0 : 7|8@0+ (1,0) [0|255] ""  CVC_I
 SG_ SRR_RR_DiagRespData1 : 15|8@0+ (1,0) [0|255] ""  CVC_I
 SG_ SRR_RR_DiagRespData2 : 23|8@0+ (1,0) [0|255] ""  CVC_I
 SG_ SRR_RR_DiagRespData3 : 31|8@0+ (1,0) [0|255] ""  CVC_I
 SG_ SRR_RR_DiagRespData4 : 39|8@0+ (1,0) [0|255] ""  CVC_I
 SG_ SRR_RR_DiagRespData5 : 47|8@0+ (1,0) [0|255] ""  CVC_I
 SG_ SRR_RR_DiagRespData6 : 55|8@0+ (1,0) [0|255] ""  CVC_I
 SG_ SRR_RR_DiagRespData7 : 63|8@0+ (1,0) [0|255] ""  CVC_I
 SG_ SRR_RR_DiagRespData8 : 71|8@0+ (1,0) [0|255] ""  CVC_I
 SG_ SRR_RR_DiagRespData9 : 79|8@0+ (1,0) [0|255] ""  CVC_I
 SG_ SRR_RR_DiagRespData10 : 87|8@0+ (1,0) [0|255] ""  CVC_I
 SG_ SRR_RR_DiagRespData11 : 95|8@0+ (1,0) [0|255] ""  CVC_I
 SG_ SRR_RR_DiagRespData12 : 103|8@0+ (1,0) [0|255] ""  CVC_I
 SG_ SRR_RR_DiagRespData13 : 111|8@0+ (1,0) [0|255] ""  CVC_I
 SG_ SRR_RR_DiagRespData14 : 119|8@0+ (1,0) [0|255] ""  CVC_I
 SG_ SRR_RR_DiagRespData15 : 127|8@0+ (1,0) [0|255] ""  CVC_I
 SG_ SRR_RR_DiagRespData16 : 135|8@0+ (1,0) [0|255] ""  CVC_I
 SG_ SRR_RR_DiagRespData17 : 143|8@0+ (1,0) [0|255] ""  CVC_I
 SG_ SRR_RR_DiagRespData18 : 151|8@0+ (1,0) [0|255] ""  CVC_I
 SG_ SRR_RR_DiagRespData19 : 159|8@0+ (1,0) [0|255] ""  CVC_I
 SG_ SRR_RR_DiagRespData20 : 167|8@0+ (1,0) [0|255] ""  CVC_I
 SG_ SRR_RR_DiagRespData21 : 175|8@0+ (1,0) [0|255] ""  CVC_I
 SG_ SRR_RR_DiagRespData22 : 183|8@0+ (1,0) [0|255] ""  CVC_I
 SG_ SRR_RR_DiagRespData23 : 191|8@0+ (1,0) [0|255] ""  CVC_I
 SG_ SRR_RR_DiagRespData24 : 199|8@0+ (1,0) [0|255] ""  CVC_I
 SG_ SRR_RR_DiagRespData25 : 207|8@0+ (1,0) [0|255] ""  CVC_I
 SG_ SRR_RR_DiagRespData26 : 215|8@0+ (1,0) [0|255] ""  CVC_I
 SG_ SRR_RR_DiagRespData27 : 223|8@0+ (1,0) [0|255] ""  CVC_I
 SG_ SRR_RR_DiagRespData28 : 231|8@0+ (1,0) [0|255] ""  CVC_I
 SG_ SRR_RR_DiagRespData29 : 239|8@0+ (1,0) [0|255] ""  CVC_I
 SG_ SRR_RR_DiagRespData30 : 247|8@0+ (1,0) [0|255] ""  CVC_I
 SG_ SRR_RR_DiagRespData31 : 255|8@0+ (1,0) [0|255] ""  CVC_I
 SG_ SRR_RR_DiagRespData32 : 263|8@0+ (1,0) [0|255] ""  CVC_I
 SG_ SRR_RR_DiagRespData33 : 271|8@0+ (1,0) [0|255] ""  CVC_I
 SG_ SRR_RR_DiagRespData34 : 279|8@0+ (1,0) [0|255] ""  CVC_I
 SG_ SRR_RR_DiagRespData35 : 287|8@0+ (1,0) [0|255] ""  CVC_I
 SG_ SRR_RR_DiagRespData36 : 295|8@0+ (1,0) [0|255] ""  CVC_I
 SG_ SRR_RR_DiagRespData37 : 303|8@0+ (1,0) [0|255] ""  CVC_I
 SG_ SRR_RR_DiagRespData38 : 311|8@0+ (1,0) [0|255] ""  CVC_I
 SG_ SRR_RR_DiagRespData39 : 319|8@0+ (1,0) [0|255] ""  CVC_I
 SG_ SRR_RR_DiagRespData40 : 327|8@0+ (1,0) [0|255] ""  CVC_I
 SG_ SRR_RR_DiagRespData41 : 335|8@0+ (1,0) [0|255] ""  CVC_I
 SG_ SRR_RR_DiagRespData42 : 343|8@0+ (1,0) [0|255] ""  CVC_I
 SG_ SRR_RR_DiagRespData43 : 351|8@0+ (1,0) [0|255] ""  CVC_I
 SG_ SRR_RR_DiagRespData44 : 359|8@0+ (1,0) [0|255] ""  CVC_I
 SG_ SRR_RR_DiagRespData45 : 367|8@0+ (1,0) [0|255] ""  CVC_I
 SG_ SRR_RR_DiagRespData46 : 375|8@0+ (1,0) [0|255] ""  CVC_I
 SG_ SRR_RR_DiagRespData47 : 383|8@0+ (1,0) [0|255] ""  CVC_I
 SG_ SRR_RR_DiagRespData48 : 391|8@0+ (1,0) [0|255] ""  CVC_I
 SG_ SRR_RR_DiagRespData49 : 399|8@0+ (1,0) [0|255] ""  CVC_I
 SG_ SRR_RR_DiagRespData50 : 407|8@0+ (1,0) [0|255] ""  CVC_I
 SG_ SRR_RR_DiagRespData51 : 415|8@0+ (1,0) [0|255] ""  CVC_I
 SG_ SRR_RR_DiagRespData52 : 423|8@0+ (1,0) [0|255] ""  CVC_I
 SG_ SRR_RR_DiagRespData53 : 431|8@0+ (1,0) [0|255] ""  CVC_I
 SG_ SRR_RR_DiagRespData54 : 439|8@0+ (1,0) [0|255] ""  CVC_I
 SG_ SRR_RR_DiagRespData55 : 447|8@0+ (1,0) [0|255] ""  CVC_I
 SG_ SRR_RR_DiagRespData56 : 455|8@0+ (1,0) [0|255] ""  CVC_I
 SG_ SRR_RR_DiagRespData57 : 463|8@0+ (1,0) [0|255] ""  CVC_I
 SG_ SRR_RR_DiagRespData58 : 471|8@0+ (1,0) [0|255] ""  CVC_I
 SG_ SRR_RR_DiagRespData59 : 479|8@0+ (1,0) [0|255] ""  CVC_I
 SG_ SRR_RR_DiagRespData60 : 487|8@0+ (1,0) [0|255] ""  CVC_I
 SG_ SRR_RR_DiagRespData61 : 495|8@0+ (1,0) [0|255] ""  CVC_I
 SG_ SRR_RR_DiagRespData62 : 503|8@0+ (1,0) [0|255] ""  CVC_I
 SG_ SRR_RR_DiagRespData63 : 511|8@0+ (1,0) [0|255] ""  CVC_I

BO_ 1717 SRR_FL_DiagReq: 64 CVC_I
 SG_ SRR_FL_DiagReqData0 : 7|8@0+ (1,0) [0|255] ""  SRR_FL
 SG_ SRR_FL_DiagReqData1 : 15|8@0+ (1,0) [0|255] ""  SRR_FL
 SG_ SRR_FL_DiagReqData2 : 23|8@0+ (1,0) [0|255] ""  SRR_FL
 SG_ SRR_FL_DiagReqData3 : 31|8@0+ (1,0) [0|255] ""  SRR_FL
 SG_ SRR_FL_DiagReqData4 : 39|8@0+ (1,0) [0|255] ""  SRR_FL
 SG_ SRR_FL_DiagReqData5 : 47|8@0+ (1,0) [0|255] ""  SRR_FL
 SG_ SRR_FL_DiagReqData6 : 55|8@0+ (1,0) [0|255] ""  SRR_FL
 SG_ SRR_FL_DiagReqData7 : 63|8@0+ (1,0) [0|255] ""  SRR_FL
 SG_ SRR_FL_DiagReqData8 : 71|8@0+ (1,0) [0|255] ""  SRR_FL
 SG_ SRR_FL_DiagReqData9 : 79|8@0+ (1,0) [0|255] ""  SRR_FL
 SG_ SRR_FL_DiagReqData10 : 87|8@0+ (1,0) [0|255] ""  SRR_FL
 SG_ SRR_FL_DiagReqData11 : 95|8@0+ (1,0) [0|255] ""  SRR_FL
 SG_ SRR_FL_DiagReqData12 : 103|8@0+ (1,0) [0|255] ""  SRR_FL
 SG_ SRR_FL_DiagReqData13 : 111|8@0+ (1,0) [0|255] ""  SRR_FL
 SG_ SRR_FL_DiagReqData14 : 119|8@0+ (1,0) [0|255] ""  SRR_FL
 SG_ SRR_FL_DiagReqData15 : 127|8@0+ (1,0) [0|255] ""  SRR_FL
 SG_ SRR_FL_DiagReqData16 : 135|8@0+ (1,0) [0|255] ""  SRR_FL
 SG_ SRR_FL_DiagReqData17 : 143|8@0+ (1,0) [0|255] ""  SRR_FL
 SG_ SRR_FL_DiagReqData18 : 151|8@0+ (1,0) [0|255] ""  SRR_FL
 SG_ SRR_FL_DiagReqData19 : 159|8@0+ (1,0) [0|255] ""  SRR_FL
 SG_ SRR_FL_DiagReqData20 : 167|8@0+ (1,0) [0|255] ""  SRR_FL
 SG_ SRR_FL_DiagReqData21 : 175|8@0+ (1,0) [0|255] ""  SRR_FL
 SG_ SRR_FL_DiagReqData22 : 183|8@0+ (1,0) [0|255] ""  SRR_FL
 SG_ SRR_FL_DiagReqData23 : 191|8@0+ (1,0) [0|255] ""  SRR_FL
 SG_ SRR_FL_DiagReqData24 : 199|8@0+ (1,0) [0|255] ""  SRR_FL
 SG_ SRR_FL_DiagReqData25 : 207|8@0+ (1,0) [0|255] ""  SRR_FL
 SG_ SRR_FL_DiagReqData26 : 215|8@0+ (1,0) [0|255] ""  SRR_FL
 SG_ SRR_FL_DiagReqData27 : 223|8@0+ (1,0) [0|255] ""  SRR_FL
 SG_ SRR_FL_DiagReqData28 : 231|8@0+ (1,0) [0|255] ""  SRR_FL
 SG_ SRR_FL_DiagReqData29 : 239|8@0+ (1,0) [0|255] ""  SRR_FL
 SG_ SRR_FL_DiagReqData30 : 247|8@0+ (1,0) [0|255] ""  SRR_FL
 SG_ SRR_FL_DiagReqData31 : 255|8@0+ (1,0) [0|255] ""  SRR_FL
 SG_ SRR_FL_DiagReqData32 : 263|8@0+ (1,0) [0|255] ""  SRR_FL
 SG_ SRR_FL_DiagReqData33 : 271|8@0+ (1,0) [0|255] ""  SRR_FL
 SG_ SRR_FL_DiagReqData34 : 279|8@0+ (1,0) [0|255] ""  SRR_FL
 SG_ SRR_FL_DiagReqData35 : 287|8@0+ (1,0) [0|255] ""  SRR_FL
 SG_ SRR_FL_DiagReqData36 : 295|8@0+ (1,0) [0|255] ""  SRR_FL
 SG_ SRR_FL_DiagReqData37 : 303|8@0+ (1,0) [0|255] ""  SRR_FL
 SG_ SRR_FL_DiagReqData38 : 311|8@0+ (1,0) [0|255] ""  SRR_FL
 SG_ SRR_FL_DiagReqData39 : 319|8@0+ (1,0) [0|255] ""  SRR_FL
 SG_ SRR_FL_DiagReqData40 : 327|8@0+ (1,0) [0|255] ""  SRR_FL
 SG_ SRR_FL_DiagReqData41 : 335|8@0+ (1,0) [0|255] ""  SRR_FL
 SG_ SRR_FL_DiagReqData42 : 343|8@0+ (1,0) [0|255] ""  SRR_FL
 SG_ SRR_FL_DiagReqData43 : 351|8@0+ (1,0) [0|255] ""  SRR_FL
 SG_ SRR_FL_DiagReqData44 : 359|8@0+ (1,0) [0|255] ""  SRR_FL
 SG_ SRR_FL_DiagReqData45 : 367|8@0+ (1,0) [0|255] ""  SRR_FL
 SG_ SRR_FL_DiagReqData46 : 375|8@0+ (1,0) [0|255] ""  SRR_FL
 SG_ SRR_FL_DiagReqData47 : 383|8@0+ (1,0) [0|255] ""  SRR_FL
 SG_ SRR_FL_DiagReqData48 : 391|8@0+ (1,0) [0|255] ""  SRR_FL
 SG_ SRR_FL_DiagReqData49 : 399|8@0+ (1,0) [0|255] ""  SRR_FL
 SG_ SRR_FL_DiagReqData50 : 407|8@0+ (1,0) [0|255] ""  SRR_FL
 SG_ SRR_FL_DiagReqData51 : 415|8@0+ (1,0) [0|255] ""  SRR_FL
 SG_ SRR_FL_DiagReqData52 : 423|8@0+ (1,0) [0|255] ""  SRR_FL
 SG_ SRR_FL_DiagReqData53 : 431|8@0+ (1,0) [0|255] ""  SRR_FL
 SG_ SRR_FL_DiagReqData54 : 439|8@0+ (1,0) [0|255] ""  SRR_FL
 SG_ SRR_FL_DiagReqData55 : 447|8@0+ (1,0) [0|255] ""  SRR_FL
 SG_ SRR_FL_DiagReqData56 : 455|8@0+ (1,0) [0|255] ""  SRR_FL
 SG_ SRR_FL_DiagReqData57 : 463|8@0+ (1,0) [0|255] ""  SRR_FL
 SG_ SRR_FL_DiagReqData58 : 471|8@0+ (1,0) [0|255] ""  SRR_FL
 SG_ SRR_FL_DiagReqData59 : 479|8@0+ (1,0) [0|255] ""  SRR_FL
 SG_ SRR_FL_DiagReqData60 : 487|8@0+ (1,0) [0|255] ""  SRR_FL
 SG_ SRR_FL_DiagReqData61 : 495|8@0+ (1,0) [0|255] ""  SRR_FL
 SG_ SRR_FL_DiagReqData62 : 503|8@0+ (1,0) [0|255] ""  SRR_FL
 SG_ SRR_FL_DiagReqData63 : 511|8@0+ (1,0) [0|255] ""  SRR_FL

BO_ 1589 SRR_FL_DiagResp: 64 SRR_FL
 SG_ SRR_FL_DiagRespData0 : 7|8@0+ (1,0) [0|255] ""  CVC_I
 SG_ SRR_FL_DiagRespData1 : 15|8@0+ (1,0) [0|255] ""  CVC_I
 SG_ SRR_FL_DiagRespData2 : 23|8@0+ (1,0) [0|255] ""  CVC_I
 SG_ SRR_FL_DiagRespData3 : 31|8@0+ (1,0) [0|255] ""  CVC_I
 SG_ SRR_FL_DiagRespData4 : 39|8@0+ (1,0) [0|255] ""  CVC_I
 SG_ SRR_FL_DiagRespData5 : 47|8@0+ (1,0) [0|255] ""  CVC_I
 SG_ SRR_FL_DiagRespData6 : 55|8@0+ (1,0) [0|255] ""  CVC_I
 SG_ SRR_FL_DiagRespData7 : 63|8@0+ (1,0) [0|255] ""  CVC_I
 SG_ SRR_FL_DiagRespData8 : 71|8@0+ (1,0) [0|255] ""  CVC_I
 SG_ SRR_FL_DiagRespData9 : 79|8@0+ (1,0) [0|255] ""  CVC_I
 SG_ SRR_FL_DiagRespData10 : 87|8@0+ (1,0) [0|255] ""  CVC_I
 SG_ SRR_FL_DiagRespData11 : 95|8@0+ (1,0) [0|255] ""  CVC_I
 SG_ SRR_FL_DiagRespData12 : 103|8@0+ (1,0) [0|255] ""  CVC_I
 SG_ SRR_FL_DiagRespData13 : 111|8@0+ (1,0) [0|255] ""  CVC_I
 SG_ SRR_FL_DiagRespData14 : 119|8@0+ (1,0) [0|255] ""  CVC_I
 SG_ SRR_FL_DiagRespData15 : 127|8@0+ (1,0) [0|255] ""  CVC_I
 SG_ SRR_FL_DiagRespData16 : 135|8@0+ (1,0) [0|255] ""  CVC_I
 SG_ SRR_FL_DiagRespData17 : 143|8@0+ (1,0) [0|255] ""  CVC_I
 SG_ SRR_FL_DiagRespData18 : 151|8@0+ (1,0) [0|255] ""  CVC_I
 SG_ SRR_FL_DiagRespData19 : 159|8@0+ (1,0) [0|255] ""  CVC_I
 SG_ SRR_FL_DiagRespData20 : 167|8@0+ (1,0) [0|255] ""  CVC_I
 SG_ SRR_FL_DiagRespData21 : 175|8@0+ (1,0) [0|255] ""  CVC_I
 SG_ SRR_FL_DiagRespData22 : 183|8@0+ (1,0) [0|255] ""  CVC_I
 SG_ SRR_FL_DiagRespData23 : 191|8@0+ (1,0) [0|255] ""  CVC_I
 SG_ SRR_FL_DiagRespData24 : 199|8@0+ (1,0) [0|255] ""  CVC_I
 SG_ SRR_FL_DiagRespData25 : 207|8@0+ (1,0) [0|255] ""  CVC_I
 SG_ SRR_FL_DiagRespData26 : 215|8@0+ (1,0) [0|255] ""  CVC_I
 SG_ SRR_FL_DiagRespData27 : 223|8@0+ (1,0) [0|255] ""  CVC_I
 SG_ SRR_FL_DiagRespData28 : 231|8@0+ (1,0) [0|255] ""  CVC_I
 SG_ SRR_FL_DiagRespData29 : 239|8@0+ (1,0) [0|255] ""  CVC_I
 SG_ SRR_FL_DiagRespData30 : 247|8@0+ (1,0) [0|255] ""  CVC_I
 SG_ SRR_FL_DiagRespData31 : 255|8@0+ (1,0) [0|255] ""  CVC_I
 SG_ SRR_FL_DiagRespData32 : 263|8@0+ (1,0) [0|255] ""  CVC_I
 SG_ SRR_FL_DiagRespData33 : 271|8@0+ (1,0) [0|255] ""  CVC_I
 SG_ SRR_FL_DiagRespData34 : 279|8@0+ (1,0) [0|255] ""  CVC_I
 SG_ SRR_FL_DiagRespData35 : 287|8@0+ (1,0) [0|255] ""  CVC_I
 SG_ SRR_FL_DiagRespData36 : 295|8@0+ (1,0) [0|255] ""  CVC_I
 SG_ SRR_FL_DiagRespData37 : 303|8@0+ (1,0) [0|255] ""  CVC_I
 SG_ SRR_FL_DiagRespData38 : 311|8@0+ (1,0) [0|255] ""  CVC_I
 SG_ SRR_FL_DiagRespData39 : 319|8@0+ (1,0) [0|255] ""  CVC_I
 SG_ SRR_FL_DiagRespData40 : 327|8@0+ (1,0) [0|255] ""  CVC_I
 SG_ SRR_FL_DiagRespData41 : 335|8@0+ (1,0) [0|255] ""  CVC_I
 SG_ SRR_FL_DiagRespData42 : 343|8@0+ (1,0) [0|255] ""  CVC_I
 SG_ SRR_FL_DiagRespData43 : 351|8@0+ (1,0) [0|255] ""  CVC_I
 SG_ SRR_FL_DiagRespData44 : 359|8@0+ (1,0) [0|255] ""  CVC_I
 SG_ SRR_FL_DiagRespData45 : 367|8@0+ (1,0) [0|255] ""  CVC_I
 SG_ SRR_FL_DiagRespData46 : 375|8@0+ (1,0) [0|255] ""  CVC_I
 SG_ SRR_FL_DiagRespData47 : 383|8@0+ (1,0) [0|255] ""  CVC_I
 SG_ SRR_FL_DiagRespData48 : 391|8@0+ (1,0) [0|255] ""  CVC_I
 SG_ SRR_FL_DiagRespData49 : 399|8@0+ (1,0) [0|255] ""  CVC_I
 SG_ SRR_FL_DiagRespData50 : 407|8@0+ (1,0) [0|255] ""  CVC_I
 SG_ SRR_FL_DiagRespData51 : 415|8@0+ (1,0) [0|255] ""  CVC_I
 SG_ SRR_FL_DiagRespData52 : 423|8@0+ (1,0) [0|255] ""  CVC_I
 SG_ SRR_FL_DiagRespData53 : 431|8@0+ (1,0) [0|255] ""  CVC_I
 SG_ SRR_FL_DiagRespData54 : 439|8@0+ (1,0) [0|255] ""  CVC_I
 SG_ SRR_FL_DiagRespData55 : 447|8@0+ (1,0) [0|255] ""  CVC_I
 SG_ SRR_FL_DiagRespData56 : 455|8@0+ (1,0) [0|255] ""  CVC_I
 SG_ SRR_FL_DiagRespData57 : 463|8@0+ (1,0) [0|255] ""  CVC_I
 SG_ SRR_FL_DiagRespData58 : 471|8@0+ (1,0) [0|255] ""  CVC_I
 SG_ SRR_FL_DiagRespData59 : 479|8@0+ (1,0) [0|255] ""  CVC_I
 SG_ SRR_FL_DiagRespData60 : 487|8@0+ (1,0) [0|255] ""  CVC_I
 SG_ SRR_FL_DiagRespData61 : 495|8@0+ (1,0) [0|255] ""  CVC_I
 SG_ SRR_FL_DiagRespData62 : 503|8@0+ (1,0) [0|255] ""  CVC_I
 SG_ SRR_FL_DiagRespData63 : 511|8@0+ (1,0) [0|255] ""  CVC_I

BO_ 1716 SRR_FR_DiagReq: 64 CVC_I
 SG_ SRR_FR_DiagReqData0 : 7|8@0+ (1,0) [0|255] ""  SRR_FR
 SG_ SRR_FR_DiagReqData1 : 15|8@0+ (1,0) [0|255] ""  SRR_FR
 SG_ SRR_FR_DiagReqData2 : 23|8@0+ (1,0) [0|255] ""  SRR_FR
 SG_ SRR_FR_DiagReqData3 : 31|8@0+ (1,0) [0|255] ""  SRR_FR
 SG_ SRR_FR_DiagReqData4 : 39|8@0+ (1,0) [0|255] ""  SRR_FR
 SG_ SRR_FR_DiagReqData5 : 47|8@0+ (1,0) [0|255] ""  SRR_FR
 SG_ SRR_FR_DiagReqData6 : 55|8@0+ (1,0) [0|255] ""  SRR_FR
 SG_ SRR_FR_DiagReqData7 : 63|8@0+ (1,0) [0|255] ""  SRR_FR
 SG_ SRR_FR_DiagReqData8 : 71|8@0+ (1,0) [0|255] ""  SRR_FR
 SG_ SRR_FR_DiagReqData9 : 79|8@0+ (1,0) [0|255] ""  SRR_FR
 SG_ SRR_FR_DiagReqData10 : 87|8@0+ (1,0) [0|255] ""  SRR_FR
 SG_ SRR_FR_DiagReqData11 : 95|8@0+ (1,0) [0|255] ""  SRR_FR
 SG_ SRR_FR_DiagReqData12 : 103|8@0+ (1,0) [0|255] ""  SRR_FR
 SG_ SRR_FR_DiagReqData13 : 111|8@0+ (1,0) [0|255] ""  SRR_FR
 SG_ SRR_FR_DiagReqData14 : 119|8@0+ (1,0) [0|255] ""  SRR_FR
 SG_ SRR_FR_DiagReqData15 : 127|8@0+ (1,0) [0|255] ""  SRR_FR
 SG_ SRR_FR_DiagReqData16 : 135|8@0+ (1,0) [0|255] ""  SRR_FR
 SG_ SRR_FR_DiagReqData17 : 143|8@0+ (1,0) [0|255] ""  SRR_FR
 SG_ SRR_FR_DiagReqData18 : 151|8@0+ (1,0) [0|255] ""  SRR_FR
 SG_ SRR_FR_DiagReqData19 : 159|8@0+ (1,0) [0|255] ""  SRR_FR
 SG_ SRR_FR_DiagReqData20 : 167|8@0+ (1,0) [0|255] ""  SRR_FR
 SG_ SRR_FR_DiagReqData21 : 175|8@0+ (1,0) [0|255] ""  SRR_FR
 SG_ SRR_FR_DiagReqData22 : 183|8@0+ (1,0) [0|255] ""  SRR_FR
 SG_ SRR_FR_DiagReqData23 : 191|8@0+ (1,0) [0|255] ""  SRR_FR
 SG_ SRR_FR_DiagReqData24 : 199|8@0+ (1,0) [0|255] ""  SRR_FR
 SG_ SRR_FR_DiagReqData25 : 207|8@0+ (1,0) [0|255] ""  SRR_FR
 SG_ SRR_FR_DiagReqData26 : 215|8@0+ (1,0) [0|255] ""  SRR_FR
 SG_ SRR_FR_DiagReqData27 : 223|8@0+ (1,0) [0|255] ""  SRR_FR
 SG_ SRR_FR_DiagReqData28 : 231|8@0+ (1,0) [0|255] ""  SRR_FR
 SG_ SRR_FR_DiagReqData29 : 239|8@0+ (1,0) [0|255] ""  SRR_FR
 SG_ SRR_FR_DiagReqData30 : 247|8@0+ (1,0) [0|255] ""  SRR_FR
 SG_ SRR_FR_DiagReqData31 : 255|8@0+ (1,0) [0|255] ""  SRR_FR
 SG_ SRR_FR_DiagReqData32 : 263|8@0+ (1,0) [0|255] ""  SRR_FR
 SG_ SRR_FR_DiagReqData33 : 271|8@0+ (1,0) [0|255] ""  SRR_FR
 SG_ SRR_FR_DiagReqData34 : 279|8@0+ (1,0) [0|255] ""  SRR_FR
 SG_ SRR_FR_DiagReqData35 : 287|8@0+ (1,0) [0|255] ""  SRR_FR
 SG_ SRR_FR_DiagReqData36 : 295|8@0+ (1,0) [0|255] ""  SRR_FR
 SG_ SRR_FR_DiagReqData37 : 303|8@0+ (1,0) [0|255] ""  SRR_FR
 SG_ SRR_FR_DiagReqData38 : 311|8@0+ (1,0) [0|255] ""  SRR_FR
 SG_ SRR_FR_DiagReqData39 : 319|8@0+ (1,0) [0|255] ""  SRR_FR
 SG_ SRR_FR_DiagReqData40 : 327|8@0+ (1,0) [0|255] ""  SRR_FR
 SG_ SRR_FR_DiagReqData41 : 335|8@0+ (1,0) [0|255] ""  SRR_FR
 SG_ SRR_FR_DiagReqData42 : 343|8@0+ (1,0) [0|255] ""  SRR_FR
 SG_ SRR_FR_DiagReqData43 : 351|8@0+ (1,0) [0|255] ""  SRR_FR
 SG_ SRR_FR_DiagReqData44 : 359|8@0+ (1,0) [0|255] ""  SRR_FR
 SG_ SRR_FR_DiagReqData45 : 367|8@0+ (1,0) [0|255] ""  SRR_FR
 SG_ SRR_FR_DiagReqData46 : 375|8@0+ (1,0) [0|255] ""  SRR_FR
 SG_ SRR_FR_DiagReqData47 : 383|8@0+ (1,0) [0|255] ""  SRR_FR
 SG_ SRR_FR_DiagReqData48 : 391|8@0+ (1,0) [0|255] ""  SRR_FR
 SG_ SRR_FR_DiagReqData49 : 399|8@0+ (1,0) [0|255] ""  SRR_FR
 SG_ SRR_FR_DiagReqData50 : 407|8@0+ (1,0) [0|255] ""  SRR_FR
 SG_ SRR_FR_DiagReqData51 : 415|8@0+ (1,0) [0|255] ""  SRR_FR
 SG_ SRR_FR_DiagReqData52 : 423|8@0+ (1,0) [0|255] ""  SRR_FR
 SG_ SRR_FR_DiagReqData53 : 431|8@0+ (1,0) [0|255] ""  SRR_FR
 SG_ SRR_FR_DiagReqData54 : 439|8@0+ (1,0) [0|255] ""  SRR_FR
 SG_ SRR_FR_DiagReqData55 : 447|8@0+ (1,0) [0|255] ""  SRR_FR
 SG_ SRR_FR_DiagReqData56 : 455|8@0+ (1,0) [0|255] ""  SRR_FR
 SG_ SRR_FR_DiagReqData57 : 463|8@0+ (1,0) [0|255] ""  SRR_FR
 SG_ SRR_FR_DiagReqData58 : 471|8@0+ (1,0) [0|255] ""  SRR_FR
 SG_ SRR_FR_DiagReqData59 : 479|8@0+ (1,0) [0|255] ""  SRR_FR
 SG_ SRR_FR_DiagReqData60 : 487|8@0+ (1,0) [0|255] ""  SRR_FR
 SG_ SRR_FR_DiagReqData61 : 495|8@0+ (1,0) [0|255] ""  SRR_FR
 SG_ SRR_FR_DiagReqData62 : 503|8@0+ (1,0) [0|255] ""  SRR_FR
 SG_ SRR_FR_DiagReqData63 : 511|8@0+ (1,0) [0|255] ""  SRR_FR

BO_ 1588 SRR_FR_DiagResp: 64 SRR_FR
 SG_ SRR_FR_DiagRespData0 : 7|8@0+ (1,0) [0|255] ""  CVC_I
 SG_ SRR_FR_DiagRespData1 : 15|8@0+ (1,0) [0|255] ""  CVC_I
 SG_ SRR_FR_DiagRespData2 : 23|8@0+ (1,0) [0|255] ""  CVC_I
 SG_ SRR_FR_DiagRespData3 : 31|8@0+ (1,0) [0|255] ""  CVC_I
 SG_ SRR_FR_DiagRespData4 : 39|8@0+ (1,0) [0|255] ""  CVC_I
 SG_ SRR_FR_DiagRespData5 : 47|8@0+ (1,0) [0|255] ""  CVC_I
 SG_ SRR_FR_DiagRespData6 : 55|8@0+ (1,0) [0|255] ""  CVC_I
 SG_ SRR_FR_DiagRespData7 : 63|8@0+ (1,0) [0|255] ""  CVC_I
 SG_ SRR_FR_DiagRespData8 : 71|8@0+ (1,0) [0|255] ""  CVC_I
 SG_ SRR_FR_DiagRespData9 : 79|8@0+ (1,0) [0|255] ""  CVC_I
 SG_ SRR_FR_DiagRespData10 : 87|8@0+ (1,0) [0|255] ""  CVC_I
 SG_ SRR_FR_DiagRespData11 : 95|8@0+ (1,0) [0|255] ""  CVC_I
 SG_ SRR_FR_DiagRespData12 : 103|8@0+ (1,0) [0|255] ""  CVC_I
 SG_ SRR_FR_DiagRespData13 : 111|8@0+ (1,0) [0|255] ""  CVC_I
 SG_ SRR_FR_DiagRespData14 : 119|8@0+ (1,0) [0|255] ""  CVC_I
 SG_ SRR_FR_DiagRespData15 : 127|8@0+ (1,0) [0|255] ""  CVC_I
 SG_ SRR_FR_DiagRespData16 : 135|8@0+ (1,0) [0|255] ""  CVC_I
 SG_ SRR_FR_DiagRespData17 : 143|8@0+ (1,0) [0|255] ""  CVC_I
 SG_ SRR_FR_DiagRespData18 : 151|8@0+ (1,0) [0|255] ""  CVC_I
 SG_ SRR_FR_DiagRespData19 : 159|8@0+ (1,0) [0|255] ""  CVC_I
 SG_ SRR_FR_DiagRespData20 : 167|8@0+ (1,0) [0|255] ""  CVC_I
 SG_ SRR_FR_DiagRespData21 : 175|8@0+ (1,0) [0|255] ""  CVC_I
 SG_ SRR_FR_DiagRespData22 : 183|8@0+ (1,0) [0|255] ""  CVC_I
 SG_ SRR_FR_DiagRespData23 : 191|8@0+ (1,0) [0|255] ""  CVC_I
 SG_ SRR_FR_DiagRespData24 : 199|8@0+ (1,0) [0|255] ""  CVC_I
 SG_ SRR_FR_DiagRespData25 : 207|8@0+ (1,0) [0|255] ""  CVC_I
 SG_ SRR_FR_DiagRespData26 : 215|8@0+ (1,0) [0|255] ""  CVC_I
 SG_ SRR_FR_DiagRespData27 : 223|8@0+ (1,0) [0|255] ""  CVC_I
 SG_ SRR_FR_DiagRespData28 : 231|8@0+ (1,0) [0|255] ""  CVC_I
 SG_ SRR_FR_DiagRespData29 : 239|8@0+ (1,0) [0|255] ""  CVC_I
 SG_ SRR_FR_DiagRespData30 : 247|8@0+ (1,0) [0|255] ""  CVC_I
 SG_ SRR_FR_DiagRespData31 : 255|8@0+ (1,0) [0|255] ""  CVC_I
 SG_ SRR_FR_DiagRespData32 : 263|8@0+ (1,0) [0|255] ""  CVC_I
 SG_ SRR_FR_DiagRespData33 : 271|8@0+ (1,0) [0|255] ""  CVC_I
 SG_ SRR_FR_DiagRespData34 : 279|8@0+ (1,0) [0|255] ""  CVC_I
 SG_ SRR_FR_DiagRespData35 : 287|8@0+ (1,0) [0|255] ""  CVC_I
 SG_ SRR_FR_DiagRespData36 : 295|8@0+ (1,0) [0|255] ""  CVC_I
 SG_ SRR_FR_DiagRespData37 : 303|8@0+ (1,0) [0|255] ""  CVC_I
 SG_ SRR_FR_DiagRespData38 : 311|8@0+ (1,0) [0|255] ""  CVC_I
 SG_ SRR_FR_DiagRespData39 : 319|8@0+ (1,0) [0|255] ""  CVC_I
 SG_ SRR_FR_DiagRespData40 : 327|8@0+ (1,0) [0|255] ""  CVC_I
 SG_ SRR_FR_DiagRespData41 : 335|8@0+ (1,0) [0|255] ""  CVC_I
 SG_ SRR_FR_DiagRespData42 : 343|8@0+ (1,0) [0|255] ""  CVC_I
 SG_ SRR_FR_DiagRespData43 : 351|8@0+ (1,0) [0|255] ""  CVC_I
 SG_ SRR_FR_DiagRespData44 : 359|8@0+ (1,0) [0|255] ""  CVC_I
 SG_ SRR_FR_DiagRespData45 : 367|8@0+ (1,0) [0|255] ""  CVC_I
 SG_ SRR_FR_DiagRespData46 : 375|8@0+ (1,0) [0|255] ""  CVC_I
 SG_ SRR_FR_DiagRespData47 : 383|8@0+ (1,0) [0|255] ""  CVC_I
 SG_ SRR_FR_DiagRespData48 : 391|8@0+ (1,0) [0|255] ""  CVC_I
 SG_ SRR_FR_DiagRespData49 : 399|8@0+ (1,0) [0|255] ""  CVC_I
 SG_ SRR_FR_DiagRespData50 : 407|8@0+ (1,0) [0|255] ""  CVC_I
 SG_ SRR_FR_DiagRespData51 : 415|8@0+ (1,0) [0|255] ""  CVC_I
 SG_ SRR_FR_DiagRespData52 : 423|8@0+ (1,0) [0|255] ""  CVC_I
 SG_ SRR_FR_DiagRespData53 : 431|8@0+ (1,0) [0|255] ""  CVC_I
 SG_ SRR_FR_DiagRespData54 : 439|8@0+ (1,0) [0|255] ""  CVC_I
 SG_ SRR_FR_DiagRespData55 : 447|8@0+ (1,0) [0|255] ""  CVC_I
 SG_ SRR_FR_DiagRespData56 : 455|8@0+ (1,0) [0|255] ""  CVC_I
 SG_ SRR_FR_DiagRespData57 : 463|8@0+ (1,0) [0|255] ""  CVC_I
 SG_ SRR_FR_DiagRespData58 : 471|8@0+ (1,0) [0|255] ""  CVC_I
 SG_ SRR_FR_DiagRespData59 : 479|8@0+ (1,0) [0|255] ""  CVC_I
 SG_ SRR_FR_DiagRespData60 : 487|8@0+ (1,0) [0|255] ""  CVC_I
 SG_ SRR_FR_DiagRespData61 : 495|8@0+ (1,0) [0|255] ""  CVC_I
 SG_ SRR_FR_DiagRespData62 : 503|8@0+ (1,0) [0|255] ""  CVC_I
 SG_ SRR_FR_DiagRespData63 : 511|8@0+ (1,0) [0|255] ""  CVC_I

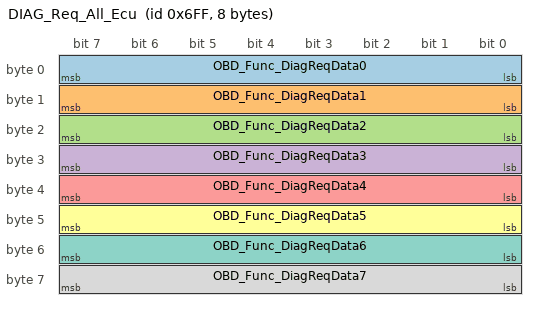
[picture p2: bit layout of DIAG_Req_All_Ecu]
BO_ 1791 DIAG_Req_All_Ecu: 8 CVC_I
 SG_ OBD_Func_DiagReqData0 : 7|8@0+ (1,0) [0|255] ""  MHU,TBOX,FCAM_I,MRR,SRR_RL,SRR_RR,SRR_FL,SRR_FR,ADCU_I,AMP,HUD
 SG_ OBD_Func_DiagReqData1 : 15|8@0+ (1,0) [0|255] ""  MHU,TBOX,FCAM_I,MRR,SRR_RL,SRR_RR,SRR_FL,SRR_FR,ADCU_I,AMP,HUD
 SG_ OBD_Func_DiagReqData2 : 23|8@0+ (1,0) [0|255] ""  MHU,TBOX,FCAM_I,MRR,SRR_RL,SRR_RR,SRR_FL,SRR_FR,ADCU_I,AMP,HUD
 SG_ OBD_Func_DiagReqData3 : 31|8@0+ (1,0) [0|255] ""  MHU,TBOX,FCAM_I,MRR,SRR_RL,SRR_RR,SRR_FL,SRR_FR,ADCU_I,AMP,HUD
 SG_ OBD_Func_DiagReqData4 : 39|8@0+ (1,0) [0|255] ""  MHU,TBOX,FCAM_I,MRR,SRR_RL,SRR_RR,SRR_FL,SRR_FR,ADCU_I,AMP,HUD
 SG_ OBD_Func_DiagReqData5 : 47|8@0+ (1,0) [0|255] ""  MHU,TBOX,FCAM_I,MRR,SRR_RL,SRR_RR,SRR_FL,SRR_FR,ADCU_I,AMP,HUD
 SG_ OBD_Func_DiagReqData6 : 55|8@0+ (1,0) [0|255] ""  MHU,TBOX,FCAM_I,MRR,SRR_RL,SRR_RR,SRR_FL,SRR_FR,ADCU_I,AMP,HUD
 SG_ OBD_Func_DiagReqData7 : 63|8@0+ (1,0) [0|255] ""  MHU,TBOX,FCAM_I,MRR,SRR_RL,SRR_RR,SRR_FL,SRR_FR,ADCU_I,AMP,HUD

CM_ SG_ 1282 CVC_srcNodeID "Network Management Signal";
CM_ SG_ 1282 CVC_CtrlBitVector "Network Management Signal";
CM_ SG_ 1282 CVC_usrData0 "Network Management Signal";
CM_ SG_ 1282 CVC_usrData1 "Network Management Signal";
CM_ SG_ 1282 CVC_usrData2 "Network Management Signal";
CM_ SG_ 1282 CVC_usrData3 "Network Management Signal";
CM_ SG_ 1282 CVC_usrData4 "Network Management Signal";
CM_ SG_ 1282 CVC_usrData5 "Network Management Signal";
CM_ SG_ 1284 MHU_srcNodeID "Network Management Signal";
CM_ SG_ 1284 MHU_CtrlBitVector "Network Management Signal";
CM_ SG_ 1284 MHU_usrData0 "Network Management Signal";
CM_ SG_ 1284 MHU_usrData1 "Network Management Signal";
CM_ SG_ 1284 MHU_usrData2 "Network Management Signal";
CM_ SG_ 1284 MHU_usrData3 "Network Management Signal";
CM_ SG_ 1284 MHU_usrData4 "Network Management Signal";
CM_ SG_ 1284 MHU_usrData5 "Network Management Signal";
CM_ SG_ 1285 AMP_srcNodeID "Network Management Signal";
CM_ SG_ 1285 AMP_CtrlBitVector "Network Management Signal";
CM_ SG_ 1285 AMP_userData0 "Network Management Signal";
CM_ SG_ 1285 AMP_userData1 "Network Management Signal";
CM_ SG_ 1285 AMP_userData2 "Network Management Signal";
CM_ SG_ 1285 AMP_userData3 "Network Management Signal";
CM_ SG_ 1285 AMP_userData4 "Network Management Signal";
CM_ SG_ 1285 AMP_userData5 "Network Management Signal";
CM_ SG_ 1290 TBOX_srcNodeID "Network Management Signal";
CM_ SG_ 1290 TBOX_CtrlBitVector "Network Management Signal";
CM_ SG_ 1290 TBOX_usrData0 "Network Management Signal";
CM_ SG_ 1290 TBOX_usrData1 "Network Management Signal";
CM_ SG_ 1290 TBOX_usrData2 "Network Management Signal";
CM_ SG_ 1290 TBOX_usrData3 "Network Management Signal";
CM_ SG_ 1290 TBOX_usrData4 "Network Management Signal";
CM_ SG_ 1290 TBOX_usrData5 "Network Management Signal";
CM_ SG_ 1674 TBOX_DiagReqData0 "Diagnostic signal Data request";
CM_ SG_ 1674 TBOX_DiagReqData1 "Diagnostic signal Data request";
CM_ SG_ 1674 TBOX_DiagReqData2 "Diagnostic signal Data request";
CM_ SG_ 1674 TBOX_DiagReqData3 "Diagnostic signal Data request";
CM_ SG_ 1674 TBOX_DiagReqData4 "Diagnostic signal Data request";
CM_ SG_ 1674 TBOX_DiagReqData5 "Diagnostic signal Data request";
CM_ SG_ 1674 TBOX_DiagReqData6 "Diagnostic signal Data request";
CM_ SG_ 1674 TBOX_DiagReqData7 "Diagnostic signal Data request";
CM_ SG_ 1546 TBOX_DiagRespData0 "Diagnostic signal Data response";
CM_ SG_ 1546 TBOX_DiagRespData1 "Diagnostic signal Data response";
CM_ SG_ 1546 TBOX_DiagRespData2 "Diagnostic signal Data response";
CM_ SG_ 1546 TBOX_DiagRespData3 "Diagnostic signal Data response";
CM_ SG_ 1546 TBOX_DiagRespData4 "Diagnostic signal Data response";
CM_ SG_ 1546 TBOX_DiagRespData5 "Diagnostic signal Data response";
CM_ SG_ 1546 TBOX_DiagRespData6 "Diagnostic signal Data response";
CM_ SG_ 1546 TBOX_DiagRespData7 "Diagnostic signal Data response";
CM_ SG_ 1541 AMP_DiagRespData0 "Diagnostic signal Data response";
CM_ SG_ 1541 AMP_DiagRespData1 "Diagnostic signal Data response";
CM_ SG_ 1541 AMP_DiagRespData2 "Diagnostic signal Data response";
CM_ SG_ 1541 AMP_DiagRespData3 "Diagnostic signal Data response";
CM_ SG_ 1541 AMP_DiagRespData4 "Diagnostic signal Data response";
CM_ SG_ 1541 AMP_DiagRespData5 "Diagnostic signal Data response";
CM_ SG_ 1541 AMP_DiagRespData6 "Diagnostic signal Data response";
CM_ SG_ 1541 AMP_DiagRespData7 "Diagnostic signal Data response";
CM_ SG_ 1541 AMP_DiagRespData8 "Diagnostic signal Data response";
CM_ SG_ 1541 AMP_DiagRespData9 "Diagnostic signal Data response";
CM_ SG_ 1541 AMP_DiagRespData10 "Diagnostic signal Data response";
CM_ SG_ 1541 AMP_DiagRespData11 "Diagnostic signal Data response";
CM_ SG_ 1541 AMP_DiagRespData12 "Diagnostic signal Data response";
CM_ SG_ 1541 AMP_DiagRespData13 "Diagnostic signal Data response";
CM_ SG_ 1541 AMP_DiagRespData14 "Diagnostic signal Data response";
CM_ SG_ 1541 AMP_DiagRespData15 "Diagnostic signal Data response";
CM_ SG_ 1541 AMP_DiagRespData16 "Diagnostic signal Data response";
CM_ SG_ 1541 AMP_DiagRespData17 "Diagnostic signal Data response";
CM_ SG_ 1541 AMP_DiagRespData18 "Diagnostic signal Data response";
CM_ SG_ 1541 AMP_DiagRespData19 "Diagnostic signal Data response";
CM_ SG_ 1541 AMP_DiagRespData20 "Diagnostic signal Data response";
CM_ SG_ 1541 AMP_DiagRespData21 "Diagnostic signal Data response";
CM_ SG_ 1541 AMP_DiagRespData22 "Diagnostic signal Data response";
CM_ SG_ 1541 AMP_DiagRespData23 "Diagnostic signal Data response";
CM_ SG_ 1541 AMP_DiagRespData24 "Diagnostic signal Data response";
CM_ SG_ 1541 AMP_DiagRespData25 "Diagnostic signal Data response";
CM_ SG_ 1541 AMP_DiagRespData26 "Diagnostic signal Data response";
CM_ SG_ 1541 AMP_DiagRespData27 "Diagnostic signal Data response";
CM_ SG_ 1541 AMP_DiagRespData28 "Diagnostic signal Data response";
CM_ SG_ 1541 AMP_DiagRespData29 "Diagnostic signal Data response";
CM_ SG_ 1541 AMP_DiagRespData30 "Diagnostic signal Data response";
CM_ SG_ 1541 AMP_DiagRespData31 "Diagnostic signal Data response";
CM_ SG_ 1541 AMP_DiagRespData32 "Diagnostic signal Data response";
CM_ SG_ 1541 AMP_DiagRespData33 "Diagnostic signal Data response";
CM_ SG_ 1541 AMP_DiagRespData34 "Diagnostic signal Data response";
CM_ SG_ 1541 AMP_DiagRespData35 "Diagnostic signal Data response";
CM_ SG_ 1541 AMP_DiagRespData36 "Diagnostic signal Data response";
CM_ SG_ 1541 AMP_DiagRespData37 "Diagnostic signal Data response";
CM_ SG_ 1541 AMP_DiagRespData38 "Diagnostic signal Data response";
CM_ SG_ 1541 AMP_DiagRespData39 "Diagnostic signal Data response";
CM_ SG_ 1541 AMP_DiagRespData40 "Diagnostic signal Data response";
CM_ SG_ 1541 AMP_DiagRespData41 "Diagnostic signal Data response";
CM_ SG_ 1541 AMP_DiagRespData42 "Diagnostic signal Data response";
CM_ SG_ 1541 AMP_DiagRespData43 "Diagnostic signal Data response";
CM_ SG_ 1541 AMP_DiagRespData44 "Diagnostic signal Data response";
CM_ SG_ 1541 AMP_DiagRespData45 "Diagnostic signal Data response";
CM_ SG_ 1541 AMP_DiagRespData46 "Diagnostic signal Data response";
CM_ SG_ 1541 AMP_DiagRespData47 "Diagnostic signal Data response";
CM_ SG_ 1541 AMP_DiagRespData48 "Diagnostic signal Data response";
CM_ SG_ 1541 AMP_DiagRespData49 "Diagnostic signal Data response";
CM_ SG_ 1541 AMP_DiagRespData50 "Diagnostic signal Data response";
CM_ SG_ 1541 AMP_DiagRespData51 "Diagnostic signal Data response";
CM_ SG_ 1541 AMP_DiagRespData52 "Diagnostic signal Data response";
CM_ SG_ 1541 AMP_DiagRespData53 "Diagnostic signal Data response";
CM_ SG_ 1541 AMP_DiagRespData54 "Diagnostic signal Data response";
CM_ SG_ 1541 AMP_DiagRespData55 "Diagnostic signal Data response";
CM_ SG_ 1541 AMP_DiagRespData56 "Diagnostic signal Data response";
CM_ SG_ 1541 AMP_DiagRespData57 "Diagnostic signal Data response";
CM_ SG_ 1541 AMP_DiagRespData58 "Diagnostic signal Data response";
CM_ SG_ 1541 AMP_DiagRespData59 "Diagnostic signal Data response";
CM_ SG_ 1541 AMP_DiagRespData60 "Diagnostic signal Data response";
CM_ SG_ 1541 AMP_DiagRespData61 "Diagnostic signal Data response";
CM_ SG_ 1541 AMP_DiagRespData62 "Diagnostic signal Data response";
CM_ SG_ 1541 AMP_DiagRespData63 "Diagnostic signal Data response";
CM_ SG_ 1669 AMP_DiagReqData0 "Diagnostic signal Data request";
CM_ SG_ 1669 AMP_DiagReqData1 "Diagnostic signal Data request";
CM_ SG_ 1669 AMP_DiagReqData2 "Diagnostic signal Data request";
CM_ SG_ 1669 AMP_DiagReqData3 "Diagnostic signal Data request";
CM_ SG_ 1669 AMP_DiagReqData4 "Diagnostic signal Data request";
CM_ SG_ 1669 AMP_DiagReqData5 "Diagnostic signal Data request";
CM_ SG_ 1669 AMP_DiagReqData6 "Diagnostic signal Data request";
CM_ SG_ 1669 AMP_DiagReqData7 "Diagnostic signal Data request";
CM_ SG_ 1669 AMP_DiagReqData8 "Diagnostic signal Data request";
CM_ SG_ 1669 AMP_DiagReqData9 "Diagnostic signal Data request";
CM_ SG_ 1669 AMP_DiagReqData10 "Diagnostic signal Data request";
CM_ SG_ 1669 AMP_DiagReqData11 "Diagnostic signal Data request";
CM_ SG_ 1669 AMP_DiagReqData12 "Diagnostic signal Data request";
CM_ SG_ 1669 AMP_DiagReqData13 "Diagnostic signal Data request";
CM_ SG_ 1669 AMP_DiagReqData14 "Diagnostic signal Data request";
CM_ SG_ 1669 AMP_DiagReqData15 "Diagnostic signal Data request";
CM_ SG_ 1669 AMP_DiagReqData16 "Diagnostic signal Data request";
CM_ SG_ 1669 AMP_DiagReqData17 "Diagnostic signal Data request";
CM_ SG_ 1669 AMP_DiagReqData18 "Diagnostic signal Data request";
CM_ SG_ 1669 AMP_DiagReqData19 "Diagnostic signal Data request";
CM_ SG_ 1669 AMP_DiagReqData20 "Diagnostic signal Data request";
CM_ SG_ 1669 AMP_DiagReqData21 "Diagnostic signal Data request";
CM_ SG_ 1669 AMP_DiagReqData22 "Diagnostic signal Data request";
CM_ SG_ 1669 AMP_DiagReqData23 "Diagnostic signal Data request";
CM_ SG_ 1669 AMP_DiagReqData24 "Diagnostic signal Data request";
CM_ SG_ 1669 AMP_DiagReqData25 "Diagnostic signal Data request";
CM_ SG_ 1669 AMP_DiagReqData26 "Diagnostic signal Data request";
CM_ SG_ 1669 AMP_DiagReqData27 "Diagnostic signal Data request";
CM_ SG_ 1669 AMP_DiagReqData28 "Diagnostic signal Data request";
CM_ SG_ 1669 AMP_DiagReqData29 "Diagnostic signal Data request";
CM_ SG_ 1669 AMP_DiagReqData30 "Diagnostic signal Data request";
CM_ SG_ 1669 AMP_DiagReqData31 "Diagnostic signal Data request";
CM_ SG_ 1669 AMP_DiagReqData32 "Diagnostic signal Data request";
CM_ SG_ 1669 AMP_DiagReqData33 "Diagnostic signal Data request";
CM_ SG_ 1669 AMP_DiagReqData34 "Diagnostic signal Data request";
CM_ SG_ 1669 AMP_DiagReqData35 "Diagnostic signal Data request";
CM_ SG_ 1669 AMP_DiagReqData36 "Diagnostic signal Data request";
CM_ SG_ 1669 AMP_DiagReqData37 "Diagnostic signal Data request";
CM_ SG_ 1669 AMP_DiagReqData38 "Diagnostic signal Data request";
CM_ SG_ 1669 AMP_DiagReqData39 "Diagnostic signal Data request";
CM_ SG_ 1669 AMP_DiagReqData40 "Diagnostic signal Data request";
CM_ SG_ 1669 AMP_DiagReqData41 "Diagnostic signal Data request";
CM_ SG_ 1669 AMP_DiagReqData42 "Diagnostic signal Data request";
CM_ SG_ 1669 AMP_DiagReqData43 "Diagnostic signal Data request";
CM_ SG_ 1669 AMP_DiagReqData44 "Diagnostic signal Data request";
CM_ SG_ 1669 AMP_DiagReqData45 "Diagnostic signal Data request";
CM_ SG_ 1669 AMP_DiagReqData46 "Diagnostic signal Data request";
CM_ SG_ 1669 AMP_DiagReqData47 "Diagnostic signal Data request";
CM_ SG_ 1669 AMP_DiagReqData48 "Diagnostic signal Data request";
CM_ SG_ 1669 AMP_DiagReqData49 "Diagnostic signal Data request";
CM_ SG_ 1669 AMP_DiagReqData50 "Diagnostic signal Data request";
CM_ SG_ 1669 AMP_DiagReqData51 "Diagnostic signal Data request";
CM_ SG_ 1669 AMP_DiagReqData52 "Diagnostic signal Data request";
CM_ SG_ 1669 AMP_DiagReqData53 "Diagnostic signal Data request";
CM_ SG_ 1669 AMP_DiagReqData54 "Diagnostic signal Data request";
CM_ SG_ 1669 AMP_DiagReqData55 "Diagnostic signal Data request";
CM_ SG_ 1669 AMP_DiagReqData56 "Diagnostic signal Data request";
CM_ SG_ 1669 AMP_DiagReqData57 "Diagnostic signal Data request";
CM_ SG_ 1669 AMP_DiagReqData58 "Diagnostic signal Data request";
CM_ SG_ 1669 AMP_DiagReqData59 "Diagnostic signal Data request";
CM_ SG_ 1669 AMP_DiagReqData60 "Diagnostic signal Data request";
CM_ SG_ 1669 AMP_DiagReqData61 "Diagnostic signal Data request";
CM_ SG_ 1669 AMP_DiagReqData62 "Diagnostic signal Data request";
CM_ SG_ 1669 AMP_DiagReqData63 "Diagnostic signal Data request";
CM_ SG_ 1549 HUD_DiagRespData0 "Diagnostic signal Data response";
CM_ SG_ 1549 HUD_DiagRespData1 "Diagnostic signal Data response";
CM_ SG_ 1549 HUD_DiagRespData2 "Diagnostic signal Data response";
CM_ SG_ 1549 HUD_DiagRespData3 "Diagnostic signal Data response";
CM_ SG_ 1549 HUD_DiagRespData4 "Diagnostic signal Data response";
CM_ SG_ 1549 HUD_DiagRespData5 "Diagnostic signal Data response";
CM_ SG_ 1549 HUD_DiagRespData6 "Diagnostic signal Data response";
CM_ SG_ 1549 HUD_DiagRespData7 "Diagnostic signal Data response";
CM_ SG_ 1549 HUD_DiagRespData8 "Diagnostic signal Data response";
CM_ SG_ 1549 HUD_DiagRespData9 "Diagnostic signal Data response";
CM_ SG_ 1549 HUD_DiagRespData10 "Diagnostic signal Data response";
CM_ SG_ 1549 HUD_DiagRespData11 "Diagnostic signal Data response";
CM_ SG_ 1549 HUD_DiagRespData12 "Diagnostic signal Data response";
CM_ SG_ 1549 HUD_DiagRespData13 "Diagnostic signal Data response";
CM_ SG_ 1549 HUD_DiagRespData14 "Diagnostic signal Data response";
CM_ SG_ 1549 HUD_DiagRespData15 "Diagnostic signal Data response";
CM_ SG_ 1549 HUD_DiagRespData16 "Diagnostic signal Data response";
CM_ SG_ 1549 HUD_DiagRespData17 "Diagnostic signal Data response";
CM_ SG_ 1549 HUD_DiagRespData18 "Diagnostic signal Data response";
CM_ SG_ 1549 HUD_DiagRespData19 "Diagnostic signal Data response";
CM_ SG_ 1549 HUD_DiagRespData20 "Diagnostic signal Data response";
CM_ SG_ 1549 HUD_DiagRespData21 "Diagnostic signal Data response";
CM_ SG_ 1549 HUD_DiagRespData22 "Diagnostic signal Data response";
CM_ SG_ 1549 HUD_DiagRespData23 "Diagnostic signal Data response";
CM_ SG_ 1549 HUD_DiagRespData24 "Diagnostic signal Data response";
CM_ SG_ 1549 HUD_DiagRespData25 "Diagnostic signal Data response";
CM_ SG_ 1549 HUD_DiagRespData26 "Diagnostic signal Data response";
CM_ SG_ 1549 HUD_DiagRespData27 "Diagnostic signal Data response";
CM_ SG_ 1549 HUD_DiagRespData28 "Diagnostic signal Data response";
CM_ SG_ 1549 HUD_DiagRespData29 "Diagnostic signal Data response";
CM_ SG_ 1549 HUD_DiagRespData30 "Diagnostic signal Data response";
CM_ SG_ 1549 HUD_DiagRespData31 "Diagnostic signal Data response";
CM_ SG_ 1549 HUD_DiagRespData32 "Diagnostic signal Data response";
CM_ SG_ 1549 HUD_DiagRespData33 "Diagnostic signal Data response";
CM_ SG_ 1549 HUD_DiagRespData34 "Diagnostic signal Data response";
CM_ SG_ 1549 HUD_DiagRespData35 "Diagnostic signal Data response";
CM_ SG_ 1549 HUD_DiagRespData36 "Diagnostic signal Data response";
CM_ SG_ 1549 HUD_DiagRespData37 "Diagnostic signal Data response";
CM_ SG_ 1549 HUD_DiagRespData38 "Diagnostic signal Data response";
CM_ SG_ 1549 HUD_DiagRespData39 "Diagnostic signal Data response";
CM_ SG_ 1549 HUD_DiagRespData40 "Diagnostic signal Data response";
CM_ SG_ 1549 HUD_DiagRespData41 "Diagnostic signal Data response";
CM_ SG_ 1549 HUD_DiagRespData42 "Diagnostic signal Data response";
CM_ SG_ 1549 HUD_DiagRespData43 "Diagnostic signal Data response";
CM_ SG_ 1549 HUD_DiagRespData44 "Diagnostic signal Data response";
CM_ SG_ 1549 HUD_DiagRespData45 "Diagnostic signal Data response";
CM_ SG_ 1549 HUD_DiagRespData46 "Diagnostic signal Data response";
CM_ SG_ 1549 HUD_DiagRespData47 "Diagnostic signal Data response";
CM_ SG_ 1549 HUD_DiagRespData48 "Diagnostic signal Data response";
CM_ SG_ 1549 HUD_DiagRespData49 "Diagnostic signal Data response";
CM_ SG_ 1549 HUD_DiagRespData50 "Diagnostic signal Data response";
CM_ SG_ 1549 HUD_DiagRespData51 "Diagnostic signal Data response";
CM_ SG_ 1549 HUD_DiagRespData52 "Diagnostic signal Data response";
CM_ SG_ 1549 HUD_DiagRespData53 "Diagnostic signal Data response";
CM_ SG_ 1549 HUD_DiagRespData54 "Diagnostic signal Data response";
CM_ SG_ 1549 HUD_DiagRespData55 "Diagnostic signal Data response";
CM_ SG_ 1549 HUD_DiagRespData56 "Diagnostic signal Data response";
CM_ SG_ 1549 HUD_DiagRespData57 "Diagnostic signal Data response";
CM_ SG_ 1549 HUD_DiagRespData58 "Diagnostic signal Data response";
CM_ SG_ 1549 HUD_DiagRespData59 "Diagnostic signal Data response";
CM_ SG_ 1549 HUD_DiagRespData60 "Diagnostic signal Data response";
CM_ SG_ 1549 HUD_DiagRespData61 "Diagnostic signal Data response";
CM_ SG_ 1549 HUD_DiagRespData62 "Diagnostic signal Data response";
CM_ SG_ 1549 HUD_DiagRespData63 "Diagnostic signal Data response";
CM_ SG_ 1677 HUD_DiagReqData0 "Diagnostic signal Data request";
CM_ SG_ 1677 HUD_DiagReqData1 "Diagnostic signal Data request";
CM_ SG_ 1677 HUD_DiagReqData2 "Diagnostic signal Data request";
CM_ SG_ 1677 HUD_DiagReqData3 "Diagnostic signal Data request";
CM_ SG_ 1677 HUD_DiagReqData4 "Diagnostic signal Data request";
CM_ SG_ 1677 HUD_DiagReqData5 "Diagnostic signal Data request";
CM_ SG_ 1677 HUD_DiagReqData6 "Diagnostic signal Data request";
CM_ SG_ 1677 HUD_DiagReqData7 "Diagnostic signal Data request";
CM_ SG_ 1677 HUD_DiagReqData8 "Diagnostic signal Data request";
CM_ SG_ 1677 HUD_DiagReqData9 "Diagnostic signal Data request";
CM_ SG_ 1677 HUD_DiagReqData10 "Diagnostic signal Data request";
CM_ SG_ 1677 HUD_DiagReqData11 "Diagnostic signal Data request";
CM_ SG_ 1677 HUD_DiagReqData12 "Diagnostic signal Data request";
CM_ SG_ 1677 HUD_DiagReqData13 "Diagnostic signal Data request";
CM_ SG_ 1677 HUD_DiagReqData14 "Diagnostic signal Data request";
CM_ SG_ 1677 HUD_DiagReqData15 "Diagnostic signal Data request";
CM_ SG_ 1677 HUD_DiagReqData16 "Diagnostic signal Data request";
CM_ SG_ 1677 HUD_DiagReqData17 "Diagnostic signal Data request";
CM_ SG_ 1677 HUD_DiagReqData18 "Diagnostic signal Data request";
CM_ SG_ 1677 HUD_DiagReqData19 "Diagnostic signal Data request";
CM_ SG_ 1677 HUD_DiagReqData20 "Diagnostic signal Data request";
CM_ SG_ 1677 HUD_DiagReqData21 "Diagnostic signal Data request";
CM_ SG_ 1677 HUD_DiagReqData22 "Diagnostic signal Data request";
CM_ SG_ 1677 HUD_DiagReqData23 "Diagnostic signal Data request";
CM_ SG_ 1677 HUD_DiagReqData24 "Diagnostic signal Data request";
CM_ SG_ 1677 HUD_DiagReqData25 "Diagnostic signal Data request";
CM_ SG_ 1677 HUD_DiagReqData26 "Diagnostic signal Data request";
CM_ SG_ 1677 HUD_DiagReqData27 "Diagnostic signal Data request";
CM_ SG_ 1677 HUD_DiagReqData28 "Diagnostic signal Data request";
CM_ SG_ 1677 HUD_DiagReqData29 "Diagnostic signal Data request";
CM_ SG_ 1677 HUD_DiagReqData30 "Diagnostic signal Data request";
CM_ SG_ 1677 HUD_DiagReqData31 "Diagnostic signal Data request";
CM_ SG_ 1677 HUD_DiagReqData32 "Diagnostic signal Data request";
CM_ SG_ 1677 HUD_DiagReqData33 "Diagnostic signal Data request";
CM_ SG_ 1677 HUD_DiagReqData34 "Diagnostic signal Data request";
CM_ SG_ 1677 HUD_DiagReqData35 "Diagnostic signal Data request";
CM_ SG_ 1677 HUD_DiagReqData36 "Diagnostic signal Data request";
CM_ SG_ 1677 HUD_DiagReqData37 "Diagnostic signal Data request";
CM_ SG_ 1677 HUD_DiagReqData38 "Diagnostic signal Data request";
CM_ SG_ 1677 HUD_DiagReqData39 "Diagnostic signal Data request";
CM_ SG_ 1677 HUD_DiagReqData40 "Diagnostic signal Data request";
CM_ SG_ 1677 HUD_DiagReqData41 "Diagnostic signal Data request";
CM_ SG_ 1677 HUD_DiagReqData42 "Diagnostic signal Data request";
CM_ SG_ 1677 HUD_DiagReqData43 "Diagnostic signal Data request";
CM_ SG_ 1677 HUD_DiagReqData44 "Diagnostic signal Data request";
CM_ SG_ 1677 HUD_DiagReqData45 "Diagnostic signal Data request";
CM_ SG_ 1677 HUD_DiagReqData46 "Diagnostic signal Data request";
CM_ SG_ 1677 HUD_DiagReqData47 "Diagnostic signal Data request";
CM_ SG_ 1677 HUD_DiagReqData48 "Diagnostic signal Data request";
CM_ SG_ 1677 HUD_DiagReqData49 "Diagnostic signal Data request";
CM_ SG_ 1677 HUD_DiagReqData50 "Diagnostic signal Data request";
CM_ SG_ 1677 HUD_DiagReqData51 "Diagnostic signal Data request";
CM_ SG_ 1677 HUD_DiagReqData52 "Diagnostic signal Data request";
CM_ SG_ 1677 HUD_DiagReqData53 "Diagnostic signal Data request";
CM_ SG_ 1677 HUD_DiagReqData54 "Diagnostic signal Data request";
CM_ SG_ 1677 HUD_DiagReqData55 "Diagnostic signal Data request";
CM_ SG_ 1677 HUD_DiagReqData56 "Diagnostic signal Data request";
CM_ SG_ 1677 HUD_DiagReqData57 "Diagnostic signal Data request";
CM_ SG_ 1677 HUD_DiagReqData58 "Diagnostic signal Data request";
CM_ SG_ 1677 HUD_DiagReqData59 "Diagnostic signal Data request";
CM_ SG_ 1677 HUD_DiagReqData60 "Diagnostic signal Data request";
CM_ SG_ 1677 HUD_DiagReqData61 "Diagnostic signal Data request";
CM_ SG_ 1677 HUD_DiagReqData62 "Diagnostic signal Data request";
CM_ SG_ 1677 HUD_DiagReqData63 "Diagnostic signal Data request";
CM_ SG_ 1540 MHU_DiagRespData0 "Diagnostic signal Data response";
CM_ SG_ 1540 MHU_DiagRespData1 "Diagnostic signal Data response";
CM_ SG_ 1540 MHU_DiagRespData2 "Diagnostic signal Data response";
CM_ SG_ 1540 MHU_DiagRespData3 "Diagnostic signal Data response";
CM_ SG_ 1540 MHU_DiagRespData4 "Diagnostic signal Data response";
CM_ SG_ 1540 MHU_DiagRespData5 "Diagnostic signal Data response";
CM_ SG_ 1540 MHU_DiagRespData6 "Diagnostic signal Data response";
CM_ SG_ 1540 MHU_DiagRespData7 "Diagnostic signal Data response";
CM_ SG_ 1540 MHU_DiagRespData8 "Diagnostic signal Data response";
CM_ SG_ 1540 MHU_DiagRespData9 "Diagnostic signal Data response";
CM_ SG_ 1540 MHU_DiagRespData10 "Diagnostic signal Data response";
CM_ SG_ 1540 MHU_DiagRespData11 "Diagnostic signal Data response";
CM_ SG_ 1540 MHU_DiagRespData12 "Diagnostic signal Data response";
CM_ SG_ 1540 MHU_DiagRespData13 "Diagnostic signal Data response";
CM_ SG_ 1540 MHU_DiagRespData14 "Diagnostic signal Data response";
CM_ SG_ 1540 MHU_DiagRespData15 "Diagnostic signal Data response";
CM_ SG_ 1540 MHU_DiagRespData16 "Diagnostic signal Data response";
CM_ SG_ 1540 MHU_DiagRespData17 "Diagnostic signal Data response";
CM_ SG_ 1540 MHU_DiagRespData18 "Diagnostic signal Data response";
CM_ SG_ 1540 MHU_DiagRespData19 "Diagnostic signal Data response";
CM_ SG_ 1540 MHU_DiagRespData20 "Diagnostic signal Data response";
CM_ SG_ 1540 MHU_DiagRespData21 "Diagnostic signal Data response";
CM_ SG_ 1540 MHU_DiagRespData22 "Diagnostic signal Data response";
CM_ SG_ 1540 MHU_DiagRespData23 "Diagnostic signal Data response";
CM_ SG_ 1540 MHU_DiagRespData24 "Diagnostic signal Data response";
CM_ SG_ 1540 MHU_DiagRespData25 "Diagnostic signal Data response";
CM_ SG_ 1540 MHU_DiagRespData26 "Diagnostic signal Data response";
CM_ SG_ 1540 MHU_DiagRespData27 "Diagnostic signal Data response";
CM_ SG_ 1540 MHU_DiagRespData28 "Diagnostic signal Data response";
CM_ SG_ 1540 MHU_DiagRespData29 "Diagnostic signal Data response";
CM_ SG_ 1540 MHU_DiagRespData30 "Diagnostic signal Data response";
CM_ SG_ 1540 MHU_DiagRespData31 "Diagnostic signal Data response";
CM_ SG_ 1540 MHU_DiagRespData32 "Diagnostic signal Data response";
CM_ SG_ 1540 MHU_DiagRespData33 "Diagnostic signal Data response";
CM_ SG_ 1540 MHU_DiagRespData34 "Diagnostic signal Data response";
CM_ SG_ 1540 MHU_DiagRespData35 "Diagnostic signal Data response";
CM_ SG_ 1540 MHU_DiagRespData36 "Diagnostic signal Data response";
CM_ SG_ 1540 MHU_DiagRespData37 "Diagnostic signal Data response";
CM_ SG_ 1540 MHU_DiagRespData38 "Diagnostic signal Data response";
CM_ SG_ 1540 MHU_DiagRespData39 "Diagnostic signal Data response";
CM_ SG_ 1540 MHU_DiagRespData40 "Diagnostic signal Data response";
CM_ SG_ 1540 MHU_DiagRespData41 "Diagnostic signal Data response";
CM_ SG_ 1540 MHU_DiagRespData42 "Diagnostic signal Data response";
CM_ SG_ 1540 MHU_DiagRespData43 "Diagnostic signal Data response";
CM_ SG_ 1540 MHU_DiagRespData44 "Diagnostic signal Data response";
CM_ SG_ 1540 MHU_DiagRespData45 "Diagnostic signal Data response";
CM_ SG_ 1540 MHU_DiagRespData46 "Diagnostic signal Data response";
CM_ SG_ 1540 MHU_DiagRespData47 "Diagnostic signal Data response";
CM_ SG_ 1540 MHU_DiagRespData48 "Diagnostic signal Data response";
CM_ SG_ 1540 MHU_DiagRespData49 "Diagnostic signal Data response";
CM_ SG_ 1540 MHU_DiagRespData50 "Diagnostic signal Data response";
CM_ SG_ 1540 MHU_DiagRespData51 "Diagnostic signal Data response";
CM_ SG_ 1540 MHU_DiagRespData52 "Diagnostic signal Data response";
CM_ SG_ 1540 MHU_DiagRespData53 "Diagnostic signal Data response";
CM_ SG_ 1540 MHU_DiagRespData54 "Diagnostic signal Data response";
CM_ SG_ 1540 MHU_DiagRespData55 "Diagnostic signal Data response";
CM_ SG_ 1540 MHU_DiagRespData56 "Diagnostic signal Data response";
CM_ SG_ 1540 MHU_DiagRespData57 "Diagnostic signal Data response";
CM_ SG_ 1540 MHU_DiagRespData58 "Diagnostic signal Data response";
CM_ SG_ 1540 MHU_DiagRespData59 "Diagnostic signal Data response";
CM_ SG_ 1540 MHU_DiagRespData60 "Diagnostic signal Data response";
CM_ SG_ 1540 MHU_DiagRespData61 "Diagnostic signal Data response";
CM_ SG_ 1540 MHU_DiagRespData62 "Diagnostic signal Data response";
CM_ SG_ 1540 MHU_DiagRespData63 "Diagnostic signal Data response";
CM_ SG_ 1668 MHU_DiagReqData0 "Diagnostic signal Data request";
CM_ SG_ 1668 MHU_DiagReqData1 "Diagnostic signal Data request";
CM_ SG_ 1668 MHU_DiagReqData2 "Diagnostic signal Data request";
CM_ SG_ 1668 MHU_DiagReqData3 "Diagnostic signal Data request";
CM_ SG_ 1668 MHU_DiagReqData4 "Diagnostic signal Data request";
CM_ SG_ 1668 MHU_DiagReqData5 "Diagnostic signal Data request";
CM_ SG_ 1668 MHU_DiagReqData6 "Diagnostic signal Data request";
CM_ SG_ 1668 MHU_DiagReqData7 "Diagnostic signal Data request";
CM_ SG_ 1668 MHU_DiagReqData8 "Diagnostic signal Data request";
CM_ SG_ 1668 MHU_DiagReqData9 "Diagnostic signal Data request";
CM_ SG_ 1668 MHU_DiagReqData10 "Diagnostic signal Data request";
CM_ SG_ 1668 MHU_DiagReqData11 "Diagnostic signal Data request";
CM_ SG_ 1668 MHU_DiagReqData12 "Diagnostic signal Data request";
CM_ SG_ 1668 MHU_DiagReqData13 "Diagnostic signal Data request";
CM_ SG_ 1668 MHU_DiagReqData14 "Diagnostic signal Data request";
CM_ SG_ 1668 MHU_DiagReqData15 "Diagnostic signal Data request";
CM_ SG_ 1668 MHU_DiagReqData16 "Diagnostic signal Data request";
CM_ SG_ 1668 MHU_DiagReqData17 "Diagnostic signal Data request";
CM_ SG_ 1668 MHU_DiagReqData18 "Diagnostic signal Data request";
CM_ SG_ 1668 MHU_DiagReqData19 "Diagnostic signal Data request";
CM_ SG_ 1668 MHU_DiagReqData20 "Diagnostic signal Data request";
CM_ SG_ 1668 MHU_DiagReqData21 "Diagnostic signal Data request";
CM_ SG_ 1668 MHU_DiagReqData22 "Diagnostic signal Data request";
CM_ SG_ 1668 MHU_DiagReqData23 "Diagnostic signal Data request";
CM_ SG_ 1668 MHU_DiagReqData24 "Diagnostic signal Data request";
CM_ SG_ 1668 MHU_DiagReqData25 "Diagnostic signal Data request";
CM_ SG_ 1668 MHU_DiagReqData26 "Diagnostic signal Data request";
CM_ SG_ 1668 MHU_DiagReqData27 "Diagnostic signal Data request";
CM_ SG_ 1668 MHU_DiagReqData28 "Diagnostic signal Data request";
CM_ SG_ 1668 MHU_DiagReqData29 "Diagnostic signal Data request";
CM_ SG_ 1668 MHU_DiagReqData30 "Diagnostic signal Data request";
CM_ SG_ 1668 MHU_DiagReqData31 "Diagnostic signal Data request";
CM_ SG_ 1668 MHU_DiagReqData32 "Diagnostic signal Data request";
CM_ SG_ 1668 MHU_DiagReqData33 "Diagnostic signal Data request";
CM_ SG_ 1668 MHU_DiagReqData34 "Diagnostic signal Data request";
CM_ SG_ 1668 MHU_DiagReqData35 "Diagnostic signal Data request";
CM_ SG_ 1668 MHU_DiagReqData36 "Diagnostic signal Data request";
CM_ SG_ 1668 MHU_DiagReqData37 "Diagnostic signal Data request";
CM_ SG_ 1668 MHU_DiagReqData38 "Diagnostic signal Data request";
CM_ SG_ 1668 MHU_DiagReqData39 "Diagnostic signal Data request";
CM_ SG_ 1668 MHU_DiagReqData40 "Diagnostic signal Data request";
CM_ SG_ 1668 MHU_DiagReqData41 "Diagnostic signal Data request";
CM_ SG_ 1668 MHU_DiagReqData42 "Diagnostic signal Data request";
CM_ SG_ 1668 MHU_DiagReqData43 "Diagnostic signal Data request";
CM_ SG_ 1668 MHU_DiagReqData44 "Diagnostic signal Data request";
CM_ SG_ 1668 MHU_DiagReqData45 "Diagnostic signal Data request";
CM_ SG_ 1668 MHU_DiagReqData46 "Diagnostic signal Data request";
CM_ SG_ 1668 MHU_DiagReqData47 "Diagnostic signal Data request";
CM_ SG_ 1668 MHU_DiagReqData48 "Diagnostic signal Data request";
CM_ SG_ 1668 MHU_DiagReqData49 "Diagnostic signal Data request";
CM_ SG_ 1668 MHU_DiagReqData50 "Diagnostic signal Data request";
CM_ SG_ 1668 MHU_DiagReqData51 "Diagnostic signal Data request";
CM_ SG_ 1668 MHU_DiagReqData52 "Diagnostic signal Data request";
CM_ SG_ 1668 MHU_DiagReqData53 "Diagnostic signal Data request";
CM_ SG_ 1668 MHU_DiagReqData54 "Diagnostic signal Data request";
CM_ SG_ 1668 MHU_DiagReqData55 "Diagnostic signal Data request";
CM_ SG_ 1668 MHU_DiagReqData56 "Diagnostic signal Data request";
CM_ SG_ 1668 MHU_DiagReqData57 "Diagnostic signal Data request";
CM_ SG_ 1668 MHU_DiagReqData58 "Diagnostic signal Data request";
CM_ SG_ 1668 MHU_DiagReqData59 "Diagnostic signal Data request";
CM_ SG_ 1668 MHU_DiagReqData60 "Diagnostic signal Data request";
CM_ SG_ 1668 MHU_DiagReqData61 "Diagnostic signal Data request";
CM_ SG_ 1668 MHU_DiagReqData62 "Diagnostic signal Data request";
CM_ SG_ 1668 MHU_DiagReqData63 "Diagnostic signal Data request";
CM_ SG_ 1701 MRR_DiagReqData0 "Diagnostic signal Data request";
CM_ SG_ 1701 MRR_DiagReqData1 "Diagnostic signal Data request";
CM_ SG_ 1701 MRR_DiagReqData2 "Diagnostic signal Data request";
CM_ SG_ 1701 MRR_DiagReqData3 "Diagnostic signal Data request";
CM_ SG_ 1701 MRR_DiagReqData4 "Diagnostic signal Data request";
CM_ SG_ 1701 MRR_DiagReqData5 "Diagnostic signal Data request";
CM_ SG_ 1701 MRR_DiagReqData6 "Diagnostic signal Data request";
CM_ SG_ 1701 MRR_DiagReqData7 "Diagnostic signal Data request";
CM_ SG_ 1573 MRR_DiagRespData0 "Diagnostic signal Data response";
CM_ SG_ 1573 MRR_DiagRespData1 "Diagnostic signal Data response";
CM_ SG_ 1573 MRR_DiagRespData2 "Diagnostic signal Data response";
CM_ SG_ 1573 MRR_DiagRespData3 "Diagnostic signal Data response";
CM_ SG_ 1573 MRR_DiagRespData4 "Diagnostic signal Data response";
CM_ SG_ 1573 MRR_DiagRespData5 "Diagnostic signal Data response";
CM_ SG_ 1573 MRR_DiagRespData6 "Diagnostic signal Data response";
CM_ SG_ 1573 MRR_DiagRespData7 "Diagnostic signal Data response";
CM_ SG_ 1719 SRR_RL_DiagReqData0 "Diagnostic signal Data request";
CM_ SG_ 1719 SRR_RL_DiagReqData1 "Diagnostic signal Data request";
CM_ SG_ 1719 SRR_RL_DiagReqData2 "Diagnostic signal Data request";
CM_ SG_ 1719 SRR_RL_DiagReqData3 "Diagnostic signal Data request";
CM_ SG_ 1719 SRR_RL_DiagReqData4 "Diagnostic signal Data request";
CM_ SG_ 1719 SRR_RL_DiagReqData5 "Diagnostic signal Data request";
CM_ SG_ 1719 SRR_RL_DiagReqData6 "Diagnostic signal Data request";
CM_ SG_ 1719 SRR_RL_DiagReqData7 "Diagnostic signal Data request";
CM_ SG_ 1591 SRR_RL_DiagRespData0 "Diagnostic signal Data response";
CM_ SG_ 1591 SRR_RL_DiagRespData1 "Diagnostic signal Data response";
CM_ SG_ 1591 SRR_RL_DiagRespData2 "Diagnostic signal Data response";
CM_ SG_ 1591 SRR_RL_DiagRespData3 "Diagnostic signal Data response";
CM_ SG_ 1591 SRR_RL_DiagRespData4 "Diagnostic signal Data response";
CM_ SG_ 1591 SRR_RL_DiagRespData5 "Diagnostic signal Data response";
CM_ SG_ 1591 SRR_RL_DiagRespData6 "Diagnostic signal Data response";
CM_ SG_ 1591 SRR_RL_DiagRespData7 "Diagnostic signal Data response";
CM_ SG_ 1718 SRR_RR_DiagReqData0 "Diagnostic signal Data request";
CM_ SG_ 1718 SRR_RR_DiagReqData1 "Diagnostic signal Data request";
CM_ SG_ 1718 SRR_RR_DiagReqData2 "Diagnostic signal Data request";
CM_ SG_ 1718 SRR_RR_DiagReqData3 "Diagnostic signal Data request";
CM_ SG_ 1718 SRR_RR_DiagReqData4 "Diagnostic signal Data request";
CM_ SG_ 1718 SRR_RR_DiagReqData5 "Diagnostic signal Data request";
CM_ SG_ 1718 SRR_RR_DiagReqData6 "Diagnostic signal Data request";
CM_ SG_ 1718 SRR_RR_DiagReqData7 "Diagnostic signal Data request";
CM_ SG_ 1590 SRR_RR_DiagRespData0 "Diagnostic signal Data response";
CM_ SG_ 1590 SRR_RR_DiagRespData1 "Diagnostic signal Data response";
CM_ SG_ 1590 SRR_RR_DiagRespData2 "Diagnostic signal Data response";
CM_ SG_ 1590 SRR_RR_DiagRespData3 "Diagnostic signal Data response";
CM_ SG_ 1590 SRR_RR_DiagRespData4 "Diagnostic signal Data response";
CM_ SG_ 1590 SRR_RR_DiagRespData5 "Diagnostic signal Data response";
CM_ SG_ 1590 SRR_RR_DiagRespData6 "Diagnostic signal Data response";
CM_ SG_ 1590 SRR_RR_DiagRespData7 "Diagnostic signal Data response";
CM_ SG_ 1717 SRR_FL_DiagReqData0 "Diagnostic signal Data request";
CM_ SG_ 1717 SRR_FL_DiagReqData1 "Diagnostic signal Data request";
CM_ SG_ 1717 SRR_FL_DiagReqData2 "Diagnostic signal Data request";
CM_ SG_ 1717 SRR_FL_DiagReqData3 "Diagnostic signal Data request";
CM_ SG_ 1717 SRR_FL_DiagReqData4 "Diagnostic signal Data request";
CM_ SG_ 1717 SRR_FL_DiagReqData5 "Diagnostic signal Data request";
CM_ SG_ 1717 SRR_FL_DiagReqData6 "Diagnostic signal Data request";
CM_ SG_ 1717 SRR_FL_DiagReqData7 "Diagnostic signal Data request";
CM_ SG_ 1589 SRR_FL_DiagRespData0 "Diagnostic signal Data response";
CM_ SG_ 1589 SRR_FL_DiagRespData1 "Diagnostic signal Data response";
CM_ SG_ 1589 SRR_FL_DiagRespData2 "Diagnostic signal Data response";
CM_ SG_ 1589 SRR_FL_DiagRespData3 "Diagnostic signal Data response";
CM_ SG_ 1589 SRR_FL_DiagRespData4 "Diagnostic signal Data response";
CM_ SG_ 1589 SRR_FL_DiagRespData5 "Diagnostic signal Data response";
CM_ SG_ 1589 SRR_FL_DiagRespData6 "Diagnostic signal Data response";
CM_ SG_ 1589 SRR_FL_DiagRespData7 "Diagnostic signal Data response";
CM_ SG_ 1716 SRR_FR_DiagReqData0 "Diagnostic signal Data request";
CM_ SG_ 1716 SRR_FR_DiagReqData1 "Diagnostic signal Data request";
CM_ SG_ 1716 SRR_FR_DiagReqData2 "Diagnostic signal Data request";
CM_ SG_ 1716 SRR_FR_DiagReqData3 "Diagnostic signal Data request";
CM_ SG_ 1716 SRR_FR_DiagReqData4 "Diagnostic signal Data request";
CM_ SG_ 1716 SRR_FR_DiagReqData5 "Diagnostic signal Data request";
CM_ SG_ 1716 SRR_FR_DiagReqData6 "Diagnostic signal Data request";
CM_ SG_ 1716 SRR_FR_DiagReqData7 "Diagnostic signal Data request";
CM_ SG_ 1588 SRR_FR_DiagRespData0 "Diagnostic signal Data response";
CM_ SG_ 1588 SRR_FR_DiagRespData1 "Diagnostic signal Data response";
CM_ SG_ 1588 SRR_FR_DiagRespData2 "Diagnostic signal Data response";
CM_ SG_ 1588 SRR_FR_DiagRespData3 "Diagnostic signal Data response";
CM_ SG_ 1588 SRR_FR_DiagRespData4 "Diagnostic signal Data response";
CM_ SG_ 1588 SRR_FR_DiagRespData5 "Diagnostic signal Data response";
CM_ SG_ 1588 SRR_FR_DiagRespData6 "Diagnostic signal Data response";
CM_ SG_ 1588 SRR_FR_DiagRespData7 "Diagnostic signal Data response";
CM_ SG_ 1791 OBD_Func_DiagReqData0 "Diagnostic message all ECUs";
CM_ SG_ 1791 OBD_Func_DiagReqData1 "Diagnostic message all ECUs";
CM_ SG_ 1791 OBD_Func_DiagReqData2 "Diagnostic message all ECUs";
CM_ SG_ 1791 OBD_Func_DiagReqData3 "Diagnostic message all ECUs";
CM_ SG_ 1791 OBD_Func_DiagReqData4 "Diagnostic message all ECUs";
CM_ SG_ 1791 OBD_Func_DiagReqData5 "Diagnostic message all ECUs";
CM_ SG_ 1791 OBD_Func_DiagReqData6 "Diagnostic message all ECUs";
CM_ SG_ 1791 OBD_Func_DiagReqData7 "Diagnostic message all ECUs";
BA_DEF_ BO_  "DiagRequest" ENUM  "No","Yes";
BA_DEF_ BO_  "DiagResponse" ENUM  "No","Yes";
BA_DEF_ BO_  "DiagState" ENUM  "No","Yes";
BA_DEF_ BO_  "GenMsgCycleTime" INT 0 65535;
BA_DEF_ BO_  "GenMsgCycleTimeFast" INT 0 65535;
BA_DEF_ BO_  "GenMsgDelayTime" INT 0 65535;
BA_DEF_ BO_  "GenMsgILSupport" ENUM  "No","Yes";
BA_DEF_ BO_  "GenMsgNrOfRepetition" INT 0 65535;
BA_DEF_ BO_  "GenMsgSendType" ENUM  "Cyclic","NoMsgSendType","NotUsed","NotUsed","NotUsed","NotUsed","NotUsed","IfActive","NoMsgSendType","NotUsed";
BA_DEF_ BO_  "NmAsrMessage" ENUM  "No","Yes";
BA_DEF_ BO_  "NmMessage" ENUM  "No","Yes";
BA_DEF_ SG_  "GenSigSendType" ENUM  "Cyclic","NoSigSendType","OnWriteWithRepetition","OnChange","OnChangeWithRepetition","IfActive","IfActiveWithRepetition","OnWrite","NotUsed","NotUsed","NotUsed","NotUsed","NotUsed";
BA_DEF_ SG_  "GenSigStartValue" INT 0 2147483647;
BA_DEF_ SG_  "GenSigTimeoutTime_ALL" INT 0 65535;
BA_DEF_ SG_  "InvalidValue" STRING ;
BA_DEF_ SG_  "GenSigInactiveValue" INT 0 2147483647;
BA_DEF_ BO_  "VFrameFormat" ENUM  "StandardCAN","ExtendedCAN","reserved","J1939PG","reserved","reserved","reserved","reserved","reserved","reserved","reserved","reserved","reserved","reserved","StandardCAN_FD","ExtendedCAN_FD";
BA_DEF_ BO_  "CANFD_BRS" ENUM  "0","1";
BA_DEF_ SG_  "SystemSignalLongSymbol" STRING ;
BA_DEF_ BO_  "SystemMessageLongSymbol" STRING ;
BA_DEF_DEF_  "DiagRequest" "No";
BA_DEF_DEF_  "DiagResponse" "No";
BA_DEF_DEF_  "DiagState" "No";
BA_DEF_DEF_  "GenMsgCycleTime" 0;
BA_DEF_DEF_  "GenMsgCycleTimeFast" 0;
BA_DEF_DEF_  "GenMsgDelayTime" 0;
BA_DEF_DEF_  "GenMsgILSupport" "Yes";
BA_DEF_DEF_  "GenMsgNrOfRepetition" 0;
BA_DEF_DEF_  "GenMsgSendType" "Cyclic";
BA_DEF_DEF_  "NmAsrMessage" "No";
BA_DEF_DEF_  "NmMessage" "No";
BA_DEF_DEF_  "GenSigSendType" "Cyclic";
BA_DEF_DEF_  "GenSigStartValue" 0;
BA_DEF_DEF_  "GenSigTimeoutTime_ALL" 0;
BA_DEF_DEF_  "InvalidValue" "";
BA_DEF_DEF_  "GenSigInactiveValue" 0;
BA_DEF_DEF_  "VFrameFormat" "StandardCAN_FD";
BA_DEF_DEF_  "CANFD_BRS" "1";
BA_DEF_DEF_  "SystemSignalLongSymbol" "";
BA_DEF_DEF_  "SystemMessageLongSymbol" "";
BA_ "NmMessage" BO_ 1282 1;
BA_ "NmAsrMessage" BO_ 1282 1;
BA_ "VFrameFormat" BO_ 1282 0;
BA_ "GenMsgCycleTime" BO_ 1282 640;
BA_ "GenMsgILSupport" BO_ 1282 0;
BA_ "NmMessage" BO_ 1284 1;
BA_ "NmAsrMessage" BO_ 1284 1;
BA_ "VFrameFormat" BO_ 1284 0;
BA_ "GenMsgCycleTime" BO_ 1284 640;
BA_ "GenMsgILSupport" BO_ 1284 0;
BA_ "NmMessage" BO_ 1285 1;
BA_ "NmAsrMessage" BO_ 1285 1;
BA_ "VFrameFormat" BO_ 1285 0;
BA_ "GenMsgCycleTime" BO_ 1285 640;
BA_ "GenMsgILSupport" BO_ 1285 0;
BA_ "NmMessage" BO_ 1290 1;
BA_ "NmAsrMessage" BO_ 1290 1;
BA_ "VFrameFormat" BO_ 1290 0;
BA_ "GenMsgCycleTime" BO_ 1290 640;
BA_ "GenMsgILSupport" BO_ 1290 0;
BA_ "GenMsgILSupport" BO_ 1674 0;
BA_ "DiagState" BO_ 1674 1;
BA_ "DiagRequest" BO_ 1674 1;
BA_ "GenMsgSendType" BO_ 1674 1;
BA_ "GenMsgILSupport" BO_ 1546 0;
BA_ "DiagState" BO_ 1546 1;
BA_ "DiagResponse" BO_ 1546 1;
BA_ "GenMsgSendType" BO_ 1546 1;
BA_ "GenMsgILSupport" BO_ 1541 0;
BA_ "DiagState" BO_ 1541 1;
BA_ "DiagResponse" BO_ 1541 1;
BA_ "GenMsgSendType" BO_ 1541 1;
BA_ "GenMsgILSupport" BO_ 1669 0;
BA_ "DiagState" BO_ 1669 1;
BA_ "DiagRequest" BO_ 1669 1;
BA_ "GenMsgSendType" BO_ 1669 1;
BA_ "GenMsgILSupport" BO_ 1549 0;
BA_ "DiagState" BO_ 1549 1;
BA_ "DiagResponse" BO_ 1549 1;
BA_ "GenMsgSendType" BO_ 1549 1;
BA_ "GenMsgILSupport" BO_ 1677 0;
BA_ "DiagState" BO_ 1677 1;
BA_ "DiagRequest" BO_ 1677 1;
BA_ "GenMsgSendType" BO_ 1677 1;
BA_ "GenMsgILSupport" BO_ 1540 0;
BA_ "DiagState" BO_ 1540 1;
BA_ "DiagResponse" BO_ 1540 1;
BA_ "GenMsgSendType" BO_ 1540 1;
BA_ "GenMsgILSupport" BO_ 1668 0;
BA_ "DiagState" BO_ 1668 1;
BA_ "DiagRequest" BO_ 1668 1;
BA_ "GenMsgSendType" BO_ 1668 1;
BA_ "GenMsgILSupport" BO_ 1701 0;
BA_ "DiagState" BO_ 1701 1;
BA_ "DiagRequest" BO_ 1701 1;
BA_ "GenMsgSendType" BO_ 1701 1;
BA_ "GenMsgILSupport" BO_ 1573 0;
BA_ "DiagState" BO_ 1573 1;
BA_ "DiagResponse" BO_ 1573 1;
BA_ "GenMsgSendType" BO_ 1573 1;
BA_ "GenMsgILSupport" BO_ 1719 0;
BA_ "DiagState" BO_ 1719 1;
BA_ "DiagRequest" BO_ 1719 1;
BA_ "GenMsgSendType" BO_ 1719 1;
BA_ "GenMsgILSupport" BO_ 1591 0;
BA_ "DiagState" BO_ 1591 1;
BA_ "DiagResponse" BO_ 1591 1;
BA_ "GenMsgSendType" BO_ 1591 1;
BA_ "GenMsgILSupport" BO_ 1718 0;
BA_ "DiagState" BO_ 1718 1;
BA_ "DiagRequest" BO_ 1718 1;
BA_ "GenMsgSendType" BO_ 1718 1;
BA_ "GenMsgILSupport" BO_ 1590 0;
BA_ "DiagState" BO_ 1590 1;
BA_ "DiagResponse" BO_ 1590 1;
BA_ "GenMsgSendType" BO_ 1590 1;
BA_ "GenMsgILSupport" BO_ 1717 0;
BA_ "DiagState" BO_ 1717 1;
BA_ "DiagRequest" BO_ 1717 1;
BA_ "GenMsgSendType" BO_ 1717 1;
BA_ "GenMsgILSupport" BO_ 1589 0;
BA_ "DiagState" BO_ 1589 1;
BA_ "DiagResponse" BO_ 1589 1;
BA_ "GenMsgSendType" BO_ 1589 1;
BA_ "GenMsgILSupport" BO_ 1716 0;
BA_ "DiagState" BO_ 1716 1;
BA_ "DiagRequest" BO_ 1716 1;
BA_ "GenMsgSendType" BO_ 1716 1;
BA_ "GenMsgILSupport" BO_ 1588 0;
BA_ "DiagState" BO_ 1588 1;
BA_ "DiagResponse" BO_ 1588 1;
BA_ "GenMsgSendType" BO_ 1588 1;
BA_ "GenMsgILSupport" BO_ 1791 0;
BA_ "DiagState" BO_ 1791 1;
BA_ "GenMsgSendType" BO_ 1791 1;
BA_ "DiagRequest" BO_ 1791 1;
BA_ "InvalidValue" SG_ 1282 CVC_srcNodeID "FFh";
BA_ "GenSigStartValue" SG_ 1282 CVC_usrData0 255;
BA_ "GenSigStartValue" SG_ 1282 CVC_usrData1 255;
BA_ "GenSigStartValue" SG_ 1282 CVC_usrData2 255;
BA_ "GenSigStartValue" SG_ 1282 CVC_usrData3 255;
BA_ "GenSigStartValue" SG_ 1282 CVC_usrData4 255;
BA_ "GenSigStartValue" SG_ 1282 CVC_usrData5 255;
BA_ "InvalidValue" SG_ 1284 MHU_srcNodeID "FFh";
BA_ "GenSigStartValue" SG_ 1284 MHU_usrData0 255;
BA_ "GenSigStartValue" SG_ 1284 MHU_usrData1 255;
BA_ "GenSigStartValue" SG_ 1284 MHU_usrData2 255;
BA_ "GenSigStartValue" SG_ 1284 MHU_usrData3 255;
BA_ "GenSigStartValue" SG_ 1284 MHU_usrData4 255;
BA_ "GenSigStartValue" SG_ 1284 MHU_usrData5 255;
BA_ "InvalidValue" SG_ 1285 AMP_srcNodeID "FFh";
BA_ "GenSigStartValue" SG_ 1285 AMP_userData0 255;
BA_ "GenSigStartValue" SG_ 1285 AMP_userData1 255;
BA_ "GenSigStartValue" SG_ 1285 AMP_userData2 255;
BA_ "GenSigStartValue" SG_ 1285 AMP_userData3 255;
BA_ "GenSigStartValue" SG_ 1285 AMP_userData4 255;
BA_ "GenSigStartValue" SG_ 1285 AMP_userData5 255;
BA_ "InvalidValue" SG_ 1290 TBOX_srcNodeID "FFh";
BA_ "GenSigStartValue" SG_ 1290 TBOX_usrData0 255;
BA_ "GenSigStartValue" SG_ 1290 TBOX_usrData1 255;
BA_ "GenSigStartValue" SG_ 1290 TBOX_usrData2 255;
BA_ "GenSigStartValue" SG_ 1290 TBOX_usrData3 255;
BA_ "GenSigStartValue" SG_ 1290 TBOX_usrData4 255;
BA_ "GenSigStartValue" SG_ 1290 TBOX_usrData5 255;
BA_ "GenSigSendType" SG_ 1674 TBOX_DiagReqData0 1;
BA_ "GenSigSendType" SG_ 1674 TBOX_DiagReqData1 1;
BA_ "GenSigSendType" SG_ 1674 TBOX_DiagReqData2 1;
BA_ "GenSigSendType" SG_ 1674 TBOX_DiagReqData3 1;
BA_ "GenSigSendType" SG_ 1674 TBOX_DiagReqData4 1;
BA_ "GenSigSendType" SG_ 1674 TBOX_DiagReqData5 1;
BA_ "GenSigSendType" SG_ 1674 TBOX_DiagReqData6 1;
BA_ "GenSigSendType" SG_ 1674 TBOX_DiagReqData7 1;
BA_ "GenSigSendType" SG_ 1674 TBOX_DiagReqData8 1;
BA_ "GenSigSendType" SG_ 1674 TBOX_DiagReqData9 1;
BA_ "GenSigSendType" SG_ 1674 TBOX_DiagReqData10 1;
BA_ "GenSigSendType" SG_ 1674 TBOX_DiagReqData11 1;
BA_ "GenSigSendType" SG_ 1674 TBOX_DiagReqData12 1;
BA_ "GenSigSendType" SG_ 1674 TBOX_DiagReqData13 1;
BA_ "GenSigSendType" SG_ 1674 TBOX_DiagReqData14 1;
BA_ "GenSigSendType" SG_ 1674 TBOX_DiagReqData15 1;
BA_ "GenSigSendType" SG_ 1674 TBOX_DiagReqData16 1;
BA_ "GenSigSendType" SG_ 1674 TBOX_DiagReqData17 1;
BA_ "GenSigSendType" SG_ 1674 TBOX_DiagReqData18 1;
BA_ "GenSigSendType" SG_ 1674 TBOX_DiagReqData19 1;
BA_ "GenSigSendType" SG_ 1674 TBOX_DiagReqData20 1;
BA_ "GenSigSendType" SG_ 1674 TBOX_DiagReqData21 1;
BA_ "GenSigSendType" SG_ 1674 TBOX_DiagReqData22 1;
BA_ "GenSigSendType" SG_ 1674 TBOX_DiagReqData23 1;
BA_ "GenSigSendType" SG_ 1674 TBOX_DiagReqData24 1;
BA_ "GenSigSendType" SG_ 1674 TBOX_DiagReqData25 1;
BA_ "GenSigSendType" SG_ 1674 TBOX_DiagReqData26 1;
BA_ "GenSigSendType" SG_ 1674 TBOX_DiagReqData27 1;
BA_ "GenSigSendType" SG_ 1674 TBOX_DiagReqData28 1;
BA_ "GenSigSendType" SG_ 1674 TBOX_DiagReqData29 1;
BA_ "GenSigSendType" SG_ 1674 TBOX_DiagReqData30 1;
BA_ "GenSigSendType" SG_ 1674 TBOX_DiagReqData31 1;
BA_ "GenSigSendType" SG_ 1674 TBOX_DiagReqData32 1;
BA_ "GenSigSendType" SG_ 1674 TBOX_DiagReqData33 1;
BA_ "GenSigSendType" SG_ 1674 TBOX_DiagReqData34 1;
BA_ "GenSigSendType" SG_ 1674 TBOX_DiagReqData35 1;
BA_ "GenSigSendType" SG_ 1674 TBOX_DiagReqData36 1;
BA_ "GenSigSendType" SG_ 1674 TBOX_DiagReqData37 1;
BA_ "GenSigSendType" SG_ 1674 TBOX_DiagReqData38 1;
BA_ "GenSigSendType" SG_ 1674 TBOX_DiagReqData39 1;
BA_ "GenSigSendType" SG_ 1674 TBOX_DiagReqData40 1;
BA_ "GenSigSendType" SG_ 1674 TBOX_DiagReqData41 1;
BA_ "GenSigSendType" SG_ 1674 TBOX_DiagReqData42 1;
BA_ "GenSigSendType" SG_ 1674 TBOX_DiagReqData43 1;
BA_ "GenSigSendType" SG_ 1674 TBOX_DiagReqData44 1;
BA_ "GenSigSendType" SG_ 1674 TBOX_DiagReqData45 1;
BA_ "GenSigSendType" SG_ 1674 TBOX_DiagReqData46 1;
BA_ "GenSigSendType" SG_ 1674 TBOX_DiagReqData47 1;
BA_ "GenSigSendType" SG_ 1674 TBOX_DiagReqData48 1;
BA_ "GenSigSendType" SG_ 1674 TBOX_DiagReqData49 1;
BA_ "GenSigSendType" SG_ 1674 TBOX_DiagReqData50 1;
BA_ "GenSigSendType" SG_ 1674 TBOX_DiagReqData51 1;
BA_ "GenSigSendType" SG_ 1674 TBOX_DiagReqData52 1;
BA_ "GenSigSendType" SG_ 1674 TBOX_DiagReqData53 1;
BA_ "GenSigSendType" SG_ 1674 TBOX_DiagReqData54 1;
BA_ "GenSigSendType" SG_ 1674 TBOX_DiagReqData55 1;
BA_ "GenSigSendType" SG_ 1674 TBOX_DiagReqData56 1;
BA_ "GenSigSendType" SG_ 1674 TBOX_DiagReqData57 1;
BA_ "GenSigSendType" SG_ 1674 TBOX_DiagReqData58 1;
BA_ "GenSigSendType" SG_ 1674 TBOX_DiagReqData59 1;
BA_ "GenSigSendType" SG_ 1674 TBOX_DiagReqData60 1;
BA_ "GenSigSendType" SG_ 1674 TBOX_DiagReqData61 1;
BA_ "GenSigSendType" SG_ 1674 TBOX_DiagReqData62 1;
BA_ "GenSigSendType" SG_ 1674 TBOX_DiagReqData63 1;
BA_ "GenSigSendType" SG_ 1546 TBOX_DiagRespData0 1;
BA_ "GenSigSendType" SG_ 1546 TBOX_DiagRespData1 1;
BA_ "GenSigSendType" SG_ 1546 TBOX_DiagRespData2 1;
BA_ "GenSigSendType" SG_ 1546 TBOX_DiagRespData3 1;
BA_ "GenSigSendType" SG_ 1546 TBOX_DiagRespData4 1;
BA_ "GenSigSendType" SG_ 1546 TBOX_DiagRespData5 1;
BA_ "GenSigSendType" SG_ 1546 TBOX_DiagRespData6 1;
BA_ "GenSigSendType" SG_ 1546 TBOX_DiagRespData7 1;
BA_ "GenSigSendType" SG_ 1546 TBOX_DiagRespData8 1;
BA_ "GenSigSendType" SG_ 1546 TBOX_DiagRespData9 1;
BA_ "GenSigSendType" SG_ 1546 TBOX_DiagRespData10 1;
BA_ "GenSigSendType" SG_ 1546 TBOX_DiagRespData11 1;
BA_ "GenSigSendType" SG_ 1546 TBOX_DiagRespData12 1;
BA_ "GenSigSendType" SG_ 1546 TBOX_DiagRespData13 1;
BA_ "GenSigSendType" SG_ 1546 TBOX_DiagRespData14 1;
BA_ "GenSigSendType" SG_ 1546 TBOX_DiagRespData15 1;
BA_ "GenSigSendType" SG_ 1546 TBOX_DiagRespData16 1;
BA_ "GenSigSendType" SG_ 1546 TBOX_DiagRespData17 1;
BA_ "GenSigSendType" SG_ 1546 TBOX_DiagRespData18 1;
BA_ "GenSigSendType" SG_ 1546 TBOX_DiagRespData19 1;
BA_ "GenSigSendType" SG_ 1546 TBOX_DiagRespData20 1;
BA_ "GenSigSendType" SG_ 1546 TBOX_DiagRespData21 1;
BA_ "GenSigSendType" SG_ 1546 TBOX_DiagRespData22 1;
BA_ "GenSigSendType" SG_ 1546 TBOX_DiagRespData23 1;
BA_ "GenSigSendType" SG_ 1546 TBOX_DiagRespData24 1;
BA_ "GenSigSendType" SG_ 1546 TBOX_DiagRespData25 1;
BA_ "GenSigSendType" SG_ 1546 TBOX_DiagRespData26 1;
BA_ "GenSigSendType" SG_ 1546 TBOX_DiagRespData27 1;
BA_ "GenSigSendType" SG_ 1546 TBOX_DiagRespData28 1;
BA_ "GenSigSendType" SG_ 1546 TBOX_DiagRespData29 1;
BA_ "GenSigSendType" SG_ 1546 TBOX_DiagRespData30 1;
BA_ "GenSigSendType" SG_ 1546 TBOX_DiagRespData31 1;
BA_ "GenSigSendType" SG_ 1546 TBOX_DiagRespData32 1;
BA_ "GenSigSendType" SG_ 1546 TBOX_DiagRespData33 1;
BA_ "GenSigSendType" SG_ 1546 TBOX_DiagRespData34 1;
BA_ "GenSigSendType" SG_ 1546 TBOX_DiagRespData35 1;
BA_ "GenSigSendType" SG_ 1546 TBOX_DiagRespData36 1;
BA_ "GenSigSendType" SG_ 1546 TBOX_DiagRespData37 1;
BA_ "GenSigSendType" SG_ 1546 TBOX_DiagRespData38 1;
BA_ "GenSigSendType" SG_ 1546 TBOX_DiagRespData39 1;
BA_ "GenSigSendType" SG_ 1546 TBOX_DiagRespData40 1;
BA_ "GenSigSendType" SG_ 1546 TBOX_DiagRespData41 1;
BA_ "GenSigSendType" SG_ 1546 TBOX_DiagRespData42 1;
BA_ "GenSigSendType" SG_ 1546 TBOX_DiagRespData43 1;
BA_ "GenSigSendType" SG_ 1546 TBOX_DiagRespData44 1;
BA_ "GenSigSendType" SG_ 1546 TBOX_DiagRespData45 1;
BA_ "GenSigSendType" SG_ 1546 TBOX_DiagRespData46 1;
BA_ "GenSigSendType" SG_ 1546 TBOX_DiagRespData47 1;
BA_ "GenSigSendType" SG_ 1546 TBOX_DiagRespData48 1;
BA_ "GenSigSendType" SG_ 1546 TBOX_DiagRespData49 1;
BA_ "GenSigSendType" SG_ 1546 TBOX_DiagRespData50 1;
BA_ "GenSigSendType" SG_ 1546 TBOX_DiagRespData51 1;
BA_ "GenSigSendType" SG_ 1546 TBOX_DiagRespData52 1;
BA_ "GenSigSendType" SG_ 1546 TBOX_DiagRespData53 1;
BA_ "GenSigSendType" SG_ 1546 TBOX_DiagRespData54 1;
BA_ "GenSigSendType" SG_ 1546 TBOX_DiagRespData55 1;
BA_ "GenSigSendType" SG_ 1546 TBOX_DiagRespData56 1;
BA_ "GenSigSendType" SG_ 1546 TBOX_DiagRespData57 1;
BA_ "GenSigSendType" SG_ 1546 TBOX_DiagRespData58 1;
BA_ "GenSigSendType" SG_ 1546 TBOX_DiagRespData59 1;
BA_ "GenSigSendType" SG_ 1546 TBOX_DiagRespData60 1;
BA_ "GenSigSendType" SG_ 1546 TBOX_DiagRespData61 1;
BA_ "GenSigSendType" SG_ 1546 TBOX_DiagRespData62 1;
BA_ "GenSigSendType" SG_ 1546 TBOX_DiagRespData63 1;
BA_ "GenSigSendType" SG_ 1541 AMP_DiagRespData0 1;
BA_ "GenSigSendType" SG_ 1541 AMP_DiagRespData1 1;
BA_ "GenSigSendType" SG_ 1541 AMP_DiagRespData2 1;
BA_ "GenSigSendType" SG_ 1541 AMP_DiagRespData3 1;
BA_ "GenSigSendType" SG_ 1541 AMP_DiagRespData4 1;
BA_ "GenSigSendType" SG_ 1541 AMP_DiagRespData5 1;
BA_ "GenSigSendType" SG_ 1541 AMP_DiagRespData6 1;
BA_ "GenSigSendType" SG_ 1541 AMP_DiagRespData7 1;
BA_ "GenSigSendType" SG_ 1541 AMP_DiagRespData8 1;
BA_ "GenSigSendType" SG_ 1541 AMP_DiagRespData9 1;
BA_ "GenSigSendType" SG_ 1541 AMP_DiagRespData10 1;
BA_ "GenSigSendType" SG_ 1541 AMP_DiagRespData11 1;
BA_ "GenSigSendType" SG_ 1541 AMP_DiagRespData12 1;
BA_ "GenSigSendType" SG_ 1541 AMP_DiagRespData13 1;
BA_ "GenSigSendType" SG_ 1541 AMP_DiagRespData14 1;
BA_ "GenSigSendType" SG_ 1541 AMP_DiagRespData15 1;
BA_ "GenSigSendType" SG_ 1541 AMP_DiagRespData16 1;
BA_ "GenSigSendType" SG_ 1541 AMP_DiagRespData17 1;
BA_ "GenSigSendType" SG_ 1541 AMP_DiagRespData18 1;
BA_ "GenSigSendType" SG_ 1541 AMP_DiagRespData19 1;
BA_ "GenSigSendType" SG_ 1541 AMP_DiagRespData20 1;
BA_ "GenSigSendType" SG_ 1541 AMP_DiagRespData21 1;
BA_ "GenSigSendType" SG_ 1541 AMP_DiagRespData22 1;
BA_ "GenSigSendType" SG_ 1541 AMP_DiagRespData23 1;
BA_ "GenSigSendType" SG_ 1541 AMP_DiagRespData24 1;
BA_ "GenSigSendType" SG_ 1541 AMP_DiagRespData25 1;
BA_ "GenSigSendType" SG_ 1541 AMP_DiagRespData26 1;
BA_ "GenSigSendType" SG_ 1541 AMP_DiagRespData27 1;
BA_ "GenSigSendType" SG_ 1541 AMP_DiagRespData28 1;
BA_ "GenSigSendType" SG_ 1541 AMP_DiagRespData29 1;
BA_ "GenSigSendType" SG_ 1541 AMP_DiagRespData30 1;
BA_ "GenSigSendType" SG_ 1541 AMP_DiagRespData31 1;
BA_ "GenSigSendType" SG_ 1541 AMP_DiagRespData32 1;
BA_ "GenSigSendType" SG_ 1541 AMP_DiagRespData33 1;
BA_ "GenSigSendType" SG_ 1541 AMP_DiagRespData34 1;
BA_ "GenSigSendType" SG_ 1541 AMP_DiagRespData35 1;
BA_ "GenSigSendType" SG_ 1541 AMP_DiagRespData36 1;
BA_ "GenSigSendType" SG_ 1541 AMP_DiagRespData37 1;
BA_ "GenSigSendType" SG_ 1541 AMP_DiagRespData38 1;
BA_ "GenSigSendType" SG_ 1541 AMP_DiagRespData39 1;
BA_ "GenSigSendType" SG_ 1541 AMP_DiagRespData40 1;
BA_ "GenSigSendType" SG_ 1541 AMP_DiagRespData41 1;
BA_ "GenSigSendType" SG_ 1541 AMP_DiagRespData42 1;
BA_ "GenSigSendType" SG_ 1541 AMP_DiagRespData43 1;
BA_ "GenSigSendType" SG_ 1541 AMP_DiagRespData44 1;
BA_ "GenSigSendType" SG_ 1541 AMP_DiagRespData45 1;
BA_ "GenSigSendType" SG_ 1541 AMP_DiagRespData46 1;
BA_ "GenSigSendType" SG_ 1541 AMP_DiagRespData47 1;
BA_ "GenSigSendType" SG_ 1541 AMP_DiagRespData48 1;
BA_ "GenSigSendType" SG_ 1541 AMP_DiagRespData49 1;
BA_ "GenSigSendType" SG_ 1541 AMP_DiagRespData50 1;
BA_ "GenSigSendType" SG_ 1541 AMP_DiagRespData51 1;
BA_ "GenSigSendType" SG_ 1541 AMP_DiagRespData52 1;
BA_ "GenSigSendType" SG_ 1541 AMP_DiagRespData53 1;
BA_ "GenSigSendType" SG_ 1541 AMP_DiagRespData54 1;
BA_ "GenSigSendType" SG_ 1541 AMP_DiagRespData55 1;
BA_ "GenSigSendType" SG_ 1541 AMP_DiagRespData56 1;
BA_ "GenSigSendType" SG_ 1541 AMP_DiagRespData57 1;
BA_ "GenSigSendType" SG_ 1541 AMP_DiagRespData58 1;
BA_ "GenSigSendType" SG_ 1541 AMP_DiagRespData59 1;
BA_ "GenSigSendType" SG_ 1541 AMP_DiagRespData60 1;
BA_ "GenSigSendType" SG_ 1541 AMP_DiagRespData61 1;
BA_ "GenSigSendType" SG_ 1541 AMP_DiagRespData62 1;
BA_ "GenSigSendType" SG_ 1541 AMP_DiagRespData63 1;
BA_ "GenSigSendType" SG_ 1669 AMP_DiagReqData0 1;
BA_ "GenSigSendType" SG_ 1669 AMP_DiagReqData1 1;
BA_ "GenSigSendType" SG_ 1669 AMP_DiagReqData2 1;
BA_ "GenSigSendType" SG_ 1669 AMP_DiagReqData3 1;
BA_ "GenSigSendType" SG_ 1669 AMP_DiagReqData4 1;
BA_ "GenSigSendType" SG_ 1669 AMP_DiagReqData5 1;
BA_ "GenSigSendType" SG_ 1669 AMP_DiagReqData6 1;
BA_ "GenSigSendType" SG_ 1669 AMP_DiagReqData7 1;
BA_ "GenSigSendType" SG_ 1669 AMP_DiagReqData8 1;
BA_ "GenSigSendType" SG_ 1669 AMP_DiagReqData9 1;
BA_ "GenSigSendType" SG_ 1669 AMP_DiagReqData10 1;
BA_ "GenSigSendType" SG_ 1669 AMP_DiagReqData11 1;
BA_ "GenSigSendType" SG_ 1669 AMP_DiagReqData12 1;
BA_ "GenSigSendType" SG_ 1669 AMP_DiagReqData13 1;
BA_ "GenSigSendType" SG_ 1669 AMP_DiagReqData14 1;
BA_ "GenSigSendType" SG_ 1669 AMP_DiagReqData15 1;
BA_ "GenSigSendType" SG_ 1669 AMP_DiagReqData16 1;
BA_ "GenSigSendType" SG_ 1669 AMP_DiagReqData17 1;
BA_ "GenSigSendType" SG_ 1669 AMP_DiagReqData18 1;
BA_ "GenSigSendType" SG_ 1669 AMP_DiagReqData19 1;
BA_ "GenSigSendType" SG_ 1669 AMP_DiagReqData20 1;
BA_ "GenSigSendType" SG_ 1669 AMP_DiagReqData21 1;
BA_ "GenSigSendType" SG_ 1669 AMP_DiagReqData22 1;
BA_ "GenSigSendType" SG_ 1669 AMP_DiagReqData23 1;
BA_ "GenSigSendType" SG_ 1669 AMP_DiagReqData24 1;
BA_ "GenSigSendType" SG_ 1669 AMP_DiagReqData25 1;
BA_ "GenSigSendType" SG_ 1669 AMP_DiagReqData26 1;
BA_ "GenSigSendType" SG_ 1669 AMP_DiagReqData27 1;
BA_ "GenSigSendType" SG_ 1669 AMP_DiagReqData28 1;
BA_ "GenSigSendType" SG_ 1669 AMP_DiagReqData29 1;
BA_ "GenSigSendType" SG_ 1669 AMP_DiagReqData30 1;
BA_ "GenSigSendType" SG_ 1669 AMP_DiagReqData31 1;
BA_ "GenSigSendType" SG_ 1669 AMP_DiagReqData32 1;
BA_ "GenSigSendType" SG_ 1669 AMP_DiagReqData33 1;
BA_ "GenSigSendType" SG_ 1669 AMP_DiagReqData34 1;
BA_ "GenSigSendType" SG_ 1669 AMP_DiagReqData35 1;
BA_ "GenSigSendType" SG_ 1669 AMP_DiagReqData36 1;
BA_ "GenSigSendType" SG_ 1669 AMP_DiagReqData37 1;
BA_ "GenSigSendType" SG_ 1669 AMP_DiagReqData38 1;
BA_ "GenSigSendType" SG_ 1669 AMP_DiagReqData39 1;
BA_ "GenSigSendType" SG_ 1669 AMP_DiagReqData40 1;
BA_ "GenSigSendType" SG_ 1669 AMP_DiagReqData41 1;
BA_ "GenSigSendType" SG_ 1669 AMP_DiagReqData42 1;
BA_ "GenSigSendType" SG_ 1669 AMP_DiagReqData43 1;
BA_ "GenSigSendType" SG_ 1669 AMP_DiagReqData44 1;
BA_ "GenSigSendType" SG_ 1669 AMP_DiagReqData45 1;
BA_ "GenSigSendType" SG_ 1669 AMP_DiagReqData46 1;
BA_ "GenSigSendType" SG_ 1669 AMP_DiagReqData47 1;
BA_ "GenSigSendType" SG_ 1669 AMP_DiagReqData48 1;
BA_ "GenSigSendType" SG_ 1669 AMP_DiagReqData49 1;
BA_ "GenSigSendType" SG_ 1669 AMP_DiagReqData50 1;
BA_ "GenSigSendType" SG_ 1669 AMP_DiagReqData51 1;
BA_ "GenSigSendType" SG_ 1669 AMP_DiagReqData52 1;
BA_ "GenSigSendType" SG_ 1669 AMP_DiagReqData53 1;
BA_ "GenSigSendType" SG_ 1669 AMP_DiagReqData54 1;
BA_ "GenSigSendType" SG_ 1669 AMP_DiagReqData55 1;
BA_ "GenSigSendType" SG_ 1669 AMP_DiagReqData56 1;
BA_ "GenSigSendType" SG_ 1669 AMP_DiagReqData57 1;
BA_ "GenSigSendType" SG_ 1669 AMP_DiagReqData58 1;
BA_ "GenSigSendType" SG_ 1669 AMP_DiagReqData59 1;
BA_ "GenSigSendType" SG_ 1669 AMP_DiagReqData60 1;
BA_ "GenSigSendType" SG_ 1669 AMP_DiagReqData61 1;
BA_ "GenSigSendType" SG_ 1669 AMP_DiagReqData62 1;
BA_ "GenSigSendType" SG_ 1669 AMP_DiagReqData63 1;
BA_ "GenSigSendType" SG_ 1549 HUD_DiagRespData0 1;
BA_ "GenSigSendType" SG_ 1549 HUD_DiagRespData1 1;
BA_ "GenSigSendType" SG_ 1549 HUD_DiagRespData2 1;
BA_ "GenSigSendType" SG_ 1549 HUD_DiagRespData3 1;
BA_ "GenSigSendType" SG_ 1549 HUD_DiagRespData4 1;
BA_ "GenSigSendType" SG_ 1549 HUD_DiagRespData5 1;
BA_ "GenSigSendType" SG_ 1549 HUD_DiagRespData6 1;
BA_ "GenSigSendType" SG_ 1549 HUD_DiagRespData7 1;
BA_ "GenSigSendType" SG_ 1549 HUD_DiagRespData8 1;
BA_ "GenSigSendType" SG_ 1549 HUD_DiagRespData9 1;
BA_ "GenSigSendType" SG_ 1549 HUD_DiagRespData10 1;
BA_ "GenSigSendType" SG_ 1549 HUD_DiagRespData11 1;
BA_ "GenSigSendType" SG_ 1549 HUD_DiagRespData12 1;
BA_ "GenSigSendType" SG_ 1549 HUD_DiagRespData13 1;
BA_ "GenSigSendType" SG_ 1549 HUD_DiagRespData14 1;
BA_ "GenSigSendType" SG_ 1549 HUD_DiagRespData15 1;
BA_ "GenSigSendType" SG_ 1549 HUD_DiagRespData16 1;
BA_ "GenSigSendType" SG_ 1549 HUD_DiagRespData17 1;
BA_ "GenSigSendType" SG_ 1549 HUD_DiagRespData18 1;
BA_ "GenSigSendType" SG_ 1549 HUD_DiagRespData19 1;
BA_ "GenSigSendType" SG_ 1549 HUD_DiagRespData20 1;
BA_ "GenSigSendType" SG_ 1549 HUD_DiagRespData21 1;
BA_ "GenSigSendType" SG_ 1549 HUD_DiagRespData22 1;
BA_ "GenSigSendType" SG_ 1549 HUD_DiagRespData23 1;
BA_ "GenSigSendType" SG_ 1549 HUD_DiagRespData24 1;
BA_ "GenSigSendType" SG_ 1549 HUD_DiagRespData25 1;
BA_ "GenSigSendType" SG_ 1549 HUD_DiagRespData26 1;
BA_ "GenSigSendType" SG_ 1549 HUD_DiagRespData27 1;
BA_ "GenSigSendType" SG_ 1549 HUD_DiagRespData28 1;
BA_ "GenSigSendType" SG_ 1549 HUD_DiagRespData29 1;
BA_ "GenSigSendType" SG_ 1549 HUD_DiagRespData30 1;
BA_ "GenSigSendType" SG_ 1549 HUD_DiagRespData31 1;
BA_ "GenSigSendType" SG_ 1549 HUD_DiagRespData32 1;
BA_ "GenSigSendType" SG_ 1549 HUD_DiagRespData33 1;
BA_ "GenSigSendType" SG_ 1549 HUD_DiagRespData34 1;
BA_ "GenSigSendType" SG_ 1549 HUD_DiagRespData35 1;
BA_ "GenSigSendType" SG_ 1549 HUD_DiagRespData36 1;
BA_ "GenSigSendType" SG_ 1549 HUD_DiagRespData37 1;
BA_ "GenSigSendType" SG_ 1549 HUD_DiagRespData38 1;
BA_ "GenSigSendType" SG_ 1549 HUD_DiagRespData39 1;
BA_ "GenSigSendType" SG_ 1549 HUD_DiagRespData40 1;
BA_ "GenSigSendType" SG_ 1549 HUD_DiagRespData41 1;
BA_ "GenSigSendType" SG_ 1549 HUD_DiagRespData42 1;
BA_ "GenSigSendType" SG_ 1549 HUD_DiagRespData43 1;
BA_ "GenSigSendType" SG_ 1549 HUD_DiagRespData44 1;
BA_ "GenSigSendType" SG_ 1549 HUD_DiagRespData45 1;
BA_ "GenSigSendType" SG_ 1549 HUD_DiagRespData46 1;
BA_ "GenSigSendType" SG_ 1549 HUD_DiagRespData47 1;
BA_ "GenSigSendType" SG_ 1549 HUD_DiagRespData48 1;
BA_ "GenSigSendType" SG_ 1549 HUD_DiagRespData49 1;
BA_ "GenSigSendType" SG_ 1549 HUD_DiagRespData50 1;
BA_ "GenSigSendType" SG_ 1549 HUD_DiagRespData51 1;
BA_ "GenSigSendType" SG_ 1549 HUD_DiagRespData52 1;
BA_ "GenSigSendType" SG_ 1549 HUD_DiagRespData53 1;
BA_ "GenSigSendType" SG_ 1549 HUD_DiagRespData54 1;
BA_ "GenSigSendType" SG_ 1549 HUD_DiagRespData55 1;
BA_ "GenSigSendType" SG_ 1549 HUD_DiagRespData56 1;
BA_ "GenSigSendType" SG_ 1549 HUD_DiagRespData57 1;
BA_ "GenSigSendType" SG_ 1549 HUD_DiagRespData58 1;
BA_ "GenSigSendType" SG_ 1549 HUD_DiagRespData59 1;
BA_ "GenSigSendType" SG_ 1549 HUD_DiagRespData60 1;
BA_ "GenSigSendType" SG_ 1549 HUD_DiagRespData61 1;
BA_ "GenSigSendType" SG_ 1549 HUD_DiagRespData62 1;
BA_ "GenSigSendType" SG_ 1549 HUD_DiagRespData63 1;
BA_ "GenSigSendType" SG_ 1677 HUD_DiagReqData0 1;
BA_ "GenSigSendType" SG_ 1677 HUD_DiagReqData1 1;
BA_ "GenSigSendType" SG_ 1677 HUD_DiagReqData2 1;
BA_ "GenSigSendType" SG_ 1677 HUD_DiagReqData3 1;
BA_ "GenSigSendType" SG_ 1677 HUD_DiagReqData4 1;
BA_ "GenSigSendType" SG_ 1677 HUD_DiagReqData5 1;
BA_ "GenSigSendType" SG_ 1677 HUD_DiagReqData6 1;
BA_ "GenSigSendType" SG_ 1677 HUD_DiagReqData7 1;
BA_ "GenSigSendType" SG_ 1677 HUD_DiagReqData8 1;
BA_ "GenSigSendType" SG_ 1677 HUD_DiagReqData9 1;
BA_ "GenSigSendType" SG_ 1677 HUD_DiagReqData10 1;
BA_ "GenSigSendType" SG_ 1677 HUD_DiagReqData11 1;
BA_ "GenSigSendType" SG_ 1677 HUD_DiagReqData12 1;
BA_ "GenSigSendType" SG_ 1677 HUD_DiagReqData13 1;
BA_ "GenSigSendType" SG_ 1677 HUD_DiagReqData14 1;
BA_ "GenSigSendType" SG_ 1677 HUD_DiagReqData15 1;
BA_ "GenSigSendType" SG_ 1677 HUD_DiagReqData16 1;
BA_ "GenSigSendType" SG_ 1677 HUD_DiagReqData17 1;
BA_ "GenSigSendType" SG_ 1677 HUD_DiagReqData18 1;
BA_ "GenSigSendType" SG_ 1677 HUD_DiagReqData19 1;
BA_ "GenSigSendType" SG_ 1677 HUD_DiagReqData20 1;
BA_ "GenSigSendType" SG_ 1677 HUD_DiagReqData21 1;
BA_ "GenSigSendType" SG_ 1677 HUD_DiagReqData22 1;
BA_ "GenSigSendType" SG_ 1677 HUD_DiagReqData23 1;
BA_ "GenSigSendType" SG_ 1677 HUD_DiagReqData24 1;
BA_ "GenSigSendType" SG_ 1677 HUD_DiagReqData25 1;
BA_ "GenSigSendType" SG_ 1677 HUD_DiagReqData26 1;
BA_ "GenSigSendType" SG_ 1677 HUD_DiagReqData27 1;
BA_ "GenSigSendType" SG_ 1677 HUD_DiagReqData28 1;
BA_ "GenSigSendType" SG_ 1677 HUD_DiagReqData29 1;
BA_ "GenSigSendType" SG_ 1677 HUD_DiagReqData30 1;
BA_ "GenSigSendType" SG_ 1677 HUD_DiagReqData31 1;
BA_ "GenSigSendType" SG_ 1677 HUD_DiagReqData32 1;
BA_ "GenSigSendType" SG_ 1677 HUD_DiagReqData33 1;
BA_ "GenSigSendType" SG_ 1677 HUD_DiagReqData34 1;
BA_ "GenSigSendType" SG_ 1677 HUD_DiagReqData35 1;
BA_ "GenSigSendType" SG_ 1677 HUD_DiagReqData36 1;
BA_ "GenSigSendType" SG_ 1677 HUD_DiagReqData37 1;
BA_ "GenSigSendType" SG_ 1677 HUD_DiagReqData38 1;
BA_ "GenSigSendType" SG_ 1677 HUD_DiagReqData39 1;
BA_ "GenSigSendType" SG_ 1677 HUD_DiagReqData40 1;
BA_ "GenSigSendType" SG_ 1677 HUD_DiagReqData41 1;
BA_ "GenSigSendType" SG_ 1677 HUD_DiagReqData42 1;
BA_ "GenSigSendType" SG_ 1677 HUD_DiagReqData43 1;
BA_ "GenSigSendType" SG_ 1677 HUD_DiagReqData44 1;
BA_ "GenSigSendType" SG_ 1677 HUD_DiagReqData45 1;
BA_ "GenSigSendType" SG_ 1677 HUD_DiagReqData46 1;
BA_ "GenSigSendType" SG_ 1677 HUD_DiagReqData47 1;
BA_ "GenSigSendType" SG_ 1677 HUD_DiagReqData48 1;
BA_ "GenSigSendType" SG_ 1677 HUD_DiagReqData49 1;
BA_ "GenSigSendType" SG_ 1677 HUD_DiagReqData50 1;
BA_ "GenSigSendType" SG_ 1677 HUD_DiagReqData51 1;
BA_ "GenSigSendType" SG_ 1677 HUD_DiagReqData52 1;
BA_ "GenSigSendType" SG_ 1677 HUD_DiagReqData53 1;
BA_ "GenSigSendType" SG_ 1677 HUD_DiagReqData54 1;
BA_ "GenSigSendType" SG_ 1677 HUD_DiagReqData55 1;
BA_ "GenSigSendType" SG_ 1677 HUD_DiagReqData56 1;
BA_ "GenSigSendType" SG_ 1677 HUD_DiagReqData57 1;
BA_ "GenSigSendType" SG_ 1677 HUD_DiagReqData58 1;
BA_ "GenSigSendType" SG_ 1677 HUD_DiagReqData59 1;
BA_ "GenSigSendType" SG_ 1677 HUD_DiagReqData60 1;
BA_ "GenSigSendType" SG_ 1677 HUD_DiagReqData61 1;
BA_ "GenSigSendType" SG_ 1677 HUD_DiagReqData62 1;
BA_ "GenSigSendType" SG_ 1677 HUD_DiagReqData63 1;
BA_ "GenSigSendType" SG_ 1540 MHU_DiagRespData0 1;
BA_ "GenSigSendType" SG_ 1540 MHU_DiagRespData1 1;
BA_ "GenSigSendType" SG_ 1540 MHU_DiagRespData2 1;
BA_ "GenSigSendType" SG_ 1540 MHU_DiagRespData3 1;
BA_ "GenSigSendType" SG_ 1540 MHU_DiagRespData4 1;
BA_ "GenSigSendType" SG_ 1540 MHU_DiagRespData5 1;
BA_ "GenSigSendType" SG_ 1540 MHU_DiagRespData6 1;
BA_ "GenSigSendType" SG_ 1540 MHU_DiagRespData7 1;
BA_ "GenSigSendType" SG_ 1540 MHU_DiagRespData8 1;
BA_ "GenSigSendType" SG_ 1540 MHU_DiagRespData9 1;
BA_ "GenSigSendType" SG_ 1540 MHU_DiagRespData10 1;
BA_ "GenSigSendType" SG_ 1540 MHU_DiagRespData11 1;
BA_ "GenSigSendType" SG_ 1540 MHU_DiagRespData12 1;
BA_ "GenSigSendType" SG_ 1540 MHU_DiagRespData13 1;
BA_ "GenSigSendType" SG_ 1540 MHU_DiagRespData14 1;
BA_ "GenSigSendType" SG_ 1540 MHU_DiagRespData15 1;
BA_ "GenSigSendType" SG_ 1540 MHU_DiagRespData16 1;
BA_ "GenSigSendType" SG_ 1540 MHU_DiagRespData17 1;
BA_ "GenSigSendType" SG_ 1540 MHU_DiagRespData18 1;
BA_ "GenSigSendType" SG_ 1540 MHU_DiagRespData19 1;
BA_ "GenSigSendType" SG_ 1540 MHU_DiagRespData20 1;
BA_ "GenSigSendType" SG_ 1540 MHU_DiagRespData21 1;
BA_ "GenSigSendType" SG_ 1540 MHU_DiagRespData22 1;
BA_ "GenSigSendType" SG_ 1540 MHU_DiagRespData23 1;
BA_ "GenSigSendType" SG_ 1540 MHU_DiagRespData24 1;
BA_ "GenSigSendType" SG_ 1540 MHU_DiagRespData25 1;
BA_ "GenSigSendType" SG_ 1540 MHU_DiagRespData26 1;
BA_ "GenSigSendType" SG_ 1540 MHU_DiagRespData27 1;
BA_ "GenSigSendType" SG_ 1540 MHU_DiagRespData28 1;
BA_ "GenSigSendType" SG_ 1540 MHU_DiagRespData29 1;
BA_ "GenSigSendType" SG_ 1540 MHU_DiagRespData30 1;
BA_ "GenSigSendType" SG_ 1540 MHU_DiagRespData31 1;
BA_ "GenSigSendType" SG_ 1540 MHU_DiagRespData32 1;
BA_ "GenSigSendType" SG_ 1540 MHU_DiagRespData33 1;
BA_ "GenSigSendType" SG_ 1540 MHU_DiagRespData34 1;
BA_ "GenSigSendType" SG_ 1540 MHU_DiagRespData35 1;
BA_ "GenSigSendType" SG_ 1540 MHU_DiagRespData36 1;
BA_ "GenSigSendType" SG_ 1540 MHU_DiagRespData37 1;
BA_ "GenSigSendType" SG_ 1540 MHU_DiagRespData38 1;
BA_ "GenSigSendType" SG_ 1540 MHU_DiagRespData39 1;
BA_ "GenSigSendType" SG_ 1540 MHU_DiagRespData40 1;
BA_ "GenSigSendType" SG_ 1540 MHU_DiagRespData41 1;
BA_ "GenSigSendType" SG_ 1540 MHU_DiagRespData42 1;
BA_ "GenSigSendType" SG_ 1540 MHU_DiagRespData43 1;
BA_ "GenSigSendType" SG_ 1540 MHU_DiagRespData44 1;
BA_ "GenSigSendType" SG_ 1540 MHU_DiagRespData45 1;
BA_ "GenSigSendType" SG_ 1540 MHU_DiagRespData46 1;
BA_ "GenSigSendType" SG_ 1540 MHU_DiagRespData47 1;
BA_ "GenSigSendType" SG_ 1540 MHU_DiagRespData48 1;
BA_ "GenSigSendType" SG_ 1540 MHU_DiagRespData49 1;
BA_ "GenSigSendType" SG_ 1540 MHU_DiagRespData50 1;
BA_ "GenSigSendType" SG_ 1540 MHU_DiagRespData51 1;
BA_ "GenSigSendType" SG_ 1540 MHU_DiagRespData52 1;
BA_ "GenSigSendType" SG_ 1540 MHU_DiagRespData53 1;
BA_ "GenSigSendType" SG_ 1540 MHU_DiagRespData54 1;
BA_ "GenSigSendType" SG_ 1540 MHU_DiagRespData55 1;
BA_ "GenSigSendType" SG_ 1540 MHU_DiagRespData56 1;
BA_ "GenSigSendType" SG_ 1540 MHU_DiagRespData57 1;
BA_ "GenSigSendType" SG_ 1540 MHU_DiagRespData58 1;
BA_ "GenSigSendType" SG_ 1540 MHU_DiagRespData59 1;
BA_ "GenSigSendType" SG_ 1540 MHU_DiagRespData60 1;
BA_ "GenSigSendType" SG_ 1540 MHU_DiagRespData61 1;
BA_ "GenSigSendType" SG_ 1540 MHU_DiagRespData62 1;
BA_ "GenSigSendType" SG_ 1540 MHU_DiagRespData63 1;
BA_ "GenSigSendType" SG_ 1668 MHU_DiagReqData0 1;
BA_ "GenSigSendType" SG_ 1668 MHU_DiagReqData1 1;
BA_ "GenSigSendType" SG_ 1668 MHU_DiagReqData2 1;
BA_ "GenSigSendType" SG_ 1668 MHU_DiagReqData3 1;
BA_ "GenSigSendType" SG_ 1668 MHU_DiagReqData4 1;
BA_ "GenSigSendType" SG_ 1668 MHU_DiagReqData5 1;
BA_ "GenSigSendType" SG_ 1668 MHU_DiagReqData6 1;
BA_ "GenSigSendType" SG_ 1668 MHU_DiagReqData7 1;
BA_ "GenSigSendType" SG_ 1668 MHU_DiagReqData8 1;
BA_ "GenSigSendType" SG_ 1668 MHU_DiagReqData9 1;
BA_ "GenSigSendType" SG_ 1668 MHU_DiagReqData10 1;
BA_ "GenSigSendType" SG_ 1668 MHU_DiagReqData11 1;
BA_ "GenSigSendType" SG_ 1668 MHU_DiagReqData12 1;
BA_ "GenSigSendType" SG_ 1668 MHU_DiagReqData13 1;
BA_ "GenSigSendType" SG_ 1668 MHU_DiagReqData14 1;
BA_ "GenSigSendType" SG_ 1668 MHU_DiagReqData15 1;
BA_ "GenSigSendType" SG_ 1668 MHU_DiagReqData16 1;
BA_ "GenSigSendType" SG_ 1668 MHU_DiagReqData17 1;
BA_ "GenSigSendType" SG_ 1668 MHU_DiagReqData18 1;
BA_ "GenSigSendType" SG_ 1668 MHU_DiagReqData19 1;
BA_ "GenSigSendType" SG_ 1668 MHU_DiagReqData20 1;
BA_ "GenSigSendType" SG_ 1668 MHU_DiagReqData21 1;
BA_ "GenSigSendType" SG_ 1668 MHU_DiagReqData22 1;
BA_ "GenSigSendType" SG_ 1668 MHU_DiagReqData23 1;
BA_ "GenSigSendType" SG_ 1668 MHU_DiagReqData24 1;
BA_ "GenSigSendType" SG_ 1668 MHU_DiagReqData25 1;
BA_ "GenSigSendType" SG_ 1668 MHU_DiagReqData26 1;
BA_ "GenSigSendType" SG_ 1668 MHU_DiagReqData27 1;
BA_ "GenSigSendType" SG_ 1668 MHU_DiagReqData28 1;
BA_ "GenSigSendType" SG_ 1668 MHU_DiagReqData29 1;
BA_ "GenSigSendType" SG_ 1668 MHU_DiagReqData30 1;
BA_ "GenSigSendType" SG_ 1668 MHU_DiagReqData31 1;
BA_ "GenSigSendType" SG_ 1668 MHU_DiagReqData32 1;
BA_ "GenSigSendType" SG_ 1668 MHU_DiagReqData33 1;
BA_ "GenSigSendType" SG_ 1668 MHU_DiagReqData34 1;
BA_ "GenSigSendType" SG_ 1668 MHU_DiagReqData35 1;
BA_ "GenSigSendType" SG_ 1668 MHU_DiagReqData36 1;
BA_ "GenSigSendType" SG_ 1668 MHU_DiagReqData37 1;
BA_ "GenSigSendType" SG_ 1668 MHU_DiagReqData38 1;
BA_ "GenSigSendType" SG_ 1668 MHU_DiagReqData39 1;
BA_ "GenSigSendType" SG_ 1668 MHU_DiagReqData40 1;
BA_ "GenSigSendType" SG_ 1668 MHU_DiagReqData41 1;
BA_ "GenSigSendType" SG_ 1668 MHU_DiagReqData42 1;
BA_ "GenSigSendType" SG_ 1668 MHU_DiagReqData43 1;
BA_ "GenSigSendType" SG_ 1668 MHU_DiagReqData44 1;
BA_ "GenSigSendType" SG_ 1668 MHU_DiagReqData45 1;
BA_ "GenSigSendType" SG_ 1668 MHU_DiagReqData46 1;
BA_ "GenSigSendType" SG_ 1668 MHU_DiagReqData47 1;
BA_ "GenSigSendType" SG_ 1668 MHU_DiagReqData48 1;
BA_ "GenSigSendType" SG_ 1668 MHU_DiagReqData49 1;
BA_ "GenSigSendType" SG_ 1668 MHU_DiagReqData50 1;
BA_ "GenSigSendType" SG_ 1668 MHU_DiagReqData51 1;
BA_ "GenSigSendType" SG_ 1668 MHU_DiagReqData52 1;
BA_ "GenSigSendType" SG_ 1668 MHU_DiagReqData53 1;
BA_ "GenSigSendType" SG_ 1668 MHU_DiagReqData54 1;
BA_ "GenSigSendType" SG_ 1668 MHU_DiagReqData55 1;
BA_ "GenSigSendType" SG_ 1668 MHU_DiagReqData56 1;
BA_ "GenSigSendType" SG_ 1668 MHU_DiagReqData57 1;
BA_ "GenSigSendType" SG_ 1668 MHU_DiagReqData58 1;
BA_ "GenSigSendType" SG_ 1668 MHU_DiagReqData59 1;
BA_ "GenSigSendType" SG_ 1668 MHU_DiagReqData60 1;
BA_ "GenSigSendType" SG_ 1668 MHU_DiagReqData61 1;
BA_ "GenSigSendType" SG_ 1668 MHU_DiagReqData62 1;
BA_ "GenSigSendType" SG_ 1668 MHU_DiagReqData63 1;
BA_ "GenSigSendType" SG_ 1701 MRR_DiagReqData0 1;
BA_ "GenSigSendType" SG_ 1701 MRR_DiagReqData1 1;
BA_ "GenSigSendType" SG_ 1701 MRR_DiagReqData2 1;
BA_ "GenSigSendType" SG_ 1701 MRR_DiagReqData3 1;
BA_ "GenSigSendType" SG_ 1701 MRR_DiagReqData4 1;
BA_ "GenSigSendType" SG_ 1701 MRR_DiagReqData5 1;
BA_ "GenSigSendType" SG_ 1701 MRR_DiagReqData6 1;
BA_ "GenSigSendType" SG_ 1701 MRR_DiagReqData7 1;
BA_ "GenSigSendType" SG_ 1701 MRR_DiagReqData8 1;
BA_ "GenSigSendType" SG_ 1701 MRR_DiagReqData9 1;
BA_ "GenSigSendType" SG_ 1701 MRR_DiagReqData10 1;
BA_ "GenSigSendType" SG_ 1701 MRR_DiagReqData11 1;
BA_ "GenSigSendType" SG_ 1701 MRR_DiagReqData12 1;
BA_ "GenSigSendType" SG_ 1701 MRR_DiagReqData13 1;
BA_ "GenSigSendType" SG_ 1701 MRR_DiagReqData14 1;
BA_ "GenSigSendType" SG_ 1701 MRR_DiagReqData15 1;
BA_ "GenSigSendType" SG_ 1701 MRR_DiagReqData16 1;
BA_ "GenSigSendType" SG_ 1701 MRR_DiagReqData17 1;
BA_ "GenSigSendType" SG_ 1701 MRR_DiagReqData18 1;
BA_ "GenSigSendType" SG_ 1701 MRR_DiagReqData19 1;
BA_ "GenSigSendType" SG_ 1701 MRR_DiagReqData20 1;
BA_ "GenSigSendType" SG_ 1701 MRR_DiagReqData21 1;
BA_ "GenSigSendType" SG_ 1701 MRR_DiagReqData22 1;
BA_ "GenSigSendType" SG_ 1701 MRR_DiagReqData23 1;
BA_ "GenSigSendType" SG_ 1701 MRR_DiagReqData24 1;
BA_ "GenSigSendType" SG_ 1701 MRR_DiagReqData25 1;
BA_ "GenSigSendType" SG_ 1701 MRR_DiagReqData26 1;
BA_ "GenSigSendType" SG_ 1701 MRR_DiagReqData27 1;
BA_ "GenSigSendType" SG_ 1701 MRR_DiagReqData28 1;
BA_ "GenSigSendType" SG_ 1701 MRR_DiagReqData29 1;
BA_ "GenSigSendType" SG_ 1701 MRR_DiagReqData30 1;
BA_ "GenSigSendType" SG_ 1701 MRR_DiagReqData31 1;
BA_ "GenSigSendType" SG_ 1701 MRR_DiagReqData32 1;
BA_ "GenSigSendType" SG_ 1701 MRR_DiagReqData33 1;
BA_ "GenSigSendType" SG_ 1701 MRR_DiagReqData34 1;
BA_ "GenSigSendType" SG_ 1701 MRR_DiagReqData35 1;
BA_ "GenSigSendType" SG_ 1701 MRR_DiagReqData36 1;
BA_ "GenSigSendType" SG_ 1701 MRR_DiagReqData37 1;
BA_ "GenSigSendType" SG_ 1701 MRR_DiagReqData38 1;
BA_ "GenSigSendType" SG_ 1701 MRR_DiagReqData39 1;
BA_ "GenSigSendType" SG_ 1701 MRR_DiagReqData40 1;
BA_ "GenSigSendType" SG_ 1701 MRR_DiagReqData41 1;
BA_ "GenSigSendType" SG_ 1701 MRR_DiagReqData42 1;
BA_ "GenSigSendType" SG_ 1701 MRR_DiagReqData43 1;
BA_ "GenSigSendType" SG_ 1701 MRR_DiagReqData44 1;
BA_ "GenSigSendType" SG_ 1701 MRR_DiagReqData45 1;
BA_ "GenSigSendType" SG_ 1701 MRR_DiagReqData46 1;
BA_ "GenSigSendType" SG_ 1701 MRR_DiagReqData47 1;
BA_ "GenSigSendType" SG_ 1701 MRR_DiagReqData48 1;
BA_ "GenSigSendType" SG_ 1701 MRR_DiagReqData49 1;
BA_ "GenSigSendType" SG_ 1701 MRR_DiagReqData50 1;
BA_ "GenSigSendType" SG_ 1701 MRR_DiagReqData51 1;
BA_ "GenSigSendType" SG_ 1701 MRR_DiagReqData52 1;
BA_ "GenSigSendType" SG_ 1701 MRR_DiagReqData53 1;
BA_ "GenSigSendType" SG_ 1701 MRR_DiagReqData54 1;
BA_ "GenSigSendType" SG_ 1701 MRR_DiagReqData55 1;
BA_ "GenSigSendType" SG_ 1701 MRR_DiagReqData56 1;
BA_ "GenSigSendType" SG_ 1701 MRR_DiagReqData57 1;
BA_ "GenSigSendType" SG_ 1701 MRR_DiagReqData58 1;
BA_ "GenSigSendType" SG_ 1701 MRR_DiagReqData59 1;
BA_ "GenSigSendType" SG_ 1701 MRR_DiagReqData60 1;
BA_ "GenSigSendType" SG_ 1701 MRR_DiagReqData61 1;
BA_ "GenSigSendType" SG_ 1701 MRR_DiagReqData62 1;
BA_ "GenSigSendType" SG_ 1701 MRR_DiagReqData63 1;
BA_ "GenSigSendType" SG_ 1573 MRR_DiagRespData0 1;
BA_ "GenSigSendType" SG_ 1573 MRR_DiagRespData1 1;
BA_ "GenSigSendType" SG_ 1573 MRR_DiagRespData2 1;
BA_ "GenSigSendType" SG_ 1573 MRR_DiagRespData3 1;
BA_ "GenSigSendType" SG_ 1573 MRR_DiagRespData4 1;
BA_ "GenSigSendType" SG_ 1573 MRR_DiagRespData5 1;
BA_ "GenSigSendType" SG_ 1573 MRR_DiagRespData6 1;
BA_ "GenSigSendType" SG_ 1573 MRR_DiagRespData7 1;
BA_ "GenSigSendType" SG_ 1573 MRR_DiagRespData8 1;
BA_ "GenSigSendType" SG_ 1573 MRR_DiagRespData9 1;
BA_ "GenSigSendType" SG_ 1573 MRR_DiagRespData10 1;
BA_ "GenSigSendType" SG_ 1573 MRR_DiagRespData11 1;
BA_ "GenSigSendType" SG_ 1573 MRR_DiagRespData12 1;
BA_ "GenSigSendType" SG_ 1573 MRR_DiagRespData13 1;
BA_ "GenSigSendType" SG_ 1573 MRR_DiagRespData14 1;
BA_ "GenSigSendType" SG_ 1573 MRR_DiagRespData15 1;
BA_ "GenSigSendType" SG_ 1573 MRR_DiagRespData16 1;
BA_ "GenSigSendType" SG_ 1573 MRR_DiagRespData17 1;
BA_ "GenSigSendType" SG_ 1573 MRR_DiagRespData18 1;
BA_ "GenSigSendType" SG_ 1573 MRR_DiagRespData19 1;
BA_ "GenSigSendType" SG_ 1573 MRR_DiagRespData20 1;
BA_ "GenSigSendType" SG_ 1573 MRR_DiagRespData21 1;
BA_ "GenSigSendType" SG_ 1573 MRR_DiagRespData22 1;
BA_ "GenSigSendType" SG_ 1573 MRR_DiagRespData23 1;
BA_ "GenSigSendType" SG_ 1573 MRR_DiagRespData24 1;
BA_ "GenSigSendType" SG_ 1573 MRR_DiagRespData25 1;
BA_ "GenSigSendType" SG_ 1573 MRR_DiagRespData26 1;
BA_ "GenSigSendType" SG_ 1573 MRR_DiagRespData27 1;
BA_ "GenSigSendType" SG_ 1573 MRR_DiagRespData28 1;
BA_ "GenSigSendType" SG_ 1573 MRR_DiagRespData29 1;
BA_ "GenSigSendType" SG_ 1573 MRR_DiagRespData30 1;
BA_ "GenSigSendType" SG_ 1573 MRR_DiagRespData31 1;
BA_ "GenSigSendType" SG_ 1573 MRR_DiagRespData32 1;
BA_ "GenSigSendType" SG_ 1573 MRR_DiagRespData33 1;
BA_ "GenSigSendType" SG_ 1573 MRR_DiagRespData34 1;
BA_ "GenSigSendType" SG_ 1573 MRR_DiagRespData35 1;
BA_ "GenSigSendType" SG_ 1573 MRR_DiagRespData36 1;
BA_ "GenSigSendType" SG_ 1573 MRR_DiagRespData37 1;
BA_ "GenSigSendType" SG_ 1573 MRR_DiagRespData38 1;
BA_ "GenSigSendType" SG_ 1573 MRR_DiagRespData39 1;
BA_ "GenSigSendType" SG_ 1573 MRR_DiagRespData40 1;
BA_ "GenSigSendType" SG_ 1573 MRR_DiagRespData41 1;
BA_ "GenSigSendType" SG_ 1573 MRR_DiagRespData42 1;
BA_ "GenSigSendType" SG_ 1573 MRR_DiagRespData43 1;
BA_ "GenSigSendType" SG_ 1573 MRR_DiagRespData44 1;
BA_ "GenSigSendType" SG_ 1573 MRR_DiagRespData45 1;
BA_ "GenSigSendType" SG_ 1573 MRR_DiagRespData46 1;
BA_ "GenSigSendType" SG_ 1573 MRR_DiagRespData47 1;
BA_ "GenSigSendType" SG_ 1573 MRR_DiagRespData48 1;
BA_ "GenSigSendType" SG_ 1573 MRR_DiagRespData49 1;
BA_ "GenSigSendType" SG_ 1573 MRR_DiagRespData50 1;
BA_ "GenSigSendType" SG_ 1573 MRR_DiagRespData51 1;
BA_ "GenSigSendType" SG_ 1573 MRR_DiagRespData52 1;
BA_ "GenSigSendType" SG_ 1573 MRR_DiagRespData53 1;
BA_ "GenSigSendType" SG_ 1573 MRR_DiagRespData54 1;
BA_ "GenSigSendType" SG_ 1573 MRR_DiagRespData55 1;
BA_ "GenSigSendType" SG_ 1573 MRR_DiagRespData56 1;
BA_ "GenSigSendType" SG_ 1573 MRR_DiagRespData57 1;
BA_ "GenSigSendType" SG_ 1573 MRR_DiagRespData58 1;
BA_ "GenSigSendType" SG_ 1573 MRR_DiagRespData59 1;
BA_ "GenSigSendType" SG_ 1573 MRR_DiagRespData60 1;
BA_ "GenSigSendType" SG_ 1573 MRR_DiagRespData61 1;
BA_ "GenSigSendType" SG_ 1573 MRR_DiagRespData62 1;
BA_ "GenSigSendType" SG_ 1573 MRR_DiagRespData63 1;
BA_ "GenSigSendType" SG_ 1719 SRR_RL_DiagReqData0 1;
BA_ "GenSigSendType" SG_ 1719 SRR_RL_DiagReqData1 1;
BA_ "GenSigSendType" SG_ 1719 SRR_RL_DiagReqData2 1;
BA_ "GenSigSendType" SG_ 1719 SRR_RL_DiagReqData3 1;
BA_ "GenSigSendType" SG_ 1719 SRR_RL_DiagReqData4 1;
BA_ "GenSigSendType" SG_ 1719 SRR_RL_DiagReqData5 1;
BA_ "GenSigSendType" SG_ 1719 SRR_RL_DiagReqData6 1;
BA_ "GenSigSendType" SG_ 1719 SRR_RL_DiagReqData7 1;
BA_ "GenSigSendType" SG_ 1719 SRR_RL_DiagReqData8 1;
BA_ "GenSigSendType" SG_ 1719 SRR_RL_DiagReqData9 1;
BA_ "GenSigSendType" SG_ 1719 SRR_RL_DiagReqData10 1;
BA_ "GenSigSendType" SG_ 1719 SRR_RL_DiagReqData11 1;
BA_ "GenSigSendType" SG_ 1719 SRR_RL_DiagReqData12 1;
BA_ "GenSigSendType" SG_ 1719 SRR_RL_DiagReqData13 1;
BA_ "GenSigSendType" SG_ 1719 SRR_RL_DiagReqData14 1;
BA_ "GenSigSendType" SG_ 1719 SRR_RL_DiagReqData15 1;
BA_ "GenSigSendType" SG_ 1719 SRR_RL_DiagReqData16 1;
BA_ "GenSigSendType" SG_ 1719 SRR_RL_DiagReqData17 1;
BA_ "GenSigSendType" SG_ 1719 SRR_RL_DiagReqData18 1;
BA_ "GenSigSendType" SG_ 1719 SRR_RL_DiagReqData19 1;
BA_ "GenSigSendType" SG_ 1719 SRR_RL_DiagReqData20 1;
BA_ "GenSigSendType" SG_ 1719 SRR_RL_DiagReqData21 1;
BA_ "GenSigSendType" SG_ 1719 SRR_RL_DiagReqData22 1;
BA_ "GenSigSendType" SG_ 1719 SRR_RL_DiagReqData23 1;
BA_ "GenSigSendType" SG_ 1719 SRR_RL_DiagReqData24 1;
BA_ "GenSigSendType" SG_ 1719 SRR_RL_DiagReqData25 1;
BA_ "GenSigSendType" SG_ 1719 SRR_RL_DiagReqData26 1;
BA_ "GenSigSendType" SG_ 1719 SRR_RL_DiagReqData27 1;
BA_ "GenSigSendType" SG_ 1719 SRR_RL_DiagReqData28 1;
BA_ "GenSigSendType" SG_ 1719 SRR_RL_DiagReqData29 1;
BA_ "GenSigSendType" SG_ 1719 SRR_RL_DiagReqData30 1;
BA_ "GenSigSendType" SG_ 1719 SRR_RL_DiagReqData31 1;
BA_ "GenSigSendType" SG_ 1719 SRR_RL_DiagReqData32 1;
BA_ "GenSigSendType" SG_ 1719 SRR_RL_DiagReqData33 1;
BA_ "GenSigSendType" SG_ 1719 SRR_RL_DiagReqData34 1;
BA_ "GenSigSendType" SG_ 1719 SRR_RL_DiagReqData35 1;
BA_ "GenSigSendType" SG_ 1719 SRR_RL_DiagReqData36 1;
BA_ "GenSigSendType" SG_ 1719 SRR_RL_DiagReqData37 1;
BA_ "GenSigSendType" SG_ 1719 SRR_RL_DiagReqData38 1;
BA_ "GenSigSendType" SG_ 1719 SRR_RL_DiagReqData39 1;
BA_ "GenSigSendType" SG_ 1719 SRR_RL_DiagReqData40 1;
BA_ "GenSigSendType" SG_ 1719 SRR_RL_DiagReqData41 1;
BA_ "GenSigSendType" SG_ 1719 SRR_RL_DiagReqData42 1;
BA_ "GenSigSendType" SG_ 1719 SRR_RL_DiagReqData43 1;
BA_ "GenSigSendType" SG_ 1719 SRR_RL_DiagReqData44 1;
BA_ "GenSigSendType" SG_ 1719 SRR_RL_DiagReqData45 1;
BA_ "GenSigSendType" SG_ 1719 SRR_RL_DiagReqData46 1;
BA_ "GenSigSendType" SG_ 1719 SRR_RL_DiagReqData47 1;
BA_ "GenSigSendType" SG_ 1719 SRR_RL_DiagReqData48 1;
BA_ "GenSigSendType" SG_ 1719 SRR_RL_DiagReqData49 1;
BA_ "GenSigSendType" SG_ 1719 SRR_RL_DiagReqData50 1;
BA_ "GenSigSendType" SG_ 1719 SRR_RL_DiagReqData51 1;
BA_ "GenSigSendType" SG_ 1719 SRR_RL_DiagReqData52 1;
BA_ "GenSigSendType" SG_ 1719 SRR_RL_DiagReqData53 1;
BA_ "GenSigSendType" SG_ 1719 SRR_RL_DiagReqData54 1;
BA_ "GenSigSendType" SG_ 1719 SRR_RL_DiagReqData55 1;
BA_ "GenSigSendType" SG_ 1719 SRR_RL_DiagReqData56 1;
BA_ "GenSigSendType" SG_ 1719 SRR_RL_DiagReqData57 1;
BA_ "GenSigSendType" SG_ 1719 SRR_RL_DiagReqData58 1;
BA_ "GenSigSendType" SG_ 1719 SRR_RL_DiagReqData59 1;
BA_ "GenSigSendType" SG_ 1719 SRR_RL_DiagReqData60 1;
BA_ "GenSigSendType" SG_ 1719 SRR_RL_DiagReqData61 1;
BA_ "GenSigSendType" SG_ 1719 SRR_RL_DiagReqData62 1;
BA_ "GenSigSendType" SG_ 1719 SRR_RL_DiagReqData63 1;
BA_ "GenSigSendType" SG_ 1591 SRR_RL_DiagRespData0 1;
BA_ "GenSigSendType" SG_ 1591 SRR_RL_DiagRespData1 1;
BA_ "GenSigSendType" SG_ 1591 SRR_RL_DiagRespData2 1;
BA_ "GenSigSendType" SG_ 1591 SRR_RL_DiagRespData3 1;
BA_ "GenSigSendType" SG_ 1591 SRR_RL_DiagRespData4 1;
BA_ "GenSigSendType" SG_ 1591 SRR_RL_DiagRespData5 1;
BA_ "GenSigSendType" SG_ 1591 SRR_RL_DiagRespData6 1;
BA_ "GenSigSendType" SG_ 1591 SRR_RL_DiagRespData7 1;
BA_ "GenSigSendType" SG_ 1591 SRR_RL_DiagRespData8 1;
BA_ "GenSigSendType" SG_ 1591 SRR_RL_DiagRespData9 1;
BA_ "GenSigSendType" SG_ 1591 SRR_RL_DiagRespData10 1;
BA_ "GenSigSendType" SG_ 1591 SRR_RL_DiagRespData11 1;
BA_ "GenSigSendType" SG_ 1591 SRR_RL_DiagRespData12 1;
BA_ "GenSigSendType" SG_ 1591 SRR_RL_DiagRespData13 1;
BA_ "GenSigSendType" SG_ 1591 SRR_RL_DiagRespData14 1;
BA_ "GenSigSendType" SG_ 1591 SRR_RL_DiagRespData15 1;
BA_ "GenSigSendType" SG_ 1591 SRR_RL_DiagRespData16 1;
BA_ "GenSigSendType" SG_ 1591 SRR_RL_DiagRespData17 1;
BA_ "GenSigSendType" SG_ 1591 SRR_RL_DiagRespData18 1;
BA_ "GenSigSendType" SG_ 1591 SRR_RL_DiagRespData19 1;
BA_ "GenSigSendType" SG_ 1591 SRR_RL_DiagRespData20 1;
BA_ "GenSigSendType" SG_ 1591 SRR_RL_DiagRespData21 1;
BA_ "GenSigSendType" SG_ 1591 SRR_RL_DiagRespData22 1;
BA_ "GenSigSendType" SG_ 1591 SRR_RL_DiagRespData23 1;
BA_ "GenSigSendType" SG_ 1591 SRR_RL_DiagRespData24 1;
BA_ "GenSigSendType" SG_ 1591 SRR_RL_DiagRespData25 1;
BA_ "GenSigSendType" SG_ 1591 SRR_RL_DiagRespData26 1;
BA_ "GenSigSendType" SG_ 1591 SRR_RL_DiagRespData27 1;
BA_ "GenSigSendType" SG_ 1591 SRR_RL_DiagRespData28 1;
BA_ "GenSigSendType" SG_ 1591 SRR_RL_DiagRespData29 1;
BA_ "GenSigSendType" SG_ 1591 SRR_RL_DiagRespData30 1;
BA_ "GenSigSendType" SG_ 1591 SRR_RL_DiagRespData31 1;
BA_ "GenSigSendType" SG_ 1591 SRR_RL_DiagRespData32 1;
BA_ "GenSigSendType" SG_ 1591 SRR_RL_DiagRespData33 1;
BA_ "GenSigSendType" SG_ 1591 SRR_RL_DiagRespData34 1;
BA_ "GenSigSendType" SG_ 1591 SRR_RL_DiagRespData35 1;
BA_ "GenSigSendType" SG_ 1591 SRR_RL_DiagRespData36 1;
BA_ "GenSigSendType" SG_ 1591 SRR_RL_DiagRespData37 1;
BA_ "GenSigSendType" SG_ 1591 SRR_RL_DiagRespData38 1;
BA_ "GenSigSendType" SG_ 1591 SRR_RL_DiagRespData39 1;
BA_ "GenSigSendType" SG_ 1591 SRR_RL_DiagRespData40 1;
BA_ "GenSigSendType" SG_ 1591 SRR_RL_DiagRespData41 1;
BA_ "GenSigSendType" SG_ 1591 SRR_RL_DiagRespData42 1;
BA_ "GenSigSendType" SG_ 1591 SRR_RL_DiagRespData43 1;
BA_ "GenSigSendType" SG_ 1591 SRR_RL_DiagRespData44 1;
BA_ "GenSigSendType" SG_ 1591 SRR_RL_DiagRespData45 1;
BA_ "GenSigSendType" SG_ 1591 SRR_RL_DiagRespData46 1;
BA_ "GenSigSendType" SG_ 1591 SRR_RL_DiagRespData47 1;
BA_ "GenSigSendType" SG_ 1591 SRR_RL_DiagRespData48 1;
BA_ "GenSigSendType" SG_ 1591 SRR_RL_DiagRespData49 1;
BA_ "GenSigSendType" SG_ 1591 SRR_RL_DiagRespData50 1;
BA_ "GenSigSendType" SG_ 1591 SRR_RL_DiagRespData51 1;
BA_ "GenSigSendType" SG_ 1591 SRR_RL_DiagRespData52 1;
BA_ "GenSigSendType" SG_ 1591 SRR_RL_DiagRespData53 1;
BA_ "GenSigSendType" SG_ 1591 SRR_RL_DiagRespData54 1;
BA_ "GenSigSendType" SG_ 1591 SRR_RL_DiagRespData55 1;
BA_ "GenSigSendType" SG_ 1591 SRR_RL_DiagRespData56 1;
BA_ "GenSigSendType" SG_ 1591 SRR_RL_DiagRespData57 1;
BA_ "GenSigSendType" SG_ 1591 SRR_RL_DiagRespData58 1;
BA_ "GenSigSendType" SG_ 1591 SRR_RL_DiagRespData59 1;
BA_ "GenSigSendType" SG_ 1591 SRR_RL_DiagRespData60 1;
BA_ "GenSigSendType" SG_ 1591 SRR_RL_DiagRespData61 1;
BA_ "GenSigSendType" SG_ 1591 SRR_RL_DiagRespData62 1;
BA_ "GenSigSendType" SG_ 1591 SRR_RL_DiagRespData63 1;
BA_ "GenSigSendType" SG_ 1718 SRR_RR_DiagReqData0 1;
BA_ "GenSigSendType" SG_ 1718 SRR_RR_DiagReqData1 1;
BA_ "GenSigSendType" SG_ 1718 SRR_RR_DiagReqData2 1;
BA_ "GenSigSendType" SG_ 1718 SRR_RR_DiagReqData3 1;
BA_ "GenSigSendType" SG_ 1718 SRR_RR_DiagReqData4 1;
BA_ "GenSigSendType" SG_ 1718 SRR_RR_DiagReqData5 1;
BA_ "GenSigSendType" SG_ 1718 SRR_RR_DiagReqData6 1;
BA_ "GenSigSendType" SG_ 1718 SRR_RR_DiagReqData7 1;
BA_ "GenSigSendType" SG_ 1718 SRR_RR_DiagReqData8 1;
BA_ "GenSigSendType" SG_ 1718 SRR_RR_DiagReqData9 1;
BA_ "GenSigSendType" SG_ 1718 SRR_RR_DiagReqData10 1;
BA_ "GenSigSendType" SG_ 1718 SRR_RR_DiagReqData11 1;
BA_ "GenSigSendType" SG_ 1718 SRR_RR_DiagReqData12 1;
BA_ "GenSigSendType" SG_ 1718 SRR_RR_DiagReqData13 1;
BA_ "GenSigSendType" SG_ 1718 SRR_RR_DiagReqData14 1;
BA_ "GenSigSendType" SG_ 1718 SRR_RR_DiagReqData15 1;
BA_ "GenSigSendType" SG_ 1718 SRR_RR_DiagReqData16 1;
BA_ "GenSigSendType" SG_ 1718 SRR_RR_DiagReqData17 1;
BA_ "GenSigSendType" SG_ 1718 SRR_RR_DiagReqData18 1;
BA_ "GenSigSendType" SG_ 1718 SRR_RR_DiagReqData19 1;
BA_ "GenSigSendType" SG_ 1718 SRR_RR_DiagReqData20 1;
BA_ "GenSigSendType" SG_ 1718 SRR_RR_DiagReqData21 1;
BA_ "GenSigSendType" SG_ 1718 SRR_RR_DiagReqData22 1;
BA_ "GenSigSendType" SG_ 1718 SRR_RR_DiagReqData23 1;
BA_ "GenSigSendType" SG_ 1718 SRR_RR_DiagReqData24 1;
BA_ "GenSigSendType" SG_ 1718 SRR_RR_DiagReqData25 1;
BA_ "GenSigSendType" SG_ 1718 SRR_RR_DiagReqData26 1;
BA_ "GenSigSendType" SG_ 1718 SRR_RR_DiagReqData27 1;
BA_ "GenSigSendType" SG_ 1718 SRR_RR_DiagReqData28 1;
BA_ "GenSigSendType" SG_ 1718 SRR_RR_DiagReqData29 1;
BA_ "GenSigSendType" SG_ 1718 SRR_RR_DiagReqData30 1;
BA_ "GenSigSendType" SG_ 1718 SRR_RR_DiagReqData31 1;
BA_ "GenSigSendType" SG_ 1718 SRR_RR_DiagReqData32 1;
BA_ "GenSigSendType" SG_ 1718 SRR_RR_DiagReqData33 1;
BA_ "GenSigSendType" SG_ 1718 SRR_RR_DiagReqData34 1;
BA_ "GenSigSendType" SG_ 1718 SRR_RR_DiagReqData35 1;
BA_ "GenSigSendType" SG_ 1718 SRR_RR_DiagReqData36 1;
BA_ "GenSigSendType" SG_ 1718 SRR_RR_DiagReqData37 1;
BA_ "GenSigSendType" SG_ 1718 SRR_RR_DiagReqData38 1;
BA_ "GenSigSendType" SG_ 1718 SRR_RR_DiagReqData39 1;
BA_ "GenSigSendType" SG_ 1718 SRR_RR_DiagReqData40 1;
BA_ "GenSigSendType" SG_ 1718 SRR_RR_DiagReqData41 1;
BA_ "GenSigSendType" SG_ 1718 SRR_RR_DiagReqData42 1;
BA_ "GenSigSendType" SG_ 1718 SRR_RR_DiagReqData43 1;
BA_ "GenSigSendType" SG_ 1718 SRR_RR_DiagReqData44 1;
BA_ "GenSigSendType" SG_ 1718 SRR_RR_DiagReqData45 1;
BA_ "GenSigSendType" SG_ 1718 SRR_RR_DiagReqData46 1;
BA_ "GenSigSendType" SG_ 1718 SRR_RR_DiagReqData47 1;
BA_ "GenSigSendType" SG_ 1718 SRR_RR_DiagReqData48 1;
BA_ "GenSigSendType" SG_ 1718 SRR_RR_DiagReqData49 1;
BA_ "GenSigSendType" SG_ 1718 SRR_RR_DiagReqData50 1;
BA_ "GenSigSendType" SG_ 1718 SRR_RR_DiagReqData51 1;
BA_ "GenSigSendType" SG_ 1718 SRR_RR_DiagReqData52 1;
BA_ "GenSigSendType" SG_ 1718 SRR_RR_DiagReqData53 1;
BA_ "GenSigSendType" SG_ 1718 SRR_RR_DiagReqData54 1;
BA_ "GenSigSendType" SG_ 1718 SRR_RR_DiagReqData55 1;
BA_ "GenSigSendType" SG_ 1718 SRR_RR_DiagReqData56 1;
BA_ "GenSigSendType" SG_ 1718 SRR_RR_DiagReqData57 1;
BA_ "GenSigSendType" SG_ 1718 SRR_RR_DiagReqData58 1;
BA_ "GenSigSendType" SG_ 1718 SRR_RR_DiagReqData59 1;
BA_ "GenSigSendType" SG_ 1718 SRR_RR_DiagReqData60 1;
BA_ "GenSigSendType" SG_ 1718 SRR_RR_DiagReqData61 1;
BA_ "GenSigSendType" SG_ 1718 SRR_RR_DiagReqData62 1;
BA_ "GenSigSendType" SG_ 1718 SRR_RR_DiagReqData63 1;
BA_ "GenSigSendType" SG_ 1590 SRR_RR_DiagRespData0 1;
BA_ "GenSigSendType" SG_ 1590 SRR_RR_DiagRespData1 1;
BA_ "GenSigSendType" SG_ 1590 SRR_RR_DiagRespData2 1;
BA_ "GenSigSendType" SG_ 1590 SRR_RR_DiagRespData3 1;
BA_ "GenSigSendType" SG_ 1590 SRR_RR_DiagRespData4 1;
BA_ "GenSigSendType" SG_ 1590 SRR_RR_DiagRespData5 1;
BA_ "GenSigSendType" SG_ 1590 SRR_RR_DiagRespData6 1;
BA_ "GenSigSendType" SG_ 1590 SRR_RR_DiagRespData7 1;
BA_ "GenSigSendType" SG_ 1590 SRR_RR_DiagRespData8 1;
BA_ "GenSigSendType" SG_ 1590 SRR_RR_DiagRespData9 1;
BA_ "GenSigSendType" SG_ 1590 SRR_RR_DiagRespData10 1;
BA_ "GenSigSendType" SG_ 1590 SRR_RR_DiagRespData11 1;
BA_ "GenSigSendType" SG_ 1590 SRR_RR_DiagRespData12 1;
BA_ "GenSigSendType" SG_ 1590 SRR_RR_DiagRespData13 1;
BA_ "GenSigSendType" SG_ 1590 SRR_RR_DiagRespData14 1;
BA_ "GenSigSendType" SG_ 1590 SRR_RR_DiagRespData15 1;
BA_ "GenSigSendType" SG_ 1590 SRR_RR_DiagRespData16 1;
BA_ "GenSigSendType" SG_ 1590 SRR_RR_DiagRespData17 1;
BA_ "GenSigSendType" SG_ 1590 SRR_RR_DiagRespData18 1;
BA_ "GenSigSendType" SG_ 1590 SRR_RR_DiagRespData19 1;
BA_ "GenSigSendType" SG_ 1590 SRR_RR_DiagRespData20 1;
BA_ "GenSigSendType" SG_ 1590 SRR_RR_DiagRespData21 1;
BA_ "GenSigSendType" SG_ 1590 SRR_RR_DiagRespData22 1;
BA_ "GenSigSendType" SG_ 1590 SRR_RR_DiagRespData23 1;
BA_ "GenSigSendType" SG_ 1590 SRR_RR_DiagRespData24 1;
BA_ "GenSigSendType" SG_ 1590 SRR_RR_DiagRespData25 1;
BA_ "GenSigSendType" SG_ 1590 SRR_RR_DiagRespData26 1;
BA_ "GenSigSendType" SG_ 1590 SRR_RR_DiagRespData27 1;
BA_ "GenSigSendType" SG_ 1590 SRR_RR_DiagRespData28 1;
BA_ "GenSigSendType" SG_ 1590 SRR_RR_DiagRespData29 1;
BA_ "GenSigSendType" SG_ 1590 SRR_RR_DiagRespData30 1;
BA_ "GenSigSendType" SG_ 1590 SRR_RR_DiagRespData31 1;
BA_ "GenSigSendType" SG_ 1590 SRR_RR_DiagRespData32 1;
BA_ "GenSigSendType" SG_ 1590 SRR_RR_DiagRespData33 1;
BA_ "GenSigSendType" SG_ 1590 SRR_RR_DiagRespData34 1;
BA_ "GenSigSendType" SG_ 1590 SRR_RR_DiagRespData35 1;
BA_ "GenSigSendType" SG_ 1590 SRR_RR_DiagRespData36 1;
BA_ "GenSigSendType" SG_ 1590 SRR_RR_DiagRespData37 1;
BA_ "GenSigSendType" SG_ 1590 SRR_RR_DiagRespData38 1;
BA_ "GenSigSendType" SG_ 1590 SRR_RR_DiagRespData39 1;
BA_ "GenSigSendType" SG_ 1590 SRR_RR_DiagRespData40 1;
BA_ "GenSigSendType" SG_ 1590 SRR_RR_DiagRespData41 1;
BA_ "GenSigSendType" SG_ 1590 SRR_RR_DiagRespData42 1;
BA_ "GenSigSendType" SG_ 1590 SRR_RR_DiagRespData43 1;
BA_ "GenSigSendType" SG_ 1590 SRR_RR_DiagRespData44 1;
BA_ "GenSigSendType" SG_ 1590 SRR_RR_DiagRespData45 1;
BA_ "GenSigSendType" SG_ 1590 SRR_RR_DiagRespData46 1;
BA_ "GenSigSendType" SG_ 1590 SRR_RR_DiagRespData47 1;
BA_ "GenSigSendType" SG_ 1590 SRR_RR_DiagRespData48 1;
BA_ "GenSigSendType" SG_ 1590 SRR_RR_DiagRespData49 1;
BA_ "GenSigSendType" SG_ 1590 SRR_RR_DiagRespData50 1;
BA_ "GenSigSendType" SG_ 1590 SRR_RR_DiagRespData51 1;
BA_ "GenSigSendType" SG_ 1590 SRR_RR_DiagRespData52 1;
BA_ "GenSigSendType" SG_ 1590 SRR_RR_DiagRespData53 1;
BA_ "GenSigSendType" SG_ 1590 SRR_RR_DiagRespData54 1;
BA_ "GenSigSendType" SG_ 1590 SRR_RR_DiagRespData55 1;
BA_ "GenSigSendType" SG_ 1590 SRR_RR_DiagRespData56 1;
BA_ "GenSigSendType" SG_ 1590 SRR_RR_DiagRespData57 1;
BA_ "GenSigSendType" SG_ 1590 SRR_RR_DiagRespData58 1;
BA_ "GenSigSendType" SG_ 1590 SRR_RR_DiagRespData59 1;
BA_ "GenSigSendType" SG_ 1590 SRR_RR_DiagRespData60 1;
BA_ "GenSigSendType" SG_ 1590 SRR_RR_DiagRespData61 1;
BA_ "GenSigSendType" SG_ 1590 SRR_RR_DiagRespData62 1;
BA_ "GenSigSendType" SG_ 1590 SRR_RR_DiagRespData63 1;
BA_ "GenSigSendType" SG_ 1717 SRR_FL_DiagReqData0 1;
BA_ "GenSigSendType" SG_ 1717 SRR_FL_DiagReqData1 1;
BA_ "GenSigSendType" SG_ 1717 SRR_FL_DiagReqData2 1;
BA_ "GenSigSendType" SG_ 1717 SRR_FL_DiagReqData3 1;
BA_ "GenSigSendType" SG_ 1717 SRR_FL_DiagReqData4 1;
BA_ "GenSigSendType" SG_ 1717 SRR_FL_DiagReqData5 1;
BA_ "GenSigSendType" SG_ 1717 SRR_FL_DiagReqData6 1;
BA_ "GenSigSendType" SG_ 1717 SRR_FL_DiagReqData7 1;
BA_ "GenSigSendType" SG_ 1717 SRR_FL_DiagReqData8 1;
BA_ "GenSigSendType" SG_ 1717 SRR_FL_DiagReqData9 1;
BA_ "GenSigSendType" SG_ 1717 SRR_FL_DiagReqData10 1;
BA_ "GenSigSendType" SG_ 1717 SRR_FL_DiagReqData11 1;
BA_ "GenSigSendType" SG_ 1717 SRR_FL_DiagReqData12 1;
BA_ "GenSigSendType" SG_ 1717 SRR_FL_DiagReqData13 1;
BA_ "GenSigSendType" SG_ 1717 SRR_FL_DiagReqData14 1;
BA_ "GenSigSendType" SG_ 1717 SRR_FL_DiagReqData15 1;
BA_ "GenSigSendType" SG_ 1717 SRR_FL_DiagReqData16 1;
BA_ "GenSigSendType" SG_ 1717 SRR_FL_DiagReqData17 1;
BA_ "GenSigSendType" SG_ 1717 SRR_FL_DiagReqData18 1;
BA_ "GenSigSendType" SG_ 1717 SRR_FL_DiagReqData19 1;
BA_ "GenSigSendType" SG_ 1717 SRR_FL_DiagReqData20 1;
BA_ "GenSigSendType" SG_ 1717 SRR_FL_DiagReqData21 1;
BA_ "GenSigSendType" SG_ 1717 SRR_FL_DiagReqData22 1;
BA_ "GenSigSendType" SG_ 1717 SRR_FL_DiagReqData23 1;
BA_ "GenSigSendType" SG_ 1717 SRR_FL_DiagReqData24 1;
BA_ "GenSigSendType" SG_ 1717 SRR_FL_DiagReqData25 1;
BA_ "GenSigSendType" SG_ 1717 SRR_FL_DiagReqData26 1;
BA_ "GenSigSendType" SG_ 1717 SRR_FL_DiagReqData27 1;
BA_ "GenSigSendType" SG_ 1717 SRR_FL_DiagReqData28 1;
BA_ "GenSigSendType" SG_ 1717 SRR_FL_DiagReqData29 1;
BA_ "GenSigSendType" SG_ 1717 SRR_FL_DiagReqData30 1;
BA_ "GenSigSendType" SG_ 1717 SRR_FL_DiagReqData31 1;
BA_ "GenSigSendType" SG_ 1717 SRR_FL_DiagReqData32 1;
BA_ "GenSigSendType" SG_ 1717 SRR_FL_DiagReqData33 1;
BA_ "GenSigSendType" SG_ 1717 SRR_FL_DiagReqData34 1;
BA_ "GenSigSendType" SG_ 1717 SRR_FL_DiagReqData35 1;
BA_ "GenSigSendType" SG_ 1717 SRR_FL_DiagReqData36 1;
BA_ "GenSigSendType" SG_ 1717 SRR_FL_DiagReqData37 1;
BA_ "GenSigSendType" SG_ 1717 SRR_FL_DiagReqData38 1;
BA_ "GenSigSendType" SG_ 1717 SRR_FL_DiagReqData39 1;
BA_ "GenSigSendType" SG_ 1717 SRR_FL_DiagReqData40 1;
BA_ "GenSigSendType" SG_ 1717 SRR_FL_DiagReqData41 1;
BA_ "GenSigSendType" SG_ 1717 SRR_FL_DiagReqData42 1;
BA_ "GenSigSendType" SG_ 1717 SRR_FL_DiagReqData43 1;
BA_ "GenSigSendType" SG_ 1717 SRR_FL_DiagReqData44 1;
BA_ "GenSigSendType" SG_ 1717 SRR_FL_DiagReqData45 1;
BA_ "GenSigSendType" SG_ 1717 SRR_FL_DiagReqData46 1;
BA_ "GenSigSendType" SG_ 1717 SRR_FL_DiagReqData47 1;
BA_ "GenSigSendType" SG_ 1717 SRR_FL_DiagReqData48 1;
BA_ "GenSigSendType" SG_ 1717 SRR_FL_DiagReqData49 1;
BA_ "GenSigSendType" SG_ 1717 SRR_FL_DiagReqData50 1;
BA_ "GenSigSendType" SG_ 1717 SRR_FL_DiagReqData51 1;
BA_ "GenSigSendType" SG_ 1717 SRR_FL_DiagReqData52 1;
BA_ "GenSigSendType" SG_ 1717 SRR_FL_DiagReqData53 1;
BA_ "GenSigSendType" SG_ 1717 SRR_FL_DiagReqData54 1;
BA_ "GenSigSendType" SG_ 1717 SRR_FL_DiagReqData55 1;
BA_ "GenSigSendType" SG_ 1717 SRR_FL_DiagReqData56 1;
BA_ "GenSigSendType" SG_ 1717 SRR_FL_DiagReqData57 1;
BA_ "GenSigSendType" SG_ 1717 SRR_FL_DiagReqData58 1;
BA_ "GenSigSendType" SG_ 1717 SRR_FL_DiagReqData59 1;
BA_ "GenSigSendType" SG_ 1717 SRR_FL_DiagReqData60 1;
BA_ "GenSigSendType" SG_ 1717 SRR_FL_DiagReqData61 1;
BA_ "GenSigSendType" SG_ 1717 SRR_FL_DiagReqData62 1;
BA_ "GenSigSendType" SG_ 1717 SRR_FL_DiagReqData63 1;
BA_ "GenSigSendType" SG_ 1589 SRR_FL_DiagRespData0 1;
BA_ "GenSigSendType" SG_ 1589 SRR_FL_DiagRespData1 1;
BA_ "GenSigSendType" SG_ 1589 SRR_FL_DiagRespData2 1;
BA_ "GenSigSendType" SG_ 1589 SRR_FL_DiagRespData3 1;
BA_ "GenSigSendType" SG_ 1589 SRR_FL_DiagRespData4 1;
BA_ "GenSigSendType" SG_ 1589 SRR_FL_DiagRespData5 1;
BA_ "GenSigSendType" SG_ 1589 SRR_FL_DiagRespData6 1;
BA_ "GenSigSendType" SG_ 1589 SRR_FL_DiagRespData7 1;
BA_ "GenSigSendType" SG_ 1589 SRR_FL_DiagRespData8 1;
BA_ "GenSigSendType" SG_ 1589 SRR_FL_DiagRespData9 1;
BA_ "GenSigSendType" SG_ 1589 SRR_FL_DiagRespData10 1;
BA_ "GenSigSendType" SG_ 1589 SRR_FL_DiagRespData11 1;
BA_ "GenSigSendType" SG_ 1589 SRR_FL_DiagRespData12 1;
BA_ "GenSigSendType" SG_ 1589 SRR_FL_DiagRespData13 1;
BA_ "GenSigSendType" SG_ 1589 SRR_FL_DiagRespData14 1;
BA_ "GenSigSendType" SG_ 1589 SRR_FL_DiagRespData15 1;
BA_ "GenSigSendType" SG_ 1589 SRR_FL_DiagRespData16 1;
BA_ "GenSigSendType" SG_ 1589 SRR_FL_DiagRespData17 1;
BA_ "GenSigSendType" SG_ 1589 SRR_FL_DiagRespData18 1;
BA_ "GenSigSendType" SG_ 1589 SRR_FL_DiagRespData19 1;
BA_ "GenSigSendType" SG_ 1589 SRR_FL_DiagRespData20 1;
BA_ "GenSigSendType" SG_ 1589 SRR_FL_DiagRespData21 1;
BA_ "GenSigSendType" SG_ 1589 SRR_FL_DiagRespData22 1;
BA_ "GenSigSendType" SG_ 1589 SRR_FL_DiagRespData23 1;
BA_ "GenSigSendType" SG_ 1589 SRR_FL_DiagRespData24 1;
BA_ "GenSigSendType" SG_ 1589 SRR_FL_DiagRespData25 1;
BA_ "GenSigSendType" SG_ 1589 SRR_FL_DiagRespData26 1;
BA_ "GenSigSendType" SG_ 1589 SRR_FL_DiagRespData27 1;
BA_ "GenSigSendType" SG_ 1589 SRR_FL_DiagRespData28 1;
BA_ "GenSigSendType" SG_ 1589 SRR_FL_DiagRespData29 1;
BA_ "GenSigSendType" SG_ 1589 SRR_FL_DiagRespData30 1;
BA_ "GenSigSendType" SG_ 1589 SRR_FL_DiagRespData31 1;
BA_ "GenSigSendType" SG_ 1589 SRR_FL_DiagRespData32 1;
BA_ "GenSigSendType" SG_ 1589 SRR_FL_DiagRespData33 1;
BA_ "GenSigSendType" SG_ 1589 SRR_FL_DiagRespData34 1;
BA_ "GenSigSendType" SG_ 1589 SRR_FL_DiagRespData35 1;
BA_ "GenSigSendType" SG_ 1589 SRR_FL_DiagRespData36 1;
BA_ "GenSigSendType" SG_ 1589 SRR_FL_DiagRespData37 1;
BA_ "GenSigSendType" SG_ 1589 SRR_FL_DiagRespData38 1;
BA_ "GenSigSendType" SG_ 1589 SRR_FL_DiagRespData39 1;
BA_ "GenSigSendType" SG_ 1589 SRR_FL_DiagRespData40 1;
BA_ "GenSigSendType" SG_ 1589 SRR_FL_DiagRespData41 1;
BA_ "GenSigSendType" SG_ 1589 SRR_FL_DiagRespData42 1;
BA_ "GenSigSendType" SG_ 1589 SRR_FL_DiagRespData43 1;
BA_ "GenSigSendType" SG_ 1589 SRR_FL_DiagRespData44 1;
BA_ "GenSigSendType" SG_ 1589 SRR_FL_DiagRespData45 1;
BA_ "GenSigSendType" SG_ 1589 SRR_FL_DiagRespData46 1;
BA_ "GenSigSendType" SG_ 1589 SRR_FL_DiagRespData47 1;
BA_ "GenSigSendType" SG_ 1589 SRR_FL_DiagRespData48 1;
BA_ "GenSigSendType" SG_ 1589 SRR_FL_DiagRespData49 1;
BA_ "GenSigSendType" SG_ 1589 SRR_FL_DiagRespData50 1;
BA_ "GenSigSendType" SG_ 1589 SRR_FL_DiagRespData51 1;
BA_ "GenSigSendType" SG_ 1589 SRR_FL_DiagRespData52 1;
BA_ "GenSigSendType" SG_ 1589 SRR_FL_DiagRespData53 1;
BA_ "GenSigSendType" SG_ 1589 SRR_FL_DiagRespData54 1;
BA_ "GenSigSendType" SG_ 1589 SRR_FL_DiagRespData55 1;
BA_ "GenSigSendType" SG_ 1589 SRR_FL_DiagRespData56 1;
BA_ "GenSigSendType" SG_ 1589 SRR_FL_DiagRespData57 1;
BA_ "GenSigSendType" SG_ 1589 SRR_FL_DiagRespData58 1;
BA_ "GenSigSendType" SG_ 1589 SRR_FL_DiagRespData59 1;
BA_ "GenSigSendType" SG_ 1589 SRR_FL_DiagRespData60 1;
BA_ "GenSigSendType" SG_ 1589 SRR_FL_DiagRespData61 1;
BA_ "GenSigSendType" SG_ 1589 SRR_FL_DiagRespData62 1;
BA_ "GenSigSendType" SG_ 1589 SRR_FL_DiagRespData63 1;
BA_ "GenSigSendType" SG_ 1716 SRR_FR_DiagReqData0 1;
BA_ "GenSigSendType" SG_ 1716 SRR_FR_DiagReqData1 1;
BA_ "GenSigSendType" SG_ 1716 SRR_FR_DiagReqData2 1;
BA_ "GenSigSendType" SG_ 1716 SRR_FR_DiagReqData3 1;
BA_ "GenSigSendType" SG_ 1716 SRR_FR_DiagReqData4 1;
BA_ "GenSigSendType" SG_ 1716 SRR_FR_DiagReqData5 1;
BA_ "GenSigSendType" SG_ 1716 SRR_FR_DiagReqData6 1;
BA_ "GenSigSendType" SG_ 1716 SRR_FR_DiagReqData7 1;
BA_ "GenSigSendType" SG_ 1716 SRR_FR_DiagReqData8 1;
BA_ "GenSigSendType" SG_ 1716 SRR_FR_DiagReqData9 1;
BA_ "GenSigSendType" SG_ 1716 SRR_FR_DiagReqData10 1;
BA_ "GenSigSendType" SG_ 1716 SRR_FR_DiagReqData11 1;
BA_ "GenSigSendType" SG_ 1716 SRR_FR_DiagReqData12 1;
BA_ "GenSigSendType" SG_ 1716 SRR_FR_DiagReqData13 1;
BA_ "GenSigSendType" SG_ 1716 SRR_FR_DiagReqData14 1;
BA_ "GenSigSendType" SG_ 1716 SRR_FR_DiagReqData15 1;
BA_ "GenSigSendType" SG_ 1716 SRR_FR_DiagReqData16 1;
BA_ "GenSigSendType" SG_ 1716 SRR_FR_DiagReqData17 1;
BA_ "GenSigSendType" SG_ 1716 SRR_FR_DiagReqData18 1;
BA_ "GenSigSendType" SG_ 1716 SRR_FR_DiagReqData19 1;
BA_ "GenSigSendType" SG_ 1716 SRR_FR_DiagReqData20 1;
BA_ "GenSigSendType" SG_ 1716 SRR_FR_DiagReqData21 1;
BA_ "GenSigSendType" SG_ 1716 SRR_FR_DiagReqData22 1;
BA_ "GenSigSendType" SG_ 1716 SRR_FR_DiagReqData23 1;
BA_ "GenSigSendType" SG_ 1716 SRR_FR_DiagReqData24 1;
BA_ "GenSigSendType" SG_ 1716 SRR_FR_DiagReqData25 1;
BA_ "GenSigSendType" SG_ 1716 SRR_FR_DiagReqData26 1;
BA_ "GenSigSendType" SG_ 1716 SRR_FR_DiagReqData27 1;
BA_ "GenSigSendType" SG_ 1716 SRR_FR_DiagReqData28 1;
BA_ "GenSigSendType" SG_ 1716 SRR_FR_DiagReqData29 1;
BA_ "GenSigSendType" SG_ 1716 SRR_FR_DiagReqData30 1;
BA_ "GenSigSendType" SG_ 1716 SRR_FR_DiagReqData31 1;
BA_ "GenSigSendType" SG_ 1716 SRR_FR_DiagReqData32 1;
BA_ "GenSigSendType" SG_ 1716 SRR_FR_DiagReqData33 1;
BA_ "GenSigSendType" SG_ 1716 SRR_FR_DiagReqData34 1;
BA_ "GenSigSendType" SG_ 1716 SRR_FR_DiagReqData35 1;
BA_ "GenSigSendType" SG_ 1716 SRR_FR_DiagReqData36 1;
BA_ "GenSigSendType" SG_ 1716 SRR_FR_DiagReqData37 1;
BA_ "GenSigSendType" SG_ 1716 SRR_FR_DiagReqData38 1;
BA_ "GenSigSendType" SG_ 1716 SRR_FR_DiagReqData39 1;
BA_ "GenSigSendType" SG_ 1716 SRR_FR_DiagReqData40 1;
BA_ "GenSigSendType" SG_ 1716 SRR_FR_DiagReqData41 1;
BA_ "GenSigSendType" SG_ 1716 SRR_FR_DiagReqData42 1;
BA_ "GenSigSendType" SG_ 1716 SRR_FR_DiagReqData43 1;
BA_ "GenSigSendType" SG_ 1716 SRR_FR_DiagReqData44 1;
BA_ "GenSigSendType" SG_ 1716 SRR_FR_DiagReqData45 1;
BA_ "GenSigSendType" SG_ 1716 SRR_FR_DiagReqData46 1;
BA_ "GenSigSendType" SG_ 1716 SRR_FR_DiagReqData47 1;
BA_ "GenSigSendType" SG_ 1716 SRR_FR_DiagReqData48 1;
BA_ "GenSigSendType" SG_ 1716 SRR_FR_DiagReqData49 1;
BA_ "GenSigSendType" SG_ 1716 SRR_FR_DiagReqData50 1;
BA_ "GenSigSendType" SG_ 1716 SRR_FR_DiagReqData51 1;
BA_ "GenSigSendType" SG_ 1716 SRR_FR_DiagReqData52 1;
BA_ "GenSigSendType" SG_ 1716 SRR_FR_DiagReqData53 1;
BA_ "GenSigSendType" SG_ 1716 SRR_FR_DiagReqData54 1;
BA_ "GenSigSendType" SG_ 1716 SRR_FR_DiagReqData55 1;
BA_ "GenSigSendType" SG_ 1716 SRR_FR_DiagReqData56 1;
BA_ "GenSigSendType" SG_ 1716 SRR_FR_DiagReqData57 1;
BA_ "GenSigSendType" SG_ 1716 SRR_FR_DiagReqData58 1;
BA_ "GenSigSendType" SG_ 1716 SRR_FR_DiagReqData59 1;
BA_ "GenSigSendType" SG_ 1716 SRR_FR_DiagReqData60 1;
BA_ "GenSigSendType" SG_ 1716 SRR_FR_DiagReqData61 1;
BA_ "GenSigSendType" SG_ 1716 SRR_FR_DiagReqData62 1;
BA_ "GenSigSendType" SG_ 1716 SRR_FR_DiagReqData63 1;
BA_ "GenSigSendType" SG_ 1588 SRR_FR_DiagRespData0 1;
BA_ "GenSigSendType" SG_ 1588 SRR_FR_DiagRespData1 1;
BA_ "GenSigSendType" SG_ 1588 SRR_FR_DiagRespData2 1;
BA_ "GenSigSendType" SG_ 1588 SRR_FR_DiagRespData3 1;
BA_ "GenSigSendType" SG_ 1588 SRR_FR_DiagRespData4 1;
BA_ "GenSigSendType" SG_ 1588 SRR_FR_DiagRespData5 1;
BA_ "GenSigSendType" SG_ 1588 SRR_FR_DiagRespData6 1;
BA_ "GenSigSendType" SG_ 1588 SRR_FR_DiagRespData7 1;
BA_ "GenSigSendType" SG_ 1588 SRR_FR_DiagRespData8 1;
BA_ "GenSigSendType" SG_ 1588 SRR_FR_DiagRespData9 1;
BA_ "GenSigSendType" SG_ 1588 SRR_FR_DiagRespData10 1;
BA_ "GenSigSendType" SG_ 1588 SRR_FR_DiagRespData11 1;
BA_ "GenSigSendType" SG_ 1588 SRR_FR_DiagRespData12 1;
BA_ "GenSigSendType" SG_ 1588 SRR_FR_DiagRespData13 1;
BA_ "GenSigSendType" SG_ 1588 SRR_FR_DiagRespData14 1;
BA_ "GenSigSendType" SG_ 1588 SRR_FR_DiagRespData15 1;
BA_ "GenSigSendType" SG_ 1588 SRR_FR_DiagRespData16 1;
BA_ "GenSigSendType" SG_ 1588 SRR_FR_DiagRespData17 1;
BA_ "GenSigSendType" SG_ 1588 SRR_FR_DiagRespData18 1;
BA_ "GenSigSendType" SG_ 1588 SRR_FR_DiagRespData19 1;
BA_ "GenSigSendType" SG_ 1588 SRR_FR_DiagRespData20 1;
BA_ "GenSigSendType" SG_ 1588 SRR_FR_DiagRespData21 1;
BA_ "GenSigSendType" SG_ 1588 SRR_FR_DiagRespData22 1;
BA_ "GenSigSendType" SG_ 1588 SRR_FR_DiagRespData23 1;
BA_ "GenSigSendType" SG_ 1588 SRR_FR_DiagRespData24 1;
BA_ "GenSigSendType" SG_ 1588 SRR_FR_DiagRespData25 1;
BA_ "GenSigSendType" SG_ 1588 SRR_FR_DiagRespData26 1;
BA_ "GenSigSendType" SG_ 1588 SRR_FR_DiagRespData27 1;
BA_ "GenSigSendType" SG_ 1588 SRR_FR_DiagRespData28 1;
BA_ "GenSigSendType" SG_ 1588 SRR_FR_DiagRespData29 1;
BA_ "GenSigSendType" SG_ 1588 SRR_FR_DiagRespData30 1;
BA_ "GenSigSendType" SG_ 1588 SRR_FR_DiagRespData31 1;
BA_ "GenSigSendType" SG_ 1588 SRR_FR_DiagRespData32 1;
BA_ "GenSigSendType" SG_ 1588 SRR_FR_DiagRespData33 1;
BA_ "GenSigSendType" SG_ 1588 SRR_FR_DiagRespData34 1;
BA_ "GenSigSendType" SG_ 1588 SRR_FR_DiagRespData35 1;
BA_ "GenSigSendType" SG_ 1588 SRR_FR_DiagRespData36 1;
BA_ "GenSigSendType" SG_ 1588 SRR_FR_DiagRespData37 1;
BA_ "GenSigSendType" SG_ 1588 SRR_FR_DiagRespData38 1;
BA_ "GenSigSendType" SG_ 1588 SRR_FR_DiagRespData39 1;
BA_ "GenSigSendType" SG_ 1588 SRR_FR_DiagRespData40 1;
BA_ "GenSigSendType" SG_ 1588 SRR_FR_DiagRespData41 1;
BA_ "GenSigSendType" SG_ 1588 SRR_FR_DiagRespData42 1;
BA_ "GenSigSendType" SG_ 1588 SRR_FR_DiagRespData43 1;
BA_ "GenSigSendType" SG_ 1588 SRR_FR_DiagRespData44 1;
BA_ "GenSigSendType" SG_ 1588 SRR_FR_DiagRespData45 1;
BA_ "GenSigSendType" SG_ 1588 SRR_FR_DiagRespData46 1;
BA_ "GenSigSendType" SG_ 1588 SRR_FR_DiagRespData47 1;
BA_ "GenSigSendType" SG_ 1588 SRR_FR_DiagRespData48 1;
BA_ "GenSigSendType" SG_ 1588 SRR_FR_DiagRespData49 1;
BA_ "GenSigSendType" SG_ 1588 SRR_FR_DiagRespData50 1;
BA_ "GenSigSendType" SG_ 1588 SRR_FR_DiagRespData51 1;
BA_ "GenSigSendType" SG_ 1588 SRR_FR_DiagRespData52 1;
BA_ "GenSigSendType" SG_ 1588 SRR_FR_DiagRespData53 1;
BA_ "GenSigSendType" SG_ 1588 SRR_FR_DiagRespData54 1;
BA_ "GenSigSendType" SG_ 1588 SRR_FR_DiagRespData55 1;
BA_ "GenSigSendType" SG_ 1588 SRR_FR_DiagRespData56 1;
BA_ "GenSigSendType" SG_ 1588 SRR_FR_DiagRespData57 1;
BA_ "GenSigSendType" SG_ 1588 SRR_FR_DiagRespData58 1;
BA_ "GenSigSendType" SG_ 1588 SRR_FR_DiagRespData59 1;
BA_ "GenSigSendType" SG_ 1588 SRR_FR_DiagRespData60 1;
BA_ "GenSigSendType" SG_ 1588 SRR_FR_DiagRespData61 1;
BA_ "GenSigSendType" SG_ 1588 SRR_FR_DiagRespData62 1;
BA_ "GenSigSendType" SG_ 1588 SRR_FR_DiagRespData63 1;
BA_ "GenSigSendType" SG_ 1791 OBD_Func_DiagReqData0 1;
BA_ "GenSigSendType" SG_ 1791 OBD_Func_DiagReqData1 1;
BA_ "GenSigSendType" SG_ 1791 OBD_Func_DiagReqData2 1;
BA_ "GenSigSendType" SG_ 1791 OBD_Func_DiagReqData3 1;
BA_ "GenSigSendType" SG_ 1791 OBD_Func_DiagReqData4 1;
BA_ "GenSigSendType" SG_ 1791 OBD_Func_DiagReqData5 1;
BA_ "GenSigSendType" SG_ 1791 OBD_Func_DiagReqData6 1;
BA_ "GenSigSendType" SG_ 1791 OBD_Func_DiagReqData7 1;
